VERSION "HNNBNNNYNNNNNNNNNNNNNNNNNNNNNNNNNNNNNNNNNN/4/%%%/4/'%**4NNN///"

NS_ :

BS_:

BU_: BAP_Tester BCM1 Gateway Klima_MSB Lift_VA VAS_L VAS_R

BO_ 427 ESP_33: 8 Gateway
 SG_ ESP_33_CRC : 0|8@1+ (1,0) [0|255] ""  Vector__XXX
 SG_ ESP_33_BZ : 8|4@1+ (1,0) [0|15] ""  Vector__XXX
 SG_ ESC_AHW_aktiv : 12|3@1+ (1.0,0.0) [0.0|7] ""  BCM1
 SG_ ESC_AHW_nicht_verfuegbar : 15|1@1+ (1.0,0.0) [0.0|1] ""  BCM1
 SG_ ESC_ANB_CM_aktiv : 16|2@1+ (1.0,0.0) [0.0|3] ""  Vector__XXX
 SG_ ESC_ANB_CM_nicht_verfuegbar : 18|1@1+ (1.0,0.0) [0.0|1] ""  Vector__XXX
 SG_ ESC_Warnruck_aktiv : 19|4@1+ (1.0,0.0) [0.0|15] ""  Vector__XXX
 SG_ ESC_Warnruck_nicht_verfuegbar : 23|1@1+ (1.0,0.0) [0.0|1] ""  Vector__XXX
 SG_ ESC_Prefill_aktiv : 24|1@1+ (1.0,0.0) [0.0|1] ""  Vector__XXX
 SG_ ESC_Prefill_nicht_verfuegbar : 25|1@1+ (1.0,0.0) [0.0|1] ""  Vector__XXX
 SG_ ESC_HBA_aktiv : 26|1@1+ (1.0,0.0) [0.0|1] ""  Vector__XXX
 SG_ ESC_HBA_nicht_verfuegbar : 27|1@1+ (1.0,0.0) [0.0|1] ""  Vector__XXX
 SG_ ESC_TSK_SRBM_Anf : 28|1@1+ (1.0,0.0) [0.0|1] ""  Vector__XXX
 SG_ ESC_TSK_SRBM_nicht_verfuegbar : 29|1@1+ (1.0,0.0) [0.0|1] ""  Vector__XXX
 SG_ ESC_Verz_Reg_aktiv : 30|4@1+ (1.0,0.0) [0.0|15] ""  BCM1
 SG_ ESC_Verz_Reg_nicht_verfuegbar : 34|1@1+ (1.0,0.0) [0.0|1] ""  BCM1
 SG_ ESC_Verz_Reg_TB_nicht_verfuegbar : 35|1@1+ (1.0,0.0) [0.0|1] ""  BCM1
 SG_ ESC_Verz_Reg_ZB_nicht_verfuegbar : 36|1@1+ (1.0,0.0) [0.0|1] ""  BCM1
 SG_ ESC_Bremslicht_unplausibel : 37|1@1+ (1.0,0.0) [0.0|1] ""  Vector__XXX
 SG_ ESC_Konsistenz_ACC : 38|1@1+ (1.0,0.0) [0.0|1] ""  Vector__XXX
 SG_ ESC_Konsistenz_AWV : 39|1@1+ (1.0,0.0) [0.0|1] ""  Vector__XXX
 SG_ ESC_Konsistenz_ARA : 40|1@1+ (1.0,0.0) [0.0|1] ""  BCM1
 SG_ ESC_Konsistenz_IPA : 41|1@1+ (1.0,0.0) [0.0|1] ""  BCM1
 SG_ ESC_Konsistenz_FCW : 42|1@1+ (1.0,0.0) [0.0|1] ""  Vector__XXX
 SG_ ESC_Konsistenz_NV : 43|1@1+ (1.0,0.0) [0.0|1] ""  Vector__XXX
 SG_ ESC_Konsistenz_RCTA : 44|1@1+ (1.0,0.0) [0.0|1] ""  Vector__XXX
 SG_ ESC_Konsistenz_TSK : 45|1@1+ (1.0,0.0) [0.0|1] ""  Vector__XXX
 SG_ ESC_Konsistenz_vFGS : 46|1@1+ (1.0,0.0) [0.0|1] ""  Vector__XXX
 SG_ ESC_Konsistenz_STA : 47|1@1+ (1.0,0.0) [0.0|1] ""  Vector__XXX
 SG_ ESC_Fahrer_Bremsdruck_bestimmend : 48|1@1+ (1.0,0.0) [0.0|1] ""  BCM1
 SG_ ESC_Konsistenz_EA : 49|1@1+ (1.0,0.0) [0.0|1] ""  Vector__XXX
 SG_ ESC_Konsistenz_BFF : 50|1@1+ (1.0,0.0) [0.0|1] ""  Vector__XXX
 SG_ ESC_Konsistenz_MKB : 51|1@1+ (1.0,0.0) [0.0|1] ""  Vector__XXX
 SG_ ESC_Verz_ASIL_Verfuegbarkeit : 52|3@1+ (1.0,0.0) [0.0|7] ""  BCM1
 SG_ ESC_Pumpenanlauf_aktiv : 55|1@1+ (1.0,0.0) [0.0|1] ""  Vector__XXX
 SG_ ESC_Konsistenz_AGW : 56|1@1+ (1.0,0.0) [0.0|1] ""  Vector__XXX
 SG_ ESC_Konsistenz_KAS : 57|1@1+ (1.0,0.0) [0.0|1] ""  Vector__XXX
 SG_ ESC_Konsistenz_PCF : 58|1@1+ (1.0,0.0) [0.0|1] ""  Vector__XXX
 SG_ ESC_Konsistenz_FAS_VK : 59|1@1+ (1.0,0.0) [0.0|1] ""  Vector__XXX
 SG_ ESC_Verz_Begrenzung : 60|1@1+ (1.0,0.0) [0.0|1] ""  Vector__XXX
 SG_ ESC_Konsistenz_AWA : 61|1@1+ (1.0,0.0) [0.0|1] ""  Vector__XXX

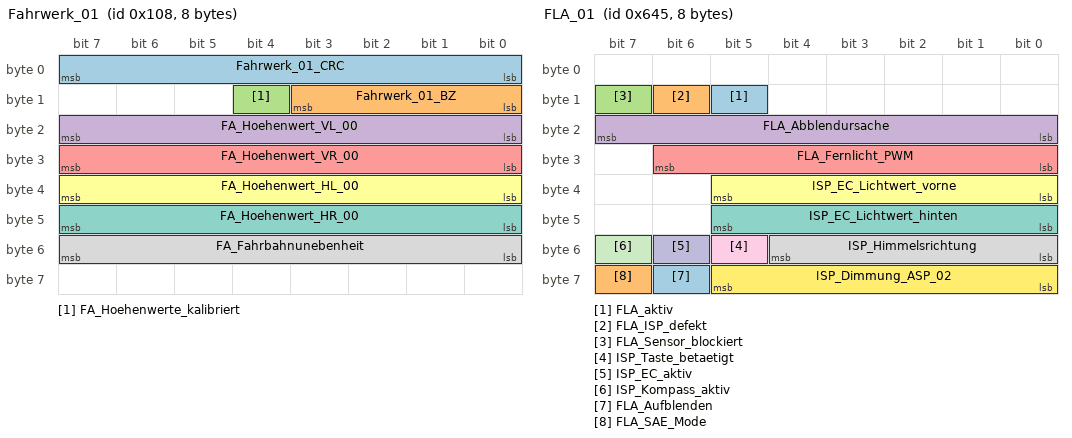
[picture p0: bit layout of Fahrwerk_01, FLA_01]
BO_ 264 Fahrwerk_01: 8 Gateway
 SG_ Fahrwerk_01_CRC : 0|8@1+ (1,0) [0|255] ""  Vector__XXX
 SG_ Fahrwerk_01_BZ : 8|4@1+ (1,0) [0|15] ""  Vector__XXX
 SG_ FA_Hoehenwerte_kalibriert : 12|1@1+ (1.0,0.0) [0.0|1] ""  BCM1,Lift_VA,VAS_L,VAS_R
 SG_ FA_Hoehenwert_VL_00 : 16|8@1+ (1,-127) [-127|126] "Unit_MilliMeter"  BCM1,Lift_VA,VAS_L,VAS_R
 SG_ FA_Hoehenwert_VR_00 : 24|8@1+ (1,-127) [-127|126] "Unit_MilliMeter"  Lift_VA,VAS_L,VAS_R
 SG_ FA_Hoehenwert_HL_00 : 32|8@1+ (1,-127) [-127|126] "Unit_MilliMeter"  BCM1,Lift_VA,VAS_L,VAS_R
 SG_ FA_Hoehenwert_HR_00 : 40|8@1+ (1,-127) [-127|126] "Unit_MilliMeter"  Lift_VA,VAS_L,VAS_R
 SG_ FA_Fahrbahnunebenheit : 48|8@1+ (1,0) [0|253] ""  Vector__XXX

BO_ 429 Fahrwerk_06: 8 Gateway
 SG_ Fahrwerk_06_CRC : 0|8@1+ (1,0) [0|255] ""  Vector__XXX
 SG_ Fahrwerk_06_BZ : 8|4@1+ (1,0) [0|15] ""  Vector__XXX
 SG_ NR_Reglerstatus : 12|4@1+ (1.0,0.0) [0.0|15] ""  BCM1
 SG_ FA_Verstellung_in_Kuerze : 16|1@1+ (1.0,0.0) [0.0|1] ""  Vector__XXX
 SG_ FA_Verstellung_aktiv : 17|1@1+ (1.0,0.0) [0.0|1] ""  Vector__XXX
 SG_ FA_Kompressor_laeuft_in_Kuerze : 18|1@1+ (1.0,0.0) [0.0|1] ""  Vector__XXX
 SG_ FA_Kompressor_laeuft : 19|1@1+ (1.0,0.0) [0.0|1] ""  Vector__XXX
 SG_ NR_Anforderung_v_Begrenzung : 20|2@1+ (1.0,0.0) [0.0|3] ""  Vector__XXX
 SG_ NR_LED_SGN : 22|1@1+ (1.0,0.0) [0.0|1] ""  BCM1
 SG_ NR_LED_TN : 23|1@1+ (1.0,0.0) [0.0|1] ""  BCM1
 SG_ NR_LED_BN : 24|1@1+ (1.0,0.0) [0.0|1] ""  BCM1
 SG_ FA_Absenkung_Fahrzeug : 25|1@1+ (1.0,0.0) [0.0|1] ""  Vector__XXX
 SG_ FA_Anhaengerstatus_intern : 26|3@1+ (1.0,0.0) [0.0|7] ""  Vector__XXX
 SG_ FA_Anhebung_Fahrzeug : 29|1@1+ (1.0,0.0) [0.0|1] ""  Vector__XXX
 SG_ FA_Druckspeicher_verfuegbar : 30|1@1+ (1.0,0.0) [0.0|1] ""  Vector__XXX
 SG_ FA_HAL_Abschaltung : 31|1@1+ (1.0,0.0) [0.0|1] ""  Vector__XXX
 SG_ FA_ESP_Zuschaltung : 32|1@1+ (1.0,0.0) [0.0|1] ""  Vector__XXX
 SG_ NR_LED_HN : 33|1@1+ (1.0,0.0) [0.0|1] ""  BCM1
 SG_ FA_Zwischenniveau : 34|1@1+ (1.0,0.0) [0.0|1] ""  Vector__XXX
 SG_ FA_Systemstatus : 35|1@1+ (1.0,0.0) [0.0|1] ""  Vector__XXX
 SG_ EFP_Soll_FahrPr_HAL : 36|4@1+ (1.0,0.0) [0.0|15] ""  Vector__XXX
 SG_ NR_Kompressor_Strom_02 : 40|8@1+ (0.2,0) [0.0|50.8] "Unit_Amper"  Vector__XXX
 SG_ NR_Kompressor_Temp_Zylinderkopf : 48|8@1+ (1,-40) [-40|213] "Unit_DegreCelsi"  Vector__XXX
 SG_ FA_Signal_Drucksensor : 56|8@1+ (0.1,0) [0.0|25.3] "Unit_Bar"  Vector__XXX

BO_ 1605 FLA_01: 8 Gateway
 SG_ FLA_aktiv : 13|1@1+ (1.0,0.0) [0.0|1] ""  BCM1
 SG_ FLA_ISP_defekt : 14|1@1+ (1.0,0.0) [0.0|1] ""  BCM1
 SG_ FLA_Sensor_blockiert : 15|1@1+ (1.0,0.0) [0.0|1] ""  BCM1
 SG_ FLA_Abblendursache : 16|8@1+ (1.0,0.0) [0.0|255] ""  Vector__XXX
 SG_ FLA_Fernlicht_PWM : 24|7@1+ (1,0) [0|100] "Unit_PerCent"  BCM1
 SG_ ISP_EC_Lichtwert_vorne : 32|6@1+ (1,0) [0|61] "Unit_None"  Vector__XXX
 SG_ ISP_EC_Lichtwert_hinten : 40|6@1+ (1,0) [0|61] "Unit_None"  Vector__XXX
 SG_ ISP_Himmelsrichtung : 48|5@1+ (12,0) [0|348] "Unit_DegreOfArc"  Vector__XXX
 SG_ ISP_Taste_betaetigt : 53|1@1+ (1.0,0.0) [0.0|1] ""  Vector__XXX
 SG_ ISP_EC_aktiv : 54|1@1+ (1.0,0.0) [0.0|1] ""  Vector__XXX
 SG_ ISP_Kompass_aktiv : 55|1@1+ (1.0,0.0) [0.0|1] ""  Vector__XXX
 SG_ ISP_Dimmung_ASP_02 : 56|6@1+ (0.0226,0) [0.0000|1.4012] "Unit_Volt"  Vector__XXX
 SG_ FLA_Aufblenden : 62|1@1+ (1.0,0.0) [0.0|1] ""  BCM1
 SG_ FLA_SAE_Mode : 63|1@1+ (1.0,0.0) [0.0|1] ""  Vector__XXX

BO_ 2589283684 FoD_01: 8 Gateway
 SG_ FoD_Transmission_Info : 60|2@1+ (1.0,0.0) [0.0|3] ""  BCM1
 SG_ FoD_Anz_Funktionsabschaltung : 62|2@1+ (1.0,0.0) [0.0|3] ""  Vector__XXX

BO_ 2549875470 FoD_BCM1_Req: 8 Gateway
 SG_ FoD_BCM1_Req_Data : 0|64@1+ (1.0,0.0) [0.0|18446744073709551615] ""  BCM1

BO_ 2550006542 FoD_BCM1_Resp: 8 BCM1
 SG_ FoD_BCM1_Resp_Data : 0|64@1+ (1.0,0.0) [0.0|18446744073709551615] ""  Gateway

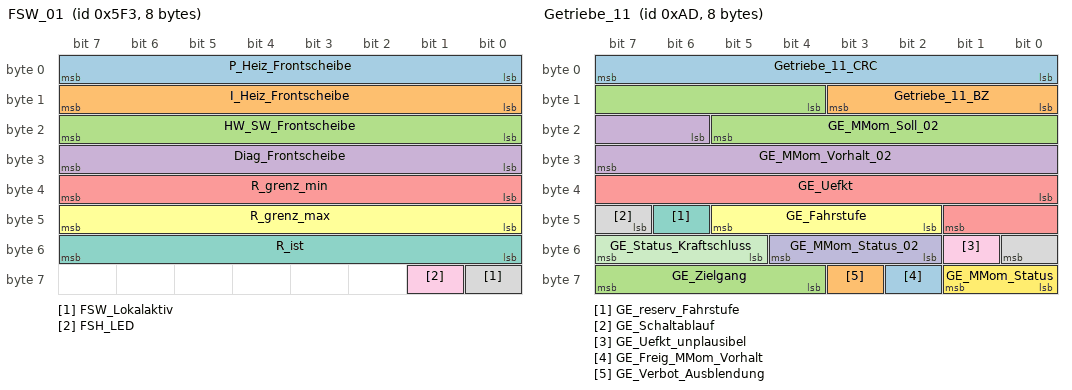
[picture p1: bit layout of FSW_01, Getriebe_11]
BO_ 1523 FSW_01: 8 Gateway
 SG_ P_Heiz_Frontscheibe : 0|8@1+ (10,0) [0|2500] "Unit_Watt"  Vector__XXX
 SG_ I_Heiz_Frontscheibe : 8|8@1+ (0.5,0) [0.0|125.0] "Unit_Amper"  BCM1
 SG_ HW_SW_Frontscheibe : 16|8@1+ (1.0,0.0) [0.0|255] ""  Vector__XXX
 SG_ Diag_Frontscheibe : 24|8@1+ (1.0,0.0) [0.0|255] ""  Vector__XXX
 SG_ R_grenz_min : 32|8@1+ (0.05,0) [0.00|10.00] "Unit_Ohm"  Vector__XXX
 SG_ R_grenz_max : 40|8@1+ (0.05,0) [0.00|10.00] "Unit_Ohm"  Vector__XXX
 SG_ R_ist : 48|8@1+ (0.05,0) [0.00|10.00] "Unit_Ohm"  Vector__XXX
 SG_ FSW_Lokalaktiv : 56|1@1+ (1.0,0.0) [0.0|1] ""  Vector__XXX
 SG_ FSH_LED : 57|1@1+ (1.0,0.0) [0.0|1] ""  Vector__XXX

BO_ 173 Getriebe_11: 8 Gateway
 SG_ Getriebe_11_CRC : 0|8@1+ (1,0) [0|255] ""  Vector__XXX
 SG_ Getriebe_11_BZ : 8|4@1+ (1,0) [0|15] ""  Vector__XXX
 SG_ GE_MMom_Soll_02 : 12|10@1+ (1,-509) [-509|509] ""  Vector__XXX
 SG_ GE_MMom_Vorhalt_02 : 22|10@1+ (1,-509) [-509|509] ""  Vector__XXX
 SG_ GE_Uefkt : 32|10@1+ (0.1,0) [0.0|102.2] ""  Vector__XXX
 SG_ GE_Fahrstufe : 42|4@1+ (1.0,0.0) [0.0|15] ""  BCM1
 SG_ GE_reserv_Fahrstufe : 46|1@1+ (1,0) [0|1] ""  Vector__XXX
 SG_ GE_Schaltablauf : 47|2@1+ (1.0,0.0) [0.0|3] ""  Vector__XXX
 SG_ GE_Uefkt_unplausibel : 49|1@1+ (1.0,0.0) [0.0|1] ""  Vector__XXX
 SG_ GE_MMom_Status_02 : 50|3@1+ (1.0,0.0) [0.0|7] ""  Vector__XXX
 SG_ GE_Status_Kraftschluss : 53|3@1+ (1.0,0.0) [0.0|7] ""  Vector__XXX
 SG_ GE_MMom_Status : 56|2@1+ (1.0,0.0) [0.0|3] ""  Vector__XXX
 SG_ GE_Freig_MMom_Vorhalt : 58|1@1+ (1.0,0.0) [0.0|1] ""  Vector__XXX
 SG_ GE_Verbot_Ausblendung : 59|1@1+ (1.0,0.0) [0.0|1] ""  Vector__XXX
 SG_ GE_Zielgang : 60|4@1+ (1.0,0.0) [0.0|15] ""  BCM1

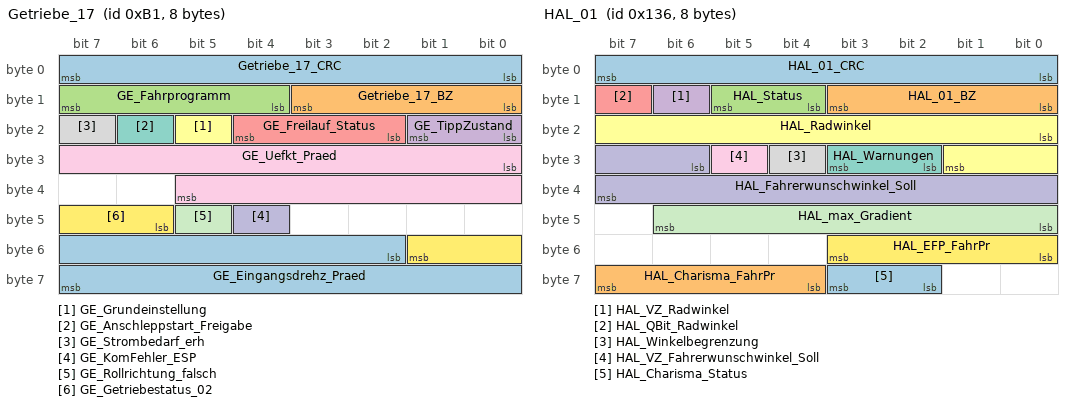
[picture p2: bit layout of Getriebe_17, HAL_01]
BO_ 177 Getriebe_17: 8 Gateway
 SG_ Getriebe_17_CRC : 0|8@1+ (1,0) [0|255] ""  Vector__XXX
 SG_ Getriebe_17_BZ : 8|4@1+ (1,0) [0|15] ""  Vector__XXX
 SG_ GE_Fahrprogramm : 12|4@1+ (1.0,0.0) [0.0|15] ""  Vector__XXX
 SG_ GE_TippZustand : 16|2@1+ (1.0,0.0) [0.0|3] ""  Vector__XXX
 SG_ GE_Freilauf_Status : 18|3@1+ (1.0,0.0) [0.0|7] ""  BCM1,Klima_MSB
 SG_ GE_Grundeinstellung : 21|1@1+ (1.0,0.0) [0.0|1] ""  Vector__XXX
 SG_ GE_Anschleppstart_Freigabe : 22|1@1+ (1.0,0.0) [0.0|1] ""  Vector__XXX
 SG_ GE_Strombedarf_erh : 23|1@1+ (1.0,0.0) [0.0|1] ""  Vector__XXX
 SG_ GE_Uefkt_Praed : 24|14@1+ (0.008,0) [0.000|131.056] ""  Vector__XXX
 SG_ GE_KomFehler_ESP : 44|1@1+ (1.0,0.0) [0.0|1] ""  Vector__XXX
 SG_ GE_Rollrichtung_falsch : 45|1@1+ (1.0,0.0) [0.0|1] ""  Vector__XXX
 SG_ GE_Getriebestatus_02 : 46|4@1+ (1.0,0.0) [0.0|15] ""  Vector__XXX
 SG_ GE_Eingangsdrehz_Praed : 50|14@1+ (1,0) [0|16381] "Unit_MinutInver"  Vector__XXX

BO_ 310 HAL_01: 8 Gateway
 SG_ HAL_01_CRC : 0|8@1+ (1,0) [0|255] ""  BCM1
 SG_ HAL_01_BZ : 8|4@1+ (1,0) [0|15] ""  BCM1
 SG_ HAL_Status : 12|2@1+ (1.0,0.0) [0.0|3] ""  BCM1
 SG_ HAL_VZ_Radwinkel : 14|1@1+ (1.0,0.0) [0.0|1] ""  BCM1
 SG_ HAL_QBit_Radwinkel : 15|1@1+ (1.0,0.0) [0.0|1] ""  BCM1
 SG_ HAL_Radwinkel : 16|10@1+ (0.01,0) [0.00|10.19] "Unit_DegreOfArc"  BCM1
 SG_ HAL_Warnungen : 26|2@1+ (1.0,0.0) [0.0|3] ""  Vector__XXX
 SG_ HAL_Winkelbegrenzung : 28|1@1+ (1.0,0.0) [0.0|1] ""  Vector__XXX
 SG_ HAL_VZ_Fahrerwunschwinkel_Soll : 29|1@1+ (1.0,0.0) [0.0|1] ""  BCM1
 SG_ HAL_Fahrerwunschwinkel_Soll : 30|10@1+ (0.01,0) [0.00|10.21] "Unit_DegreOfArc"  BCM1
 SG_ HAL_max_Gradient : 40|7@1+ (0.1,0) [0.0|12.5] "Unit_DegreOfArcPerSecon"  BCM1
 SG_ HAL_EFP_FahrPr : 48|4@1+ (1.0,0.0) [0.0|15] ""  Vector__XXX
 SG_ HAL_Charisma_Status : 58|2@1+ (1.0,0.0) [0.0|3] ""  Vector__XXX
 SG_ HAL_Charisma_FahrPr : 60|4@1+ (1.0,0.0) [0.0|15] ""  Vector__XXX

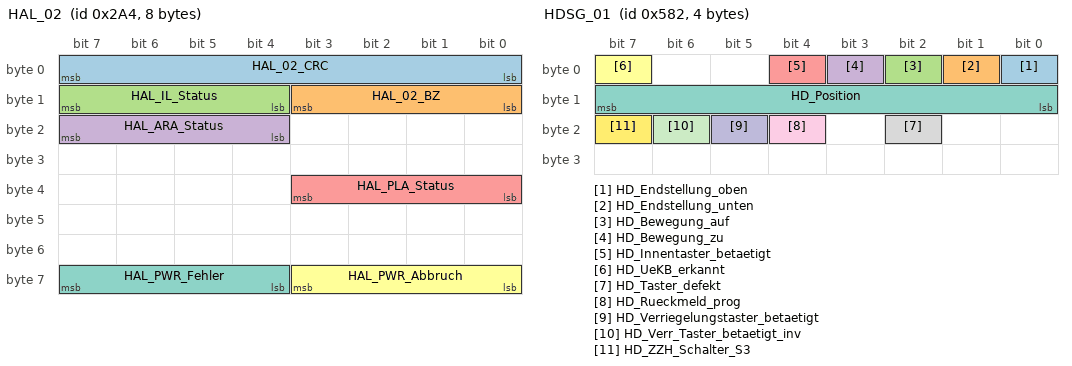
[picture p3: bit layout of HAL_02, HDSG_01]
BO_ 676 HAL_02: 8 Gateway
 SG_ HAL_02_CRC : 0|8@1+ (1,0) [0|255] ""  BCM1
 SG_ HAL_02_BZ : 8|4@1+ (1,0) [0|15] ""  BCM1
 SG_ HAL_IL_Status : 12|4@1+ (1.0,0.0) [0.0|15] ""  Vector__XXX
 SG_ HAL_ARA_Status : 20|4@1+ (1.0,0.0) [0.0|15] ""  BCM1
 SG_ HAL_PLA_Status : 32|4@1+ (1.0,0.0) [0.0|15] ""  BCM1
 SG_ HAL_PWR_Abbruch : 56|4@1+ (1.0,0.0) [0.0|15] ""  BCM1
 SG_ HAL_PWR_Fehler : 60|4@1+ (1.0,0.0) [0.0|15] ""  BCM1

BO_ 1410 HDSG_01: 4 Gateway
 SG_ HD_Endstellung_oben : 0|1@1+ (1.0,0.0) [0.0|1] ""  BCM1
 SG_ HD_Endstellung_unten : 1|1@1+ (1.0,0.0) [0.0|1] ""  BCM1
 SG_ HD_Bewegung_auf : 2|1@1+ (1.0,0.0) [0.0|1] ""  Vector__XXX
 SG_ HD_Bewegung_zu : 3|1@1+ (1.0,0.0) [0.0|1] ""  BCM1,Klima_MSB
 SG_ HD_Innentaster_betaetigt : 4|1@1+ (1.0,0.0) [0.0|1] ""  Vector__XXX
 SG_ HD_UeKB_erkannt : 7|1@1+ (1.0,0.0) [0.0|1] ""  Vector__XXX
 SG_ HD_Position : 8|8@1+ (1,0) [0|100] "Unit_PerCent"  BCM1
 SG_ HD_Taster_defekt : 18|1@1+ (1.0,0.0) [0.0|1] ""  Vector__XXX
 SG_ HD_Rueckmeld_prog : 20|1@1+ (1.0,0.0) [0.0|1] ""  Vector__XXX
 SG_ HD_Verriegelungstaster_betaetigt : 21|1@1+ (1.0,0.0) [0.0|1] ""  Vector__XXX
 SG_ HD_Verr_Taster_betaetigt_inv : 22|1@1+ (1.0,0.0) [0.0|1] ""  Vector__XXX
 SG_ HD_ZZH_Schalter_S3 : 23|1@1+ (1.0,0.0) [0.0|1] ""  Vector__XXX

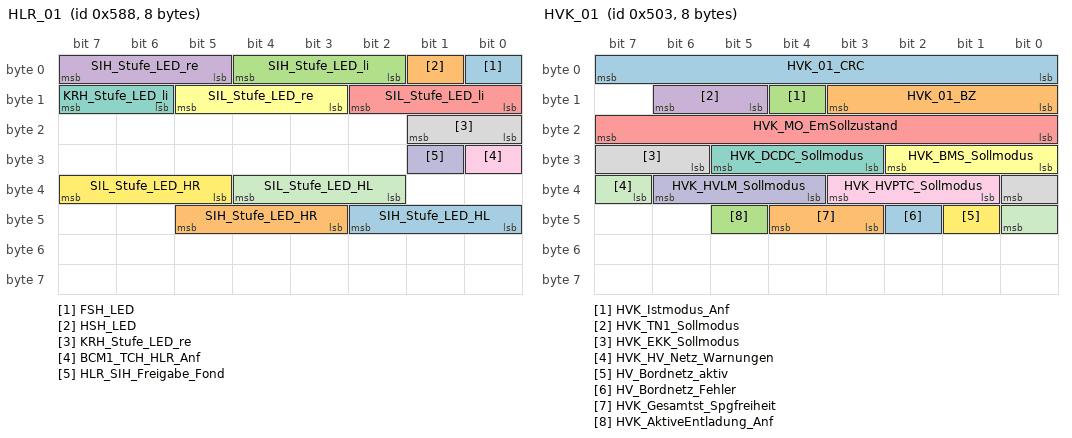
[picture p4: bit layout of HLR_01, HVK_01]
BO_ 1416 HLR_01: 8 BCM1
 SG_ FSH_LED : 0|1@1+ (1.0,0.0) [0.0|1] ""  Gateway
 SG_ HSH_LED : 1|1@1+ (1.0,0.0) [0.0|1] ""  Gateway
 SG_ SIH_Stufe_LED_li : 2|3@1+ (1.0,0.0) [0.0|7] ""  Gateway,Klima_MSB
 SG_ SIH_Stufe_LED_re : 5|3@1+ (1.0,0.0) [0.0|7] ""  Gateway,Klima_MSB
 SG_ SIL_Stufe_LED_li : 8|3@1+ (1.0,0.0) [0.0|7] ""  Gateway,Klima_MSB
 SG_ SIL_Stufe_LED_re : 11|3@1+ (1.0,0.0) [0.0|7] ""  Gateway,Klima_MSB
 SG_ KRH_Stufe_LED_li : 14|2@1+ (1.0,0.0) [0.0|3] ""  Gateway,Klima_MSB
 SG_ KRH_Stufe_LED_re : 16|2@1+ (1.0,0.0) [0.0|3] ""  Gateway,Klima_MSB
 SG_ BCM1_TCH_HLR_Anf : 24|1@1+ (1.0,0.0) [0.0|1] ""  Gateway
 SG_ HLR_SIH_Freigabe_Fond : 25|1@1+ (1.0,0.0) [0.0|1] ""  Gateway
 SG_ SIL_Stufe_LED_HL : 34|3@1+ (1.0,0.0) [0.0|7] ""  Gateway,Klima_MSB
 SG_ SIL_Stufe_LED_HR : 37|3@1+ (1.0,0.0) [0.0|7] ""  Gateway,Klima_MSB
 SG_ SIH_Stufe_LED_HL : 40|3@1+ (1.0,0.0) [0.0|7] ""  Gateway,Klima_MSB
 SG_ SIH_Stufe_LED_HR : 43|3@1+ (1.0,0.0) [0.0|7] ""  Gateway,Klima_MSB

BO_ 1016 HLR_02: 8 Gateway
 SG_ HLR_FlHz_Freigabe_Ruhesitz : 14|2@1+ (1.0,0.0) [0.0|3] ""  BCM1
 SG_ HLR_FlHz_Freigabe_VR : 16|2@1+ (1.0,0.0) [0.0|3] ""  BCM1
 SG_ HLR_FlHz_Freigabe_VL : 18|2@1+ (1.0,0.0) [0.0|3] ""  BCM1
 SG_ HLR_FlHz_Freigabe_HR : 20|2@1+ (1.0,0.0) [0.0|3] ""  BCM1
 SG_ HLR_FlHz_Freigabe_HL : 22|2@1+ (1.0,0.0) [0.0|3] ""  BCM1
 SG_ HLR_TCH_Freigabe : 24|1@1+ (1.0,0.0) [0.0|1] ""  BCM1
 SG_ HLR_SIH_Freigabe_Fond : 25|1@1+ (1.0,0.0) [0.0|1] ""  BCM1
 SG_ HLR_Sp_Heizung_Freigabe_BT : 26|1@1+ (1.0,0.0) [0.0|1] ""  Vector__XXX
 SG_ HLR_Sp_Heizung_Freigabe_FT : 27|1@1+ (1.0,0.0) [0.0|1] ""  Vector__XXX
 SG_ HLR_KRH_Freigabe_VL : 28|2@1+ (1.0,0.0) [0.0|3] ""  BCM1
 SG_ HLR_KRH_Freigabe_VR : 30|2@1+ (1.0,0.0) [0.0|3] ""  BCM1
 SG_ HLR_SIH_Freigabe_VL : 32|2@1+ (1.0,0.0) [0.0|3] ""  BCM1
 SG_ HLR_SIH_Freigabe_VR : 34|2@1+ (1.0,0.0) [0.0|3] ""  BCM1
 SG_ HLR_SIH_Freigabe_HL : 36|2@1+ (1.0,0.0) [0.0|3] ""  BCM1,Klima_MSB
 SG_ HLR_SIH_Freigabe_HR : 38|2@1+ (1.0,0.0) [0.0|3] ""  BCM1,Klima_MSB
 SG_ HLR_SIL_Freigabe_VL : 40|2@1+ (1.0,0.0) [0.0|3] ""  BCM1
 SG_ HLR_SIL_Freigabe_VR : 42|2@1+ (1.0,0.0) [0.0|3] ""  BCM1
 SG_ HLR_SIL_Freigabe_HL : 44|2@1+ (1.0,0.0) [0.0|3] ""  BCM1,Klima_MSB
 SG_ HLR_SIL_Freigabe_HR : 46|2@1+ (1.0,0.0) [0.0|3] ""  BCM1,Klima_MSB
 SG_ HLR_FSH_Freigabe : 48|6@1+ (20,0) [20|1240] "Unit_Watt"  BCM1,Klima_MSB
 SG_ HLR_HSH_Freigabe : 54|1@1+ (1.0,0.0) [0.0|1] ""  Vector__XXX
 SG_ HLR_LRH_Freigabe : 55|1@1+ (1.0,0.0) [0.0|1] ""  Vector__XXX
 SG_ HLR_PTC_linear_Freigabe : 56|6@1+ (50,0) [0|3100] "Unit_Watt"  BCM1,Klima_MSB
 SG_ HLR_PTC_Freigabe : 62|2@1+ (1.0,0.0) [0.0|3] ""  BCM1

BO_ 1283 HVK_01: 8 Gateway
 SG_ HVK_01_CRC : 0|8@1+ (1,0) [0|255] ""  Vector__XXX
 SG_ HVK_01_BZ : 8|4@1+ (1,0) [0|15] ""  Vector__XXX
 SG_ HVK_Istmodus_Anf : 12|1@1+ (1.0,0.0) [0.0|1] ""  Vector__XXX
 SG_ HVK_TN1_Sollmodus : 13|2@1+ (1.0,0.0) [0.0|3] ""  Vector__XXX
 SG_ HVK_MO_EmSollzustand : 16|8@1+ (1.0,0.0) [0.0|255] ""  Vector__XXX
 SG_ HVK_BMS_Sollmodus : 24|3@1+ (1.0,0.0) [0.0|7] ""  Vector__XXX
 SG_ HVK_DCDC_Sollmodus : 27|3@1+ (1.0,0.0) [0.0|7] ""  Vector__XXX
 SG_ HVK_EKK_Sollmodus : 30|3@1+ (1.0,0.0) [0.0|7] ""  Vector__XXX
 SG_ HVK_HVPTC_Sollmodus : 33|3@1+ (1.0,0.0) [0.0|7] ""  BCM1,Klima_MSB
 SG_ HVK_HVLM_Sollmodus : 36|3@1+ (1.0,0.0) [0.0|7] ""  Vector__XXX
 SG_ HVK_HV_Netz_Warnungen : 39|2@1+ (1.0,0.0) [0.0|3] ""  Vector__XXX
 SG_ HV_Bordnetz_aktiv : 41|1@1+ (1.0,0.0) [0.0|1] ""  Vector__XXX
 SG_ HV_Bordnetz_Fehler : 42|1@1+ (1.0,0.0) [0.0|1] ""  Vector__XXX
 SG_ HVK_Gesamtst_Spgfreiheit : 43|2@1+ (1.0,0.0) [0.0|3] ""  Vector__XXX
 SG_ HVK_AktiveEntladung_Anf : 45|1@1+ (1.0,0.0) [0.0|1] ""  Vector__XXX

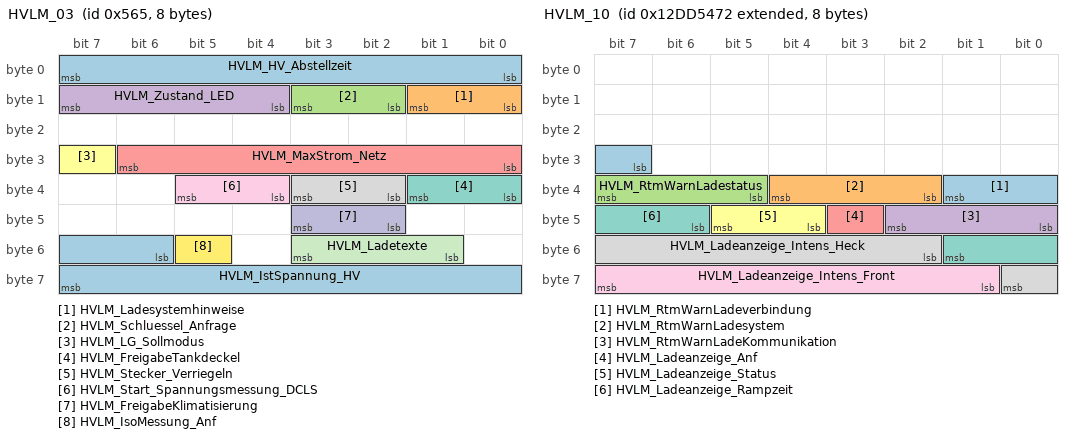
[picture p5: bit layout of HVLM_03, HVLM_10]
BO_ 1381 HVLM_03: 8 Gateway
 SG_ HVLM_HV_Abstellzeit : 0|8@1+ (4,0) [0|1012] "Unit_Minut"  Vector__XXX
 SG_ HVLM_Ladesystemhinweise : 8|2@1+ (1.0,0.0) [0.0|3] ""  Vector__XXX
 SG_ HVLM_Schluessel_Anfrage : 10|2@1+ (1.0,0.0) [0.0|3] ""  Vector__XXX
 SG_ HVLM_Zustand_LED : 12|4@1+ (1.0,0.0) [0.0|15] ""  Vector__XXX
 SG_ HVLM_MaxStrom_Netz : 24|7@1+ (0.5,0) [0.0|62.5] "Unit_Amper"  Vector__XXX
 SG_ HVLM_LG_Sollmodus : 31|1@1+ (1.0,0.0) [0.0|1] ""  Vector__XXX
 SG_ HVLM_FreigabeTankdeckel : 32|2@1+ (1.0,0.0) [0.0|3] ""  Vector__XXX
 SG_ HVLM_Stecker_Verriegeln : 34|2@1+ (1.0,0.0) [0.0|3] ""  Vector__XXX
 SG_ HVLM_Start_Spannungsmessung_DCLS : 36|2@1+ (1.0,0.0) [0.0|3] ""  Vector__XXX
 SG_ HVLM_FreigabeKlimatisierung : 42|2@1+ (1.0,0.0) [0.0|3] ""  BCM1,Klima_MSB
 SG_ HVLM_Ladetexte : 49|3@1+ (1.0,0.0) [0.0|7] ""  Vector__XXX
 SG_ HVLM_IsoMessung_Anf : 53|1@1+ (1.0,0.0) [0.0|1] ""  Vector__XXX
 SG_ HVLM_IstSpannung_HV : 54|10@1+ (1,0) [0|1021] "Unit_Volt"  Vector__XXX

BO_ 1340 HVLM_04: 8 Gateway
 SG_ HVLM_04_CRC : 0|8@1+ (1,0) [0|255] ""  Vector__XXX
 SG_ HVLM_04_BZ : 8|4@1+ (1,0) [0|15] ""  Vector__XXX
 SG_ HVLM_STH_Betriebsmodus : 12|3@1+ (1.0,0.0) [0.0|7] ""  BCM1,Klima_MSB
 SG_ HVLM_Standklima_Timer_Status : 15|1@1+ (1.0,0.0) [0.0|1] ""  BCM1,Klima_MSB
 SG_ HVLM_HVEM_MaxLeistung : 16|9@1+ (50,0) [0|25450] "Unit_Watt"  Vector__XXX
 SG_ HVLM_Status_Netz : 25|1@1+ (1.0,0.0) [0.0|1] ""  Vector__XXX
 SG_ HVLM_Ladeart : 27|2@1+ (1.0,0.0) [0.0|3] ""  Vector__XXX
 SG_ HVLM_VK_STH_Einsatz : 29|3@1+ (1.0,0.0) [0.0|7] ""  BCM1
 SG_ HVLM_VK_Modus : 32|2@1+ (1.0,0.0) [0.0|3] ""  BCM1,Klima_MSB
 SG_ HVLM_IstModus_02 : 34|2@1+ (1.0,0.0) [0.0|3] ""  Vector__XXX
 SG_ HVLM_HV_Anf : 36|2@1+ (1.0,0.0) [0.0|3] ""  Vector__XXX
 SG_ HVLM_Fehlerstatus : 38|3@1+ (1.0,0.0) [0.0|7] ""  Vector__XXX
 SG_ HVLM_Anforderung_HMS : 41|3@1+ (1.0,0.0) [0.0|7] ""  Vector__XXX
 SG_ HVLM_Parken_beibehalten_HMS : 44|2@1+ (1.0,0.0) [0.0|3] ""  Vector__XXX
 SG_ HVLM_AWC_Sollmodus : 48|3@1+ (1.0,0.0) [0.0|7] ""  Vector__XXX
 SG_ HVLM_Stecker_Status : 51|2@1+ (1.0,0.0) [0.0|3] ""  Vector__XXX
 SG_ HVLM_LadeAnforderung : 53|3@1+ (1.0,0.0) [0.0|7] ""  Vector__XXX
 SG_ HVLM_MaxBatLadestromHV : 56|8@1+ (1,0) [0|253] "Unit_Amper"  Vector__XXX

BO_ 2589283485 HVLM_08: 8 Gateway
 SG_ HVLM_BattKond_Anf : 55|3@1+ (1.0,0.0) [0.0|7] ""  Vector__XXX
 SG_ HVLM_Dauer_Klima_02 : 58|6@1+ (1,0) [0|60] "Unit_Minut"  BCM1,Klima_MSB

BO_ 2463978610 HVLM_10: 8 Gateway
 SG_ HVLM_RtmWarnLadeverbindung : 31|3@1+ (1.0,0.0) [0.0|7] ""  Vector__XXX
 SG_ HVLM_RtmWarnLadesystem : 34|3@1+ (1.0,0.0) [0.0|7] ""  Vector__XXX
 SG_ HVLM_RtmWarnLadestatus : 37|3@1+ (1.0,0.0) [0.0|7] ""  Vector__XXX
 SG_ HVLM_RtmWarnLadeKommunikation : 40|3@1+ (1.0,0.0) [0.0|7] ""  Vector__XXX
 SG_ HVLM_Ladeanzeige_Anf : 43|1@1+ (1.0,0.0) [0.0|1] ""  BCM1
 SG_ HVLM_Ladeanzeige_Status : 44|2@1+ (1.0,0.0) [0.0|3] ""  BCM1
 SG_ HVLM_Ladeanzeige_Rampzeit : 46|4@1+ (50,0) [0|750] "Unit_MilliSecon"  Vector__XXX
 SG_ HVLM_Ladeanzeige_Intens_Heck : 50|7@1+ (1,0) [0|100] "Unit_PerCent"  Vector__XXX
 SG_ HVLM_Ladeanzeige_Intens_Front : 57|7@1+ (1,0) [0|100] "Unit_PerCent"  Vector__XXX

BO_ 1524 Innenlicht_11: 8 BCM1
 SG_ IL_Dimmung_V_Tuerkontur : 0|8@1+ (1,0) [0|100] "Unit_PerCent"  Gateway
 SG_ IL_Dimmung_H_Tuerkontur : 8|8@1+ (1,0) [0|100] "Unit_PerCent"  Gateway
 SG_ IL_Dimmung_Tuerinnengriff : 16|8@1+ (1,0) [0|100] "Unit_PerCent"  Gateway
 SG_ IL_Dimmung_Umfeldbel : 24|8@1+ (1,0) [0|100] "Unit_PerCent"  Gateway
 SG_ IL_Bel_FS_Ausstieg : 32|1@1+ (1.0,0.0) [0.0|1] ""  Gateway
 SG_ IL_Bel_BFS_Ausstieg : 33|1@1+ (1.0,0.0) [0.0|1] ""  Gateway
 SG_ IL_Bel_HFS_Ausstieg : 34|1@1+ (1.0,0.0) [0.0|1] ""  Gateway
 SG_ IL_Bel_HBFS_Ausstieg : 35|1@1+ (1.0,0.0) [0.0|1] ""  Gateway
 SG_ BCM1_Innenlicht_gedimmt_V : 36|1@1+ (1.0,0.0) [0.0|1] ""  Gateway
 SG_ BCM1_Innenlicht_gedimmt_H : 37|1@1+ (1.0,0.0) [0.0|1] ""  Gateway
 SG_ IL_Innenlicht_aktiv : 38|1@1+ (1.0,0.0) [0.0|1] ""  Gateway
 SG_ IL_Klemme_30G_aktiv : 39|1@1+ (1.0,0.0) [0.0|1] ""  Gateway
 SG_ BCM1_DI_Rampe_Innenlicht : 40|1@1+ (1.0,0.0) [0.0|1] ""  Gateway
 SG_ BCM1_DI_Rampe_Leselicht : 41|1@1+ (1.0,0.0) [0.0|1] ""  Gateway
 SG_ BCM1_Innenlicht_H : 42|1@1+ (1.0,0.0) [0.0|1] ""  Gateway
 SG_ BCM1_Innenlicht_V : 43|1@1+ (1.0,0.0) [0.0|1] ""  Gateway
 SG_ BCM1_Leselicht_Anf_hl : 44|1@1+ (1.0,0.0) [0.0|1] ""  Gateway
 SG_ BCM1_Leselicht_Anf_hr : 45|1@1+ (1.0,0.0) [0.0|1] ""  Gateway
 SG_ BCM1_Leselicht_Anf_vl : 46|1@1+ (1.0,0.0) [0.0|1] ""  Gateway
 SG_ BCM1_Leselicht_Anf_vr : 47|1@1+ (1.0,0.0) [0.0|1] ""  Gateway
 SG_ BCM1_Leuchten_Aus : 48|1@1+ (1.0,0.0) [0.0|1] ""  Gateway
 SG_ AMB_Charisma_FahrPr : 49|4@1+ (1.0,0.0) [0.0|15] ""  Gateway
 SG_ AMB_Charisma_Status : 53|2@1+ (1.0,0.0) [0.0|3] ""  Gateway
 SG_ IL_Dimmung_Lautspr : 56|8@1+ (1,0) [0|100] "Unit_PerCent"  Gateway

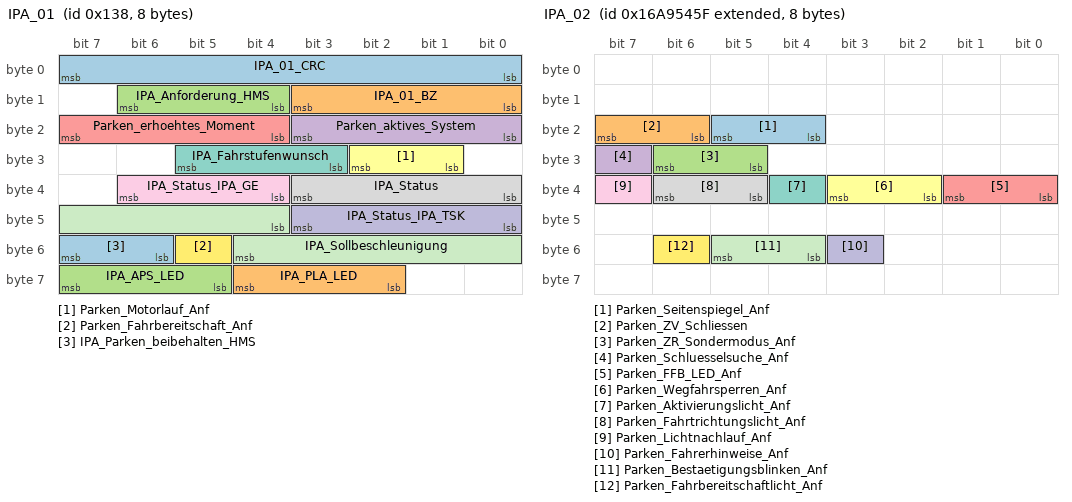
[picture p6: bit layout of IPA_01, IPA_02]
BO_ 312 IPA_01: 8 Gateway
 SG_ IPA_01_CRC : 0|8@1+ (1,0) [0|255] ""  Vector__XXX
 SG_ IPA_01_BZ : 8|4@1+ (1,0) [0|15] ""  Vector__XXX
 SG_ IPA_Anforderung_HMS : 12|3@1+ (1.0,0.0) [0.0|7] ""  Vector__XXX
 SG_ Parken_aktives_System : 16|4@1+ (1.0,0.0) [0.0|15] ""  BCM1
 SG_ Parken_erhoehtes_Moment : 20|4@1+ (1.0,0.0) [0.0|15] ""  Vector__XXX
 SG_ Parken_Motorlauf_Anf : 25|2@1+ (1.0,0.0) [0.0|3] ""  Vector__XXX
 SG_ IPA_Fahrstufenwunsch : 27|3@1+ (1.0,0.0) [0.0|7] ""  Vector__XXX
 SG_ IPA_Status : 32|4@1+ (1.0,0.0) [0.0|15] ""  Vector__XXX
 SG_ IPA_Status_IPA_GE : 36|3@1+ (1.0,0.0) [0.0|7] ""  Vector__XXX
 SG_ IPA_Status_IPA_TSK : 40|4@1+ (1.0,0.0) [0.0|15] ""  BCM1
 SG_ IPA_Sollbeschleunigung : 44|9@1+ (0.01,-4.11) [-4.10|1.00] "Unit_MeterPerSeconSquar"  Vector__XXX
 SG_ Parken_Fahrbereitschaft_Anf : 53|1@1+ (1.0,0.0) [0.0|1] ""  Vector__XXX
 SG_ IPA_Parken_beibehalten_HMS : 54|2@1+ (1.0,0.0) [0.0|3] ""  Vector__XXX
 SG_ IPA_PLA_LED : 58|3@1+ (1.0,0.0) [0.0|7] ""  BCM1
 SG_ IPA_APS_LED : 61|3@1+ (1.0,0.0) [0.0|7] ""  BCM1

BO_ 2527679583 IPA_02: 8 Gateway
 SG_ Parken_Seitenspiegel_Anf : 20|2@1+ (1.0,0.0) [0.0|3] ""  VAS_L,VAS_R
 SG_ Parken_ZV_Schliessen : 22|2@1+ (1.0,0.0) [0.0|3] ""  Vector__XXX
 SG_ Parken_ZR_Sondermodus_Anf : 29|2@1+ (1.0,0.0) [0.0|3] ""  Vector__XXX
 SG_ Parken_Schluesselsuche_Anf : 31|1@1+ (1.0,0.0) [0.0|1] ""  Vector__XXX
 SG_ Parken_FFB_LED_Anf : 32|2@1+ (1.0,0.0) [0.0|3] ""  Vector__XXX
 SG_ Parken_Wegfahrsperren_Anf : 34|2@1+ (1.0,0.0) [0.0|3] ""  Vector__XXX
 SG_ Parken_Aktivierungslicht_Anf : 36|1@1+ (1.0,0.0) [0.0|1] ""  BCM1
 SG_ Parken_Fahrtrichtungslicht_Anf : 37|2@1+ (1.0,0.0) [0.0|3] ""  BCM1
 SG_ Parken_Lichtnachlauf_Anf : 39|1@1+ (1.0,0.0) [0.0|1] ""  BCM1
 SG_ Parken_Fahrerhinweise_Anf : 51|1@1+ (1.0,0.0) [0.0|1] ""  Vector__XXX
 SG_ Parken_Bestaetigungsblinken_Anf : 52|2@1+ (1.0,0.0) [0.0|3] ""  BCM1
 SG_ Parken_Fahrbereitschaftlicht_Anf : 54|1@1+ (1.0,0.0) [0.0|1] ""  BCM1

BO_ 1806 ISO_BCM1_Req: 8 Gateway
 SG_ ISO_BCM1_Req_Data : 0|64@1+ (1.0,0.0) [0.0|18446744073709551615] ""  BCM1

BO_ 1912 ISO_BCM1_Resp: 8 BCM1
 SG_ ISO_BCM1_Resp_Data : 0|64@1+ (1.0,0.0) [0.0|18446744073709551615] ""  Gateway

BO_ 1792 ISO_Funktionaler_Req_All: 8 Gateway
 SG_ ISO_ALL_01_Req_Data : 0|64@1+ (1.0,0.0) [0.0|18446744073709551615] ""  BCM1,Klima_MSB,Lift_VA,VAS_L,VAS_R

BO_ 1862 ISO_Klima_Req: 8 Gateway
 SG_ ISO_Klima_Req_Data : 0|64@1+ (1.0,0.0) [0.0|18446744073709551615] ""  Klima_MSB

BO_ 1968 ISO_Klima_Resp: 8 Klima_MSB
 SG_ ISO_Klima_Resp_Data : 0|64@1+ (1.0,0.0) [0.0|18446744073709551615] ""  Gateway

BO_ 1881 ISO_Lift_Req: 8 Gateway
 SG_ ISO_Lift_Req_Data : 0|64@1+ (1,0) [0|18446744073709551615] "Unit_None"  Lift_VA

BO_ 1987 ISO_Lift_Resp: 8 Lift_VA
 SG_ ISO_Lift_Resp_Data : 0|64@1+ (1,0) [0|18446744073709551615] "Unit_None"  Gateway

BO_ 2549874818 ISOx_LCM_L_Req: 8 Gateway
 SG_ ISO_LCM_L_Req_Data : 0|64@1+ (1.0,0.0) [0.0|18446744073709551615] ""  BCM1

BO_ 2550005890 ISOx_LCM_L_Resp: 8 BCM1
 SG_ ISO_LCM_L_Resp_Data : 0|64@1+ (1.0,0.0) [0.0|18446744073709551615] ""  Gateway

BO_ 2549874819 ISOx_LCM_R_Req: 8 Gateway
 SG_ ISO_LCM_R_Req_Data : 0|64@1+ (1.0,0.0) [0.0|18446744073709551615] ""  BCM1

BO_ 2550005891 ISOx_LCM_R_Resp: 8 BCM1
 SG_ ISO_LCM_R_Resp_Data : 0|64@1+ (1.0,0.0) [0.0|18446744073709551615] ""  Gateway

BO_ 2549874838 ISOx_LED_LM_L_Req: 8 Gateway
 SG_ ISO_LED_LM_L_Req_Data : 0|64@1+ (1.0,0.0) [0.0|18446744073709551615] ""  BCM1

BO_ 2550005910 ISOx_LED_LM_L_Resp: 8 BCM1
 SG_ ISO_LED_LM_L_Resp_Data : 0|64@1+ (1.0,0.0) [0.0|18446744073709551615] ""  Gateway

BO_ 2549874839 ISOx_LED_LM_R_Req: 8 Gateway
 SG_ ISO_LED_LM_R_Req_Data : 0|64@1+ (1.0,0.0) [0.0|18446744073709551615] ""  BCM1

BO_ 2550005911 ISOx_LED_LM_R_Resp: 8 BCM1
 SG_ ISO_LED_LM_R_Resp_Data : 0|64@1+ (1.0,0.0) [0.0|18446744073709551615] ""  Gateway

BO_ 2549874884 ISOx_VAS_L_Req: 8 Gateway
 SG_ ISO_VAS_L_Req_Data : 0|64@1+ (1,0) [0|18446744073709551615] ""  VAS_L

BO_ 2550005956 ISOx_VAS_L_Resp: 8 VAS_L
 SG_ ISO_VAS_L_Resp_Data : 0|64@1+ (1,0) [0|18446744073709551615] ""  Gateway

BO_ 2549874885 ISOx_VAS_R_Req: 8 Gateway
 SG_ ISO_VAS_R_Req_Data : 0|64@1+ (1,0) [0|18446744073709551615] ""  VAS_R

BO_ 2550005957 ISOx_VAS_R_Resp: 8 VAS_R
 SG_ ISO_VAS_R_Resp_Data : 0|64@1+ (1,0) [0|18446744073709551615] ""  Gateway

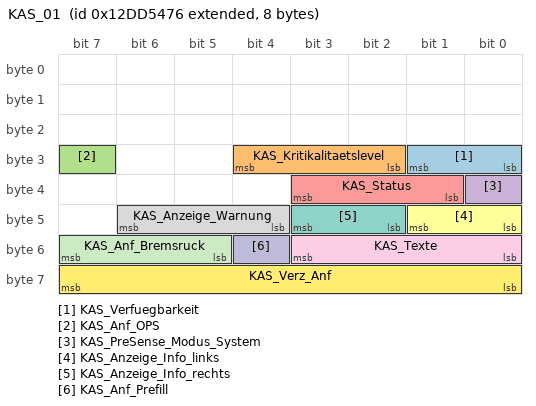
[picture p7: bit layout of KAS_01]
BO_ 2463978614 KAS_01: 8 Gateway
 SG_ KAS_Verfuegbarkeit : 24|2@1+ (1.0,0.0) [0.0|3] ""  Vector__XXX
 SG_ KAS_Kritikalitaetslevel : 26|3@1+ (1.0,0.0) [0.0|7] ""  BCM1
 SG_ KAS_Anf_OPS : 31|1@1+ (1.0,0.0) [0.0|1] ""  BCM1
 SG_ KAS_PreSense_Modus_System : 32|1@1+ (1.0,0.0) [0.0|1] ""  Vector__XXX
 SG_ KAS_Status : 33|3@1+ (1.0,0.0) [0.0|7] ""  Vector__XXX
 SG_ KAS_Anzeige_Info_links : 40|2@1+ (1.0,0.0) [0.0|3] ""  Vector__XXX
 SG_ KAS_Anzeige_Info_rechts : 42|2@1+ (1.0,0.0) [0.0|3] ""  Vector__XXX
 SG_ KAS_Anzeige_Warnung : 44|3@1+ (1.0,0.0) [0.0|7] ""  Vector__XXX
 SG_ KAS_Texte : 48|4@1+ (1.0,0.0) [0.0|15] ""  Vector__XXX
 SG_ KAS_Anf_Prefill : 52|1@1+ (1.0,0.0) [0.0|1] ""  Vector__XXX
 SG_ KAS_Anf_Bremsruck : 53|3@1+ (1.0,0.0) [0.0|7] ""  Vector__XXX
 SG_ KAS_Verz_Anf : 56|8@1+ (0.079,-19.987) [-19.987|0.000] "Unit_MeterPerSeconSquar"  Vector__XXX

BO_ 497 Kessy_11: 8 Gateway
 SG_ KY_IDG_in_Reichweite : 12|1@1+ (1.0,0.0) [0.0|1] ""  Vector__XXX
 SG_ KY_Auf_Taste : 13|1@1+ (1.0,0.0) [0.0|1] ""  Vector__XXX
 SG_ KY_HDF_Taste : 14|1@1+ (1.0,0.0) [0.0|1] ""  BCM1
 SG_ KY_Panik_Taste : 15|1@1+ (1.0,0.0) [0.0|1] ""  Vector__XXX
 SG_ KY_Zu_Taste : 16|1@1+ (1.0,0.0) [0.0|1] ""  Vector__XXX
 SG_ KY_FT_Entriegelung_Autorisiert : 17|1@1+ (1.0,0.0) [0.0|1] ""  BCM1
 SG_ KY_FT_Verriegelung_Autorisiert : 18|1@1+ (1.0,0.0) [0.0|1] ""  Vector__XXX
 SG_ KY_BT_Entriegelung_Autorisiert : 19|1@1+ (1.0,0.0) [0.0|1] ""  Vector__XXX
 SG_ KY_BT_Verriegelung_Autorisiert : 20|1@1+ (1.0,0.0) [0.0|1] ""  Vector__XXX
 SG_ KY_HFS_Entriegelung_Autorisiert : 21|1@1+ (1.0,0.0) [0.0|1] ""  Vector__XXX
 SG_ KY_HFS_Verriegelung_Autorisiert : 22|1@1+ (1.0,0.0) [0.0|1] ""  Vector__XXX
 SG_ KY_HBFS_Entriegelung_Autorisiert : 23|1@1+ (1.0,0.0) [0.0|1] ""  Vector__XXX
 SG_ KY_HBFS_Verriegelung_Autorisiert : 24|1@1+ (1.0,0.0) [0.0|1] ""  Vector__XXX
 SG_ KY_Front_Entr_Autorisiert : 25|1@1+ (1.0,0.0) [0.0|1] ""  BCM1
 SG_ KY_Front_Verr_Autorisiert : 26|1@1+ (1.0,0.0) [0.0|1] ""  BCM1
 SG_ KY_HD_Entriegelung_Autorisiert : 27|1@1+ (1.0,0.0) [0.0|1] ""  Vector__XXX
 SG_ KY_HD_Verriegelung_Autorisiert : 28|1@1+ (1.0,0.0) [0.0|1] ""  Vector__XXX
 SG_ KY_Bereich : 29|3@1+ (1.0,0.0) [0.0|7] ""  BCM1
 SG_ KY_Position : 32|3@1+ (1.0,0.0) [0.0|7] ""  BCM1
 SG_ KY_ZV_Signatur : 35|11@1+ (1,0) [0|2047] ""  Vector__XXX
 SG_ Schluesselnr_Personalisierung : 46|4@1+ (1.0,0.0) [0.0|15] ""  BCM1,Klima_MSB,VAS_L,VAS_R
 SG_ FFB_FDF_Taste : 50|1@1+ (1.0,0.0) [0.0|1] ""  BCM1
 SG_ FFB_Joker_Taste : 51|1@1+ (1.0,0.0) [0.0|1] ""  BCM1
 SG_ FFB_Park_Taste : 52|1@1+ (1.0,0.0) [0.0|1] ""  Vector__XXX
 SG_ FFB_Remotestart_Taste : 53|1@1+ (1.0,0.0) [0.0|1] ""  Vector__XXX
 SG_ FBS_Aktivierung_Pilot_Parken : 54|1@1+ (1.0,0.0) [0.0|1] ""  Vector__XXX
 SG_ KY_Schluessel_im_Fzg : 55|1@1+ (1.0,0.0) [0.0|1] ""  Vector__XXX
 SG_ KY_EasyClose_Abbruch : 56|1@1+ (1.0,0.0) [0.0|1] ""  Vector__XXX
 SG_ KY_EasyClose_Status : 57|3@1+ (1.0,0.0) [0.0|7] ""  Vector__XXX
 SG_ KY_HD_Auffahrt : 60|1@1+ (1.0,0.0) [0.0|1] ""  Vector__XXX
 SG_ KY_HD_Zufahrt : 61|1@1+ (1.0,0.0) [0.0|1] ""  Vector__XXX
 SG_ KY_LKL_1_Autorisierung : 62|1@1+ (1.0,0.0) [0.0|1] ""  Vector__XXX
 SG_ KY_LKL_2_Autorisierung : 63|1@1+ (1.0,0.0) [0.0|1] ""  Vector__XXX

CM_ BO_ 264 "ab MLBevo mit CRC";
CM_ BO_ 1416 "Heizleistungsregelung";
CM_ BO_ 1016 "Heizleistungsregelung 
MLBevo (NVEM im Gateway)";
CM_ BO_ 1340 "CAN-Botschaft";
CM_ BO_ 2527679583 "ehemals ZFAS_01";
CM_ BO_ 2549874818 "Lichtsteuerung links am Frontlicht-CAN";
CM_ BO_ 2550005890 "Lichtsteuerung links am Frontlicht-CAN";
CM_ BO_ 2549874819 "Lichtsteuerung rechts am Frontlicht-CAN";
CM_ BO_ 2550005891 "Lichtsteuerung rechts am Frontlicht-CAN";
CM_ BO_ 2549874838 "Lichtsteuerung links am Frontlicht-CAN";
CM_ BO_ 2550005910 "Lichtsteuerung links am Frontlicht-CAN";
CM_ BO_ 2549874839 "Lichtsteuerung rechts am Frontlicht-CAN";
CM_ BO_ 2550005911 "Lichtsteuerung rechts am Frontlicht-CAN";

CM_ SG_ 427 ESC_AHW_aktiv "Rueckmeldung Anhaltewegregelung aktiv
";
CM_ SG_ 427 ESC_AHW_nicht_verfuegbar "Rueckmeldung Anhaltewegregelung nicht verfuegbar
";
CM_ SG_ 427 ESC_ANB_CM_aktiv "Rueckmeldung ANB_CM (Autom_Notbremsung_Collision_Mitigation) aktiv
";
CM_ SG_ 427 ESC_ANB_CM_nicht_verfuegbar "Rueckmeldung ANB_CM nicht verfuegbar
";
CM_ SG_ 427 ESC_Bremslicht_unplausibel "Plausibilisierung der Rückmeldeinformation von BCM/AAG bezüglich Anforderung ESC_Bremslicht";
CM_ SG_ 427 ESC_Fahrer_Bremsdruck_bestimmend "Das Signal zeigt an, dass der Fahrer Bremsdruck bestimmend ist";
CM_ SG_ 427 ESC_HBA_aktiv "Rueckmeldung HBA (hydraulischer Bremsassistent) aktiv";
CM_ SG_ 427 ESC_HBA_nicht_verfuegbar "Rueckmeldung HBA (hydraulischer Bremsassistent) nicht verfuegbar";
CM_ SG_ 427 ESC_Konsistenz_ACC "Rueckmeldung Konsistenz der ACC Botschaften";
CM_ SG_ 427 ESC_Konsistenz_AGW "Rückmeldung Konsistenz der AGW-Botschaft an das ESC.";
CM_ SG_ 427 ESC_Konsistenz_ARA "Rueckmeldung Konsistenz der ARA Botschaften";
CM_ SG_ 427 ESC_Konsistenz_AWA "Rueckmeldung Konsistenz der AWA-Botschaften";
CM_ SG_ 427 ESC_Konsistenz_AWV "Rueckmeldung Konsistenz der AWV Botschaften";
CM_ SG_ 427 ESC_Konsistenz_BFF "Rückmeldung Konsistenz der Verzögerungsanforderung an das ESC-Steuergerät der Funktion 'Bremsen im freien Fahren' vom PDC_PLA_ARA-Steuergerät";
CM_ SG_ 427 ESC_Konsistenz_EA "Rueckmeldung Konsistenz der EA Botschaften (HCA)";
CM_ SG_ 427 ESC_Konsistenz_FAS_VK "Rueckmeldung Konsistenz der FAS_VK Botschaften";
CM_ SG_ 427 ESC_Konsistenz_FCW "Rueckmeldung Konsistenz der FCW Botschaften";
CM_ SG_ 427 ESC_Konsistenz_IPA "Rueckmeldung Konsistenz der IPA Botschaften";
CM_ SG_ 427 ESC_Konsistenz_KAS "Rückmeldung Konsistenz für Kreuzungsassistent-Anforderungen";
CM_ SG_ 427 ESC_Konsistenz_MKB "Rückmeldung Konsistenz für MKB-Verzögerungsanfoorderung";
CM_ SG_ 427 ESC_Konsistenz_NV "Rueckmeldung Konsistenz der NightVision Botschaften";
CM_ SG_ 427 ESC_Konsistenz_PCF "Rückmeldung der Konsistenz der PCF-Anforderungen";
CM_ SG_ 427 ESC_Konsistenz_RCTA "Rueckmeldung Konsistenz der RCTA (Rear Cross Traffic Alert) Botschaften";
CM_ SG_ 427 ESC_Konsistenz_STA "Rueckmeldung Konsistenz der STA Botschaften";
CM_ SG_ 427 ESC_Konsistenz_TSK "Rueckmeldung Konsistenz der TSK Botschaften";
CM_ SG_ 427 ESC_Konsistenz_vFGS "Rueckmeldung Konsistenz der vFGS Botschaften";
CM_ SG_ 427 ESC_Prefill_aktiv "Rueckmeldung Prefill aktiv";
CM_ SG_ 427 ESC_Prefill_nicht_verfuegbar "Rueckmeldung Prefill nicht verfuegbar";
CM_ SG_ 427 ESC_Pumpenanlauf_aktiv "Bestätigung der Durchführung eines Vorsteuerpumpenanlaufes";
CM_ SG_ 427 ESC_TSK_SRBM_Anf "Quittierung fuer TSK (SRBM=Summenradbremsmoment) Anforderung";
CM_ SG_ 427 ESC_TSK_SRBM_nicht_verfuegbar "Rueckmeldung TSK (SRBM= Summenradbremsmoment) nicht verfuegbar";
CM_ SG_ 427 ESC_Verz_ASIL_Verfuegbarkeit "Gibt die Verfuegbarkeit der VZM-Regelung an, wobei folgende Zustaende beruecksichtigt werden:
-Nicht Verfuegbarkeit wegen Sonderbetriebszustaenden (z.B. Produktionsmodus)
-ueber VZM abgebaute Fahrzeuggeschwindigkeit bei Verzögerungen a>5m/s², wobei gilt";
CM_ SG_ 427 ESC_Verz_Begrenzung "Rückmeldung angeforderte Verzögerung oder Summenradbremsmoment wird begrenzt umgesetzt  ";
CM_ SG_ 427 ESC_Verz_Reg_aktiv "Rueckmeldung Verzoegerungsregelung aktiv";
CM_ SG_ 427 ESC_Verz_Reg_nicht_verfuegbar "Rueckmeldung Verzoegerungsregelung nicht verfuegbar";
CM_ SG_ 427 ESC_Verz_Reg_TB_nicht_verfuegbar "Rueckmeldung Verzoegerungsregelung (Teilbremsung) nicht verfuegbar";
CM_ SG_ 427 ESC_Verz_Reg_ZB_nicht_verfuegbar "Rueckmeldung Verzoegerungsregelung ZB (Zielbremsung) nicht verfuegbar";
CM_ SG_ 427 ESC_Warnruck_aktiv "Rueckmeldung Warnruck aktiv";
CM_ SG_ 427 ESC_Warnruck_nicht_verfuegbar "Rueckmeldung Warnruck nicht verfuegbar";
CM_ SG_ 427 ESP_33_BZ "Botschaft asynchron geroutet. Zählerwert kann springen.";
CM_ SG_ 427 ESP_33_CRC "Für MLB:
'Berechnung siehe Lastenheft 'Kommunikationsabsicherung für FlexRay und CAN''

Ab MQB und MLBevo:
'Berechnung siehe Lastenheft 'End-to-End Kommunikationsabsicherung''

Endwerte siehe Begleitdokument 'S-PDU Kennungsfolgen'";

CM_ SG_ 264 FA_Fahrbahnunebenheit "Informationsbeschreibung des Fahrbahnzustandes";
CM_ SG_ 264 FA_Hoehenwert_HL_00 "Aktueller Höhenwert (kalibriert) Hinten Links; ungefiltertes Signal
Einheit, Offset und Faktor sind abhänig von 'FA_Hoehenwert_kalibriert'

Achtung:
Wird im AUDI B8 nicht bedient";
CM_ SG_ 264 FA_Hoehenwert_HR_00 "Aktueller Höhenwert (kalibriert) Hinten Rechts; ungefiltertes Signal
Einheit, Offset und Faktor sind abhänig von 'FA_Hoehenwert_kalibriert'

Achtung:
Wird im AUDI B8 nicht bedient";
CM_ SG_ 264 FA_Hoehenwert_VL_00 "Aktueller Höhenwert (kalibriert) Vorne Links; ungefiltertes Signal
Einheit, Offset und Faktor sind abhänig von 'FA_Hoehenwert_kalibriert'

Achtung:
Wird im AUDI B8 nicht bedient";
CM_ SG_ 264 FA_Hoehenwert_VR_00 "Aktueller Höhenwert (kalibriert) Vorne Rechts; ungefiltertes Signal
Einheit, Offset und Faktor sind abhänig von 'FA_Hoehenwert_kalibriert'

Achtung:
Wird im AUDI B8 nicht bedient";
CM_ SG_ 264 FA_Hoehenwerte_kalibriert "Legt fest, wie die Höhensensorwerte interpretiert werden müssen. Umschaltung kalibrierte Höhenwerte / Rohsignale in Byte 3-6

Achtung:
Im AUDI B8 Konstante: 0x1. D.h. es werden nur Rohwerte bedient!
Im AUDI D4 Konstante: 0x0. D.h. es werden nur Millim";
CM_ SG_ 264 Fahrwerk_01_CRC "Für MLB:
'Berechnung siehe Lastenheft 'Kommunikationsabsicherung für FlexRay und CAN''

Ab MQB und MLBevo:
'Berechnung siehe Lastenheft 'End-to-End Kommunikationsabsicherung''

Endwerte siehe Begleitdokument 'S-PDU Kennungsfolgen'";

CM_ SG_ 429 EFP_Soll_FahrPr_HAL "Anforderung einer Zwangsumschaltung des Fahrprogramms der HAL durch EFP";
CM_ SG_ 429 FA_Absenkung_Fahrzeug "Nächsttieferes Niveau wird angefahren (Absenken). Dieses Bit wird immer gesetzt in Verbindung mit einer Auswahl aus den Bits FA_Verstellung_xx.";
CM_ SG_ 429 FA_Anhaengerstatus_intern "Anzeige des SG-internen Verarbeitungsstatus Anhängers";
CM_ SG_ 429 FA_Anhebung_Fahrzeug "Nächsthöheres Niveau wird angefahren (Anheben). Dieses Bit wird immer gesetzt in Verbindung mit einer Auswahl aus den Bits FA_Verstellung_xx.";
CM_ SG_ 429 FA_Druckspeicher_verfuegbar "Bit ist gesetzt, wenn eine Regelung aus dem Druckspeicher möglich ist.";
CM_ SG_ 429 FA_ESP_Zuschaltung "Zwangsweise Aktivierung der ESP-Funktionalität wird angefordert auch bei Passivtastung";
CM_ SG_ 429 FA_HAL_Abschaltung "Anforderung einer Zwangs-Deaktivierung der HAL wegen zu geringem
Radfreigang durch Luftfeder oder Schneekettenbetrieb.";
CM_ SG_ 429 FA_Kompressor_laeuft "Zustand der Kompressoransteuerung";
CM_ SG_ 429 FA_Kompressor_laeuft_in_Kuerze "Kompressorlauf steht unmittelbar bevor. Das Bit wird immer gesetzt in Verbindung mit den Bits FA_Anhebung_Fahrzeug oder FA_Absenkung_Fahrzeug.";
CM_ SG_ 429 FA_Signal_Drucksensor "Signalwert des Drucksensors im Magnetventilblock";
CM_ SG_ 429 FA_Systemstatus "Bit wird gesetzt, wenn interne Funktionsprüfung i.O. und System generell funktionsfähig ist.";
CM_ SG_ 429 FA_Verstellung_aktiv "Verstellung ist aktiv. Dieses Bit wird immer gesetzt in Verbindung mit den Bits FA_Anhebung_Fahrzeug oder FA_Absenkung_Fahrzeug.";
CM_ SG_ 429 FA_Verstellung_in_Kuerze "Dieses Bit wird gesetzt, wenn eine Verstellung unmittelbar bevorsteht.";
CM_ SG_ 429 FA_Zwischenniveau "Dieses Bit wird gesetzt, wenn die Fahrzeughöhe zwischen 2 definierten Niveaus liegt, z.B.. während des Regelvorgangs.";
CM_ SG_ 429 Fahrwerk_06_BZ "Botschaft asynchron geroutet. Zählerwert kann springen.";
CM_ SG_ 429 Fahrwerk_06_CRC "Ab MQB und MLBevo:
'Berechnung siehe Lastenheft 'End-to-End Kommunikationsabsicherung''

Endwerte siehe Begleitdokument 'S-PDU Kennungsfolgen'";
CM_ SG_ 429 NR_Anforderung_v_Begrenzung "Anforderung einer v-Begrenzung an das Motor-SG.";
CM_ SG_ 429 NR_Kompressor_Strom_02 "Gemessener Strom am Kompressors.";
CM_ SG_ 429 NR_Kompressor_Temp_Zylinderkopf "Gemessene Temperatur im Zylinderkopf des Luftfeder-Kompressors";
CM_ SG_ 429 NR_LED_BN "Statusrückmeldung der eingestellten Fahrzeughöhe Beladungsniveau bzw. Tasterbetätigung Anheben/Absenken.";
CM_ SG_ 429 NR_LED_HN "Statusrückmeldung der eingestellten Fahrzeughöhe Hochniveau
";
CM_ SG_ 429 NR_LED_SGN "Statusrückmeldung der eingestellten Fahrzeughöhe Sondergeländeniveau bzw. Tasterbetätigung Anheben/Absenken.";
CM_ SG_ 429 NR_LED_TN "Statusrückmeldung der eingestellten Fahrzeughöhe Tiefniveau";
CM_ SG_ 429 NR_Reglerstatus "Anzeige des auszuregelnden Sollniveaus (wird bei Beginn der Regelung auf entsprechenden Wert gesetzt).";

CM_ SG_ 1605 FLA_Abblendursache "FLA Abblendursache
(20ms Task)";
CM_ SG_ 1605 FLA_aktiv "FLA aktiv  (200ms Task)";
CM_ SG_ 1605 FLA_Aufblenden "FLA Aufblenden (20ms Task)";
CM_ SG_ 1605 FLA_Fernlicht_PWM "FLA PWM Vorgabe Fernlicht
(20ms Task)";
CM_ SG_ 1605 FLA_ISP_defekt "FLA Innenspiegel defekt
interner Fehler  (200ms Task)";
CM_ SG_ 1605 FLA_SAE_Mode "Rückmeldung an den Fahrer, über Wechsel in den SAE Modus --> wird nur für den amerikanischen Markt benötigt.";
CM_ SG_ 1605 FLA_Sensor_blockiert "FLA Sensor blockiert
Sichtbeeinträchtigung CMOS-Kamera  (200ms Task)";
CM_ SG_ 1605 ISP_Dimmung_ASP_02 "Dimmwertvorgabe für Aussenspiegel
Es wird 1:1 die Spannung am Innenspiegel nach außen übertragen.";
CM_ SG_ 1605 ISP_EC_aktiv "Status Innenspiegel (EC-Spiegel)
";
CM_ SG_ 1605 ISP_EC_Lichtwert_hinten "Innenspiegel: Lichtwert hinten
";
CM_ SG_ 1605 ISP_EC_Lichtwert_vorne "Innenspiegel: Lichtwert vorne
";
CM_ SG_ 1605 ISP_Himmelsrichtung "Himmelsrichtung Kompass im EC Spiegel
Wertebereich 0-29 (12°-Schritte, 0-348°)
";
CM_ SG_ 1605 ISP_Kompass_aktiv "Status Kompass Innenspiegel
";
CM_ SG_ 1605 ISP_Taste_betaetigt "ISP Taste betätigt
(200ms Task)";

CM_ SG_ 2589283684 FoD_Anz_Funktionsabschaltung "Signal triggert Aufschaltung eines Popups, um dem Fahrer die Abschaltung einer Funktion zu melden.";
CM_ SG_ 2589283684 FoD_Transmission_Info "Mit dem Signal zeigt der FoD-Master allen FoD-Slaves den Beginn und das Ende eines Freischaltuebertragungszykluses (FS-ID-Zyklus) an.";

CM_ SG_ 2549875470 FoD_BCM1_Req_Data "Function on demand request an BCM1";

CM_ SG_ 2550006542 FoD_BCM1_Resp_Data "Function on demand response vom BCM1";

CM_ SG_ 1523 Diag_Frontscheibe "Übertragung der Fehler:
    Bit 1: Unterer Grenzwert unterschritten
    Bit 2: Oberer Grenzwert ueberschritten
    Bit 3: zur Zeit nicht pruefbar
    Bit 4: Unterbrechung
    Bit 5: El. Fehler im Stromkreis 
    Bit 6: El. Fehler im Stromkreis 
   ";
CM_ SG_ 1523 FSH_LED "LED Ansteuerung Frontscheibenheizung";
CM_ SG_ 1523 HW_SW_Frontscheibe "HW/SW-Version:
    HW Bit 1..4
    SW Bit 5..8";
CM_ SG_ 1523 I_Heiz_Frontscheibe "Stromaufnahme Frontscheibenheizung";
CM_ SG_ 1523 P_Heiz_Frontscheibe "aktuelle Leistungsaufnahme";
CM_ SG_ 1523 R_grenz_max "Oberer Widerstandsgrenzwert";
CM_ SG_ 1523 R_grenz_min "Unterer Widerstandsgrenzwert";
CM_ SG_ 1523 R_ist "aktueller Widerstandsmesswert";

CM_ SG_ 173 GE_Fahrstufe "Fahrprogramm des Getriebes

Hinweis: Zwischenstellung '0x0' darf nur für Zustandswechsel P/R, R/N, N/D ausgegeben werden, nicht für D/S oder D/Tippgasse wegen Abschaltkriterium GRA/ACC";
CM_ SG_ 173 GE_Freig_MMom_Vorhalt "Freigabe für die Anforderung einer Momentenreserve durch das Getriebe über das Signal
MLB: GE_MMom_Vorhalt
MQB/MLBevo: GE_MMom_Vorhalt_02";
CM_ SG_ 173 GE_MMom_Soll_02 "Momenteneingriff an den Motor.
Fordert vom MSG eine kurzfristige Reduzierung oder Anhebung des Moments.
Das Signal ist nur gültig in Kombination mit GE_MMom_Status (bei MQB) bzw. GE_MMom_Status_02 (bei MLBevo).

Achtung:
Einheitenloser Wert! Faktor i";
CM_ SG_ 173 GE_MMom_Status "Qualifiziert 
MLB: GE_MMom_Soll
MQB: GE_MMom_Soll_02";
CM_ SG_ 173 GE_MMom_Status_02 "Das Signal qualifiziert GE_MMom_Soll_02 und gibt an, wie der Wert aus GE_MMom_soll – vorbehaltlich der Umsetzbarkeit aufgrund motorinterner Restriktionen – umgesetzt werden soll.
Werte:
0= kein Eingriff
1=   absoluter reduzierender Eingriff auf Gesamt ";
CM_ SG_ 173 GE_MMom_Vorhalt_02 "Anforderung einer Momentenreserve durch das Getriebe, gilt nur mit Freigabe durch 
GE_Freig_MMom_Vorhalt

Anforderung wird als Absolut-Wert umgesetzt, nicht als Relativ-Wert/Delta zum aktuellen Ist-Moment (d. h. eine Momentenreserve wird eingestellt, w";
CM_ SG_ 173 GE_reserv_Fahrstufe "reserviert, falls künftig Erweiterung von GE_Fahrstufe nötig";
CM_ SG_ 173 GE_Schaltablauf "Das Signal zeigt den aktuellen Status eines Schaltvorgangs.

Bei Signal = 0 liegt kein Schaltvorgang vor.
Bei Signal =2 liegt die Befüllphase der zuschaltenden Kupplung bzw. 
                      die Vorbereitungsphase dazu vor.

Mit den unterschie";
CM_ SG_ 173 GE_Status_Kraftschluss "Zeigt den Ist-Status des Kraftschlusses im Getriebe.
(Anmerkung: meist wird damit der Zustand des Anfahrelements beschrieben, d.h. bei DL/DQ die Kupplung;  bei AQ/AL der Wandler incl. Überbrückungskupplung)
0 = offen, kein Kraftschluss
1 = offen mit Kr";
CM_ SG_ 173 GE_Uefkt "Übertragungsfunktion des Getriebes
Drehzahlverhältnis = Eingangsdrehzahl / Ausgangsdrehzahl

AL: Wandlerverstärkung x Drehzahlverhältnis
VL: Drehzahlverhältnis
DL: Drehzahlverhältnis der aktiven und kraftschluß führenden Welle zum Abtrieb, bei Schalt";
CM_ SG_ 173 GE_Uefkt_unplausibel "Das Signal darf nur im Reku-Manager in Hybrid-Varianten verwendet werden.
Zeigt an, ob die Plausibilisierung Momenten-Verhältnis zu Drehzahl-Verhältnis i.O. ist.
Ein gesetztes Signal meldet eine unplausible GE_Uefkt bzw. GE_Uefkt_02.";
CM_ SG_ 173 GE_Verbot_Ausblendung "Verbot Einspritzausblendung für komfortable Schaltungen";
CM_ SG_ 173 GE_Zielgang "VL-Getriebe:
Signalisiert den Zielgang im manuellen Modus während eines Schaltvorgangs bzw. die momentane simulierte Gangstufe wenn kein Schaltvorgang aktiv ist. In den Fahrprogrammen 'D' und 'S' ist die Übersetzung variabel und somit wird dauerhaft 'Ist";
CM_ SG_ 173 Getriebe_11_BZ "Botschaftszähler
Botschaft asynchron geroutet. Zählerwert kann springen.";
CM_ SG_ 173 Getriebe_11_CRC "Für MLB:
'Berechnung siehe Lastenheft 'Kommunikationsabsicherung für FlexRay und CAN''

Ab MQB und MLBevo:
'Berechnung siehe Lastenheft 'End-to-End Kommunikationsabsicherung''

Endwerte siehe Begleitdokument 'S-PDU Kennungsfolgen'";

CM_ SG_ 177 GE_Anschleppstart_Freigabe "Bilden einer Schleppstartfreigabe aus Fahrdynamiksicht. Schleppstartabbruch bei kritischer Fahrzeugstabilität";
CM_ SG_ 177 GE_Eingangsdrehz_Praed "prädizierte Getriebe-Eingangsdrehzahl (während Schaltungen kann die voraussichtliche Drehzahl am Ende der Schaltung gezeigt werden)";
CM_ SG_ 177 GE_Fahrprogramm "Signalisiert das Fahrprogramm  im Bezug auf
die Fahrstufe des Getriebes.

Audi/MQB:
Offroad

Bentley:
Snow
Gravel
Mud_Ruts
Sand_Dune

Touareg:
Offroad
Snow";
CM_ SG_ 177 GE_Freilauf_Status "Freilauf-Status-Signal vom Frailauf-Master an aktive Freilauf-Teilnehmer. In diesem Signal zeigt der Freilauf-Master an, welchen aktuellen Status die Freilauf-Betriebsstrategie hat.";
CM_ SG_ 177 GE_Getriebestatus_02 "Signalisierung von speziellen Betriebszuständen des Getriebes:
1= Rennstartvorbereitung; genutzt im MSG zum Aufbau einer Momentenreserve, in Allrad und Quersperre (GQS)
2= Rennstart; nicht genutzt im MSG
3= Anfahrt; genutzt im MSG zur Umschaltung des F";
CM_ SG_ 177 GE_Grundeinstellung "Grundeinstellung des Getriebes ist aktiv

Hinweis:
Verwendung nur im MQB";
CM_ SG_ 177 GE_KomFehler_ESP "Anzeige Kommunikationsfehler bei Empfang vom ESP.

Einsatz nur in PDK-Projekten.";
CM_ SG_ 177 GE_Rollrichtung_falsch "Rollrichtung des Fahrzeugs ist entgegen der eingelegten Fahrstufe (bezogen auf GE_Fahrstufe);
0 = Rollrichtung richtig bzw. Init (auch im Stillstand bzw. in P/N/Zwischenposition)
1 = Rollrichtung falsch";
CM_ SG_ 177 GE_Strombedarf_erh "Das GSG teilt dem MSG einen aufgrund der Kühlung erhöhten Strombedarf mit, damit gleichzeitig die Kühler-Lüfter-Ansteuerung kurzzeitig reduziert wird.

Signal wird bisher nur im MQB-PHEV verwendet.";
CM_ SG_ 177 GE_TippZustand "Zeigt den Tippzustand in eine Fahrstufe und ein Fahrprogramm via Paddles oder Schaltbetätigung an.
Das Signal ist gültig in Kombination mit GE_Fahrstufe und GE_Fahrprogramm.

MLBevo:
DL und AL: nur Tipp_in_permanent
PDK2: Tipp_in_temporaer und Tipp_i";
CM_ SG_ 177 GE_Uefkt_Praed "Praedizierte Triebstrangübertragungsfunktion 
(Verständnis Übertragungsfunktion gemäß Ge_Uefkt_02)
Weiterführende Informationen sind bei der entsprechenden Fachabteilung zu erfragen.";
CM_ SG_ 177 Getriebe_17_BZ "Botschaftszähler
Botschaft asynchron geroutet. Zählerwert kann springen.";
CM_ SG_ 177 Getriebe_17_CRC "Für MLB:
'Berechnung siehe Lastenheft 'Kommunikationsabsicherung für FlexRay und CAN''

Ab MQB und MLBevo:
'Berechnung siehe Lastenheft 'End-to-End Kommunikationsabsicherung''

Endwerte siehe Begleitdokument 'S-PDU Kennungsfolgen'";

CM_ SG_ 310 HAL_01_CRC "Für MLB:
'Berechnung siehe Lastenheft 'Kommunikationsabsicherung für FlexRay und CAN''

Ab MQB und MLBevo:
'Berechnung siehe Lastenheft 'End-to-End Kommunikationsabsicherung''

Endwerte siehe Begleitdokument 'S-PDU Kennungsfolgen'
";
CM_ SG_ 310 HAL_Charisma_FahrPr "MLBevo: Aktuelles Fahrprogramm des Charisma-Teilnehmers (siehe Systemlastenheft Drive Select)
MQB: Istwert der Kennlinie (siehe Systemlastenheft MQB FPA)";
CM_ SG_ 310 HAL_Charisma_Status "Rückmeldung an den Charisma-Master";
CM_ SG_ 310 HAL_EFP_FahrPr "Aktueller Ist-Zustand der HAL";
CM_ SG_ 310 HAL_Fahrerwunschwinkel_Soll "Zielwinkel (=Fahrerwunschwinkel) am Rad Hinterachslenkung in Grad";
CM_ SG_ 310 HAL_max_Gradient "maximaler Zustellgradient für die Stabilisierungsfunktion mit HAL durch ESP";
CM_ SG_ 310 HAL_QBit_Radwinkel "Wenn Bit gesetzt, dann entspreicht das Signal nicht mehr ASIL-D. (z.B. Ausfall der redundanten Sensorik)";
CM_ SG_ 310 HAL_Radwinkel "Zusätzlich durch die HAL gestellter Radwinkeloffset an der Hinterachse in Grad";
CM_ SG_ 310 HAL_Status "Status der Hinterachslenkung
0: normaler Betrieb 
1: HAL verriegelt (z.B. harter Fehler, nicht kalibriert)
2: Rücknahme der Leistung, Funktion eingeschränkt/Derating aktiv 
3: HAL deaktiviert";
CM_ SG_ 310 HAL_VZ_Fahrerwunschwinkel_Soll "Soll-Lenkrichtung der HAL";
CM_ SG_ 310 HAL_VZ_Radwinkel "Lenkrichtung der HAL";
CM_ SG_ 310 HAL_Warnungen "Warnmeldungsanforderung von der Hinterachslenkung an das Kombiinstrumnent";
CM_ SG_ 310 HAL_Winkelbegrenzung "Signal liefert die Info über eine aktive Winkelbegrenzung in der HAL aufgrund Bauteilschutz";

CM_ SG_ 676 HAL_02_BZ "4bit Botschaftszaehler; wird in jeder Sendebotschaft inkrementiert";
CM_ SG_ 676 HAL_02_CRC "Für MLB:
'Berechnung siehe Lastenheft 'Kommunikationsabsicherung für FlexRay und CAN''

Ab MQB und MLBevo:
'Berechnung siehe Lastenheft 'End-to-End Kommunikationsabsicherung''

Endwerte siehe Begleitdokument 'S-PDU Kennungsfolgen'";
CM_ SG_ 676 HAL_ARA_Status "Anforderung vom Anhängerrangierassistent. 
16 Statuswerte";
CM_ SG_ 676 HAL_IL_Status "Status des Funktionsanteils Integrallenkung in der HAL";
CM_ SG_ 676 HAL_PLA_Status "16 Statuswerte (siehe LH PLA/HAL)";
CM_ SG_ 676 HAL_PWR_Abbruch "Dieses Signal gibt das Abbruchkriterium für PLA und ARA an.
";
CM_ SG_ 676 HAL_PWR_Fehler "Gibt den Fehler aus wenn eine Radwinkelanforderung nicht ausgeführt werden konnte.
";

CM_ SG_ 1410 HD_Bewegung_auf "Bewegung HD (öffnen)
";
CM_ SG_ 1410 HD_Bewegung_zu "Bewegung HD (schließen)
";
CM_ SG_ 1410 HD_Endstellung_oben "obere Endstellung HD
";
CM_ SG_ 1410 HD_Endstellung_unten "untere Endstellung HD
";
CM_ SG_ 1410 HD_Innentaster_betaetigt "Betätigung Innentaster HD
";
CM_ SG_ 1410 HD_Position "HD Position von 0 bis 100 %";
CM_ SG_ 1410 HD_Rueckmeld_prog "Programmierung Endstellung HD 
";
CM_ SG_ 1410 HD_Taster_defekt "Anzeige ob Heckdeckeltaster defekt ist";
CM_ SG_ 1410 HD_UeKB_erkannt "Erkennung Einklemmschutz
";
CM_ SG_ 1410 HD_Verr_Taster_betaetigt_inv "Inverses Bit (Fusi-Anforderung) Betätigung des Verriegelungstaster für Heckdeckel";
CM_ SG_ 1410 HD_Verriegelungstaster_betaetigt "Betätigung des Verriegelungstaster für Heckdeckel";
CM_ SG_ 1410 HD_ZZH_Schalter_S3 "Teilt den Zustand des Statusschalters in einer unidirektionalen ZZH mit.";

CM_ SG_ 1416 BCM1_TCH_HLR_Anf "Kundenanforderung des Thermocupholders zum Heizen-/Kühlen";
CM_ SG_ 1416 FSH_LED "LED Ansteuerung Frontscheibenheizung";
CM_ SG_ 1416 HLR_SIH_Freigabe_Fond "Freigabe des EM für Sitzheizungen hinten";
CM_ SG_ 1416 HSH_LED "LED Ansteuerung Heckscheibenheizung";
CM_ SG_ 1416 KRH_Stufe_LED_li "Statusmeldung Kopfraumheizung links";
CM_ SG_ 1416 KRH_Stufe_LED_re "Statusmeldung Kopfraumheizung rechts";
CM_ SG_ 1416 SIH_Stufe_LED_HL "Statusmeldung Sitzheizung hinten links";
CM_ SG_ 1416 SIH_Stufe_LED_HR "Statusmeldung Sitzheizung hinten rechts";
CM_ SG_ 1416 SIH_Stufe_LED_li "Statusmeldung Sitzheizung links";
CM_ SG_ 1416 SIH_Stufe_LED_re "Statusmeldung Sitzheizung rechts";
CM_ SG_ 1416 SIL_Stufe_LED_HL "Statusmeldung Sitzlüftung hinten links";
CM_ SG_ 1416 SIL_Stufe_LED_HR "Statusmeldung Sitzlüftung hinten rechts";
CM_ SG_ 1416 SIL_Stufe_LED_li "Statusmeldung Sitzlüftung links";
CM_ SG_ 1416 SIL_Stufe_LED_re "Statusmeldung Sitzlüftung rechts";

CM_ SG_ 1016 HLR_FlHz_Freigabe_HL "Freigabe des NVEM für die Flächenheizung hinten links";
CM_ SG_ 1016 HLR_FlHz_Freigabe_HR "Freigabe des NVEM für die Flächenheizung hinten rechts";
CM_ SG_ 1016 HLR_FlHz_Freigabe_Ruhesitz "Freigabe des NVEM für die Flächenheizung des Ruhesitzes";
CM_ SG_ 1016 HLR_FlHz_Freigabe_VL "Freigabe des NVEM für die Flächenheizung vorne links";
CM_ SG_ 1016 HLR_FlHz_Freigabe_VR "Freigabe des NVEM für die Flächenheizung vorne rechts";
CM_ SG_ 1016 HLR_FSH_Freigabe "Freigabe des EEM für die Frontscheibenheizung";
CM_ SG_ 1016 HLR_HSH_Freigabe "Freigabe des EEM für die Heckscheibenheizung";
CM_ SG_ 1016 HLR_KRH_Freigabe_VL "Freigabe des EEM für die Kopfraumheizung vorne links";
CM_ SG_ 1016 HLR_KRH_Freigabe_VR "Freigabe des EEM für die Kopfraumheizung vorne rechts";
CM_ SG_ 1016 HLR_LRH_Freigabe "Freigabe für die Lenkradheizung";
CM_ SG_ 1016 HLR_PTC_Freigabe "Freigabe des elektrischen Energiemanagements für das gestufte/geregelte PTC";
CM_ SG_ 1016 HLR_PTC_linear_Freigabe "Freigabe des EEM für den linearen PTC-Zuheizer";
CM_ SG_ 1016 HLR_SIH_Freigabe_Fond "Freigabe des EM für Sitzheizungen hinten";
CM_ SG_ 1016 HLR_SIH_Freigabe_HL "Freigabe des EEM für die Sitzheizung hinten links";
CM_ SG_ 1016 HLR_SIH_Freigabe_HR "Freigabe des EEM für die Sitzheizung hinten rechts";
CM_ SG_ 1016 HLR_SIH_Freigabe_VL "Freigabe des EEM für die Sitzheizung vorne links";
CM_ SG_ 1016 HLR_SIH_Freigabe_VR "Freigabe des EEM für die Sitzheizung vorne rechts";
CM_ SG_ 1016 HLR_SIL_Freigabe_HL "Freigabe des EEM für die Sitzbelüftung hinten links";
CM_ SG_ 1016 HLR_SIL_Freigabe_HR "Freigabe des EEM für die Sitzlüftung hinten rechts";
CM_ SG_ 1016 HLR_SIL_Freigabe_VL "Freigabe des EEM für die Sitzlüftung Vorne Links";
CM_ SG_ 1016 HLR_SIL_Freigabe_VR "Freigabe des EEM für die Sitzlüftung vorne Rechts";
CM_ SG_ 1016 HLR_Sp_Heizung_Freigabe_BT "Freigabe der Außenspiegelheizung Beifahrerseite";
CM_ SG_ 1016 HLR_Sp_Heizung_Freigabe_FT "Freigabe des EEM für die Außenspiegelheizung rechtsFreigabe der Außenspiegelheizung Fahrerseite";
CM_ SG_ 1016 HLR_TCH_Freigabe "Freigabe des NVEM für den Thermocupholder";

CM_ SG_ 1283 HV_Bordnetz_aktiv "Signalisiert ein aktives Hochvoltbordnetz. Für die Belastbarkeit des HV-Netzes müssen Strom- bzw. Leistungsgrenzen eingehalten werden";
CM_ SG_ 1283 HV_Bordnetz_Fehler "Status ob im  HV-Netz ein Fehler detektiert wurde.";
CM_ SG_ 1283 HVK_01_CRC "Für MLB:
'Berechnung siehe Lastenheft 'Kommunikationsabsicherung für FlexRay und CAN''

Ab MQB und MLBevo:
'Berechnung siehe Lastenheft 'End-to-End Kommunikationsabsicherung''

Endwerte siehe Begleitdokument 'S-PDU Kennungsfolgen'";
CM_ SG_ 1283 HVK_AktiveEntladung_Anf "Anforderung zum aktiven Entladen des HV-Netzes, während der Abschaltung des HV-Netz.";
CM_ SG_ 1283 HVK_BMS_Sollmodus "Angeforderter Sollmodus der HV-Batterie:
0 : HV_Off                                
1 : HV_On (HS geschlossen)                
2 : nicht belegbar                        
3 : AC-Laden_erw (HS +AC_2-Schütze geschlossen)                         
4 : AC-";
CM_ SG_ 1283 HVK_DCDC_Sollmodus "angeforderte Soll-Betriebsart des DC/DC-Wandlers: 
0: Standby; Kommunikation aktiv
1: Zwischenkreis des HV-Netzes wird vorgeladen; HV-Netz wird aktiviert und darf nicht  
    belastet werden.
2: Tiefsetzen (HV --> BN 14,4V)
    Sollwertvorgabe projek";
CM_ SG_ 1283 HVK_EKK_Sollmodus "Sollmodus elektrischer Klimakompressor";
CM_ SG_ 1283 HVK_Gesamtst_Spgfreiheit "Status des HV-Systems";
CM_ SG_ 1283 HVK_HV_Netz_Warnungen "Anforderung Warnung/Fehler HV-System im Kombi
0: Keine Warnung/Init
1:Anforderung_Anzeige_Warnung_HV-Netz (gelbes Symbol)
2:Anforderung_Anzeige_Fehler_HV-Netz (rotes Symbol)
3:Anforderung_Anzeige_Warnung_Kein_Wiederstart_möglich";
CM_ SG_ 1283 HVK_HVLM_Sollmodus "Angeforderter Sollmodus des Lademanagers.";
CM_ SG_ 1283 HVK_HVPTC_Sollmodus "Sollmodus HV-PTC
0 : keine Freigabe
1 : Freigabe
2 : nicht belegbar
3 : nicht belegbar
4 : nicht belegbar
5 : nicht belegbar
6 : nicht belegbar
7 : Init   (CAN-Initialisierung)   

Info: 'nicht belegbar' d.h. Sollmodus nicht relevant für HVK";
CM_ SG_ 1283 HVK_Istmodus_Anf "HVK-Anforderung an alle HV-Komponenten deren Istmodus im schnellen Zyklus (Inhibitzeit) zu senden.";
CM_ SG_ 1283 HVK_MO_EmSollzustand "Anforderung vom HVK Sollzustand der Elm_State
0 = HvOff              
1 = HvStbyReq          
2 = HvStbyWait         
3 = HvBattOnReq        
4 = HvBattOnWait       
10 = HvOnIdle          
18 = HvOnDrvReq        
19 = HvOnDrvWait       
20 = HvO";
CM_ SG_ 1283 HVK_TN1_Sollmodus "Angeforderter Sollmodus der Steuereinheit für das Schütze des Teilnetz1 'Ladepfad':
0 : HV_Off                                
1 : HV_On (Schütz geschlossen)                
2 : reserviert
3 : Init   (CAN-Initialisierung)";

CM_ SG_ 1381 HVLM_FreigabeKlimatisierung "Klimatisierung freigeben";
CM_ SG_ 1381 HVLM_FreigabeTankdeckel "Tankdeckelfreigabe";
CM_ SG_ 1381 HVLM_HV_Abstellzeit "Zeitraum zwischen HV-Deaktiviert und HV-Aktiviert";
CM_ SG_ 1381 HVLM_IsoMessung_Anf "Signalisierung an den HVK, ob während des Ladens eine Iso-Messung durchgeführt werden muss.
0 = Laden mit Isomessung
1 = Laden ohne Isomessung";
CM_ SG_ 1381 HVLM_IstSpannung_HV "Ausgangsspannung des Ladegerätes und DC-Spannung der Ladesäule. Messung zwischen den DC HV-Leitungen. ";
CM_ SG_ 1381 HVLM_Ladesystemhinweise "Anzeigen von Hinweisen zum Ladesystem.
Anzeigen, dass das Ladesystem defekt ist.";
CM_ SG_ 1381 HVLM_Ladetexte "Anzeige, ob AC- oder DC-Laden nicht möglich ist";
CM_ SG_ 1381 HVLM_LG_Sollmodus "Sollmodus AC Ladegerät";
CM_ SG_ 1381 HVLM_MaxStrom_Netz "maximal zulässiger Strom auf Primärseite (AC) des Ladegerätes
Minima aus
Vorgabe z.B. über
- intelligente Kommunikation
- Control Pilot Duty Cycle
- Widerstandskodierung Kabel (Proximity)
- Vorgabe MMI, o.ä.";
CM_ SG_ 1381 HVLM_Schluessel_Anfrage "Anforderung HVLM an BCM für Schlüsselsuche über Kessy";
CM_ SG_ 1381 HVLM_Start_Spannungsmessung_DCLS "Meldung an das BMS, dass an der DC-Ladesäule eine Messspannung aufgeschaltet wird.";
CM_ SG_ 1381 HVLM_Stecker_Verriegeln "Anforderung Steckerverriegelung";
CM_ SG_ 1381 HVLM_Zustand_LED "Zustand der Lade-LED im Kombi und Dosenbeleuchtung";

CM_ SG_ 1340 HVLM_04_BZ "Fortlaufender Botschaftszaehler";
CM_ SG_ 1340 HVLM_04_CRC "Für MLB:
'Berechnung siehe Lastenheft 'Kommunikationsabsicherung für FlexRay und CAN''

Ab MQB und MLBevo:
'Berechnung siehe Lastenheft 'End-to-End Kommunikationsabsicherung''

Endwerte siehe Begleitdokument 'S-PDU Kennungsfolgen'";
CM_ SG_ 1340 HVLM_Anforderung_HMS "Anforderung zur Verriegelung des Triebstrangs";
CM_ SG_ 1340 HVLM_AWC_Sollmodus "Sollmodus AWC Ladegerät";
CM_ SG_ 1340 HVLM_Fehlerstatus "aktueller Fehlerstatus des Ladegerätes
";
CM_ SG_ 1340 HVLM_HV_Anf "HV-Aktivierung Anforderung und Grund der Anforderung";
CM_ SG_ 1340 HVLM_HVEM_MaxLeistung "Maximal zulässige Leistung, die das HVEM vom Lader nutzen darf. Wenn das Fzg nicht über einen Lader mit dem AC Netz verbunden ist ist dieser Wert 0.";
CM_ SG_ 1340 HVLM_IstModus_02 "aktueller Modus";
CM_ SG_ 1340 HVLM_LadeAnforderung "Mitteilung des Lademanagements an das MSG ob Stecker erkannt wurde, Laden gestartet, ein autonomer Betriebszustand aktiviert, eine Relaxing Phase für die Batterie angefordert werden soll";
CM_ SG_ 1340 HVLM_Ladeart "Anzeige, ob Strom in das Fzg. fließt und wofür er verwendet wird.";
CM_ SG_ 1340 HVLM_MaxBatLadestromHV "Empfohlener HV Batterieladestrom bei einer geplanten Ladung";
CM_ SG_ 1340 HVLM_Parken_beibehalten_HMS "Anforderung den Triebstrang verriegelt zu halten";
CM_ SG_ 1340 HVLM_Standklima_Timer_Status "Signalisierung an das KBT ob mind. ein Timer zur Standklimatisierung programmiert ist";
CM_ SG_ 1340 HVLM_Status_Netz "Information, ob das Fahrzeug mit einem Stromnetz verbunden ist.";
CM_ SG_ 1340 HVLM_Stecker_Status "Status der Steckererkennung unabhängig vom Lademodus (AC oder DC)";
CM_ SG_ 1340 HVLM_STH_Betriebsmodus "Betriebsmodus der Standheizung für Vorkonditionierung und Timerklimatisierung";
CM_ SG_ 1340 HVLM_VK_Modus "Übermittlung des aktuellen Konditionierungs-Status für HMI, Mobile Online Dienste";
CM_ SG_ 1340 HVLM_VK_STH_Einsatz "Auswahl der PHEV Standheizung";

CM_ SG_ 2589283485 HVLM_BattKond_Anf "Anforderung Batteriekonditionierung";
CM_ SG_ 2589283485 HVLM_Dauer_Klima_02 "Dauer der Innenraumklimatisierung.";

CM_ SG_ 2463978610 HVLM_Ladeanzeige_Anf "Lichtmuster für Charge Check
Sendeart = On Change, Zykluszeit = 500ms, Inhibitzeit = 10ms anlog des Signals im MQB (HVLM_10) auf dem A CAN";
CM_ SG_ 2463978610 HVLM_Ladeanzeige_Intens_Front "aktuelle Helligkeit für die Anzeige des Ladestatus über Front-Fahrzeug-Lichtelemente ";
CM_ SG_ 2463978610 HVLM_Ladeanzeige_Intens_Heck "aktuelle Helligkeit für die Anzeige des Ladestatus über Heck-Fahrzeug-Lichtelemente";
CM_ SG_ 2463978610 HVLM_Ladeanzeige_Rampzeit "Zeit innerhalb der die gesendet Intensität für die Ladeanzeige erreicht werden soll";
CM_ SG_ 2463978610 HVLM_Ladeanzeige_Status "Funktionsstatus ChargeCheck
Sendeart = On Change, Zykluszeit = 500ms, Inhibitzeit = 10ms anlog des Signals im MQB (HVLM_10) auf dem A CAN";
CM_ SG_ 2463978610 HVLM_RtmWarnLadeKommunikation "RTM Warning of charging communction fault";
CM_ SG_ 2463978610 HVLM_RtmWarnLadestatus "RTM Warning of charging status fault";
CM_ SG_ 2463978610 HVLM_RtmWarnLadesystem "RTM Electrical machine CAN communication fault";
CM_ SG_ 2463978610 HVLM_RtmWarnLadeverbindung "RTM Charging connection fault";

CM_ SG_ 1524 AMB_Charisma_FahrPr "MLBevo: Aktuelles Fahrprogramm des Charisma-Teilnehmers (siehe Systemlastenheft Drive Select)
MQB: Istwert der Kennlinie (siehe Systemlastenheft MQB FPA)";
CM_ SG_ 1524 AMB_Charisma_Status "Systemstatus des Charismateilnehmers

Wert 0x3 ist nur für Fahrzeuge ab MQB relevant";
CM_ SG_ 1524 BCM1_DI_Rampe_Innenlicht "Dimmrampe Innenlicht";
CM_ SG_ 1524 BCM1_DI_Rampe_Leselicht "Dimmrampe Leselicht";
CM_ SG_ 1524 BCM1_Innenlicht_gedimmt_H "Steuerung von BCM_Innenlicht_H";
CM_ SG_ 1524 BCM1_Innenlicht_gedimmt_V "Steuerung von BCM_Innenlicht_V";
CM_ SG_ 1524 BCM1_Innenlicht_H "Anforderung Innenlicht hinten";
CM_ SG_ 1524 BCM1_Innenlicht_V "Anforderung Innenlicht vorne";
CM_ SG_ 1524 BCM1_Leselicht_Anf_hl " Leselicht hinten links Anforderung";
CM_ SG_ 1524 BCM1_Leselicht_Anf_hr "Leselicht hinten rechts Anforderung";
CM_ SG_ 1524 BCM1_Leselicht_Anf_vl "Leselicht vorne links Anforderung";
CM_ SG_ 1524 BCM1_Leselicht_Anf_vr "Leselicht vorne rechts Anforderung";
CM_ SG_ 1524 BCM1_Leuchten_Aus "Innenbeleuchtung ausschalten (keine Änderung / ausschalten)";
CM_ SG_ 1524 IL_Bel_BFS_Ausstieg "Einschalten der Ausstiegsleuchten oder Türwarnleuchten in Tür oder im Schweller";
CM_ SG_ 1524 IL_Bel_FS_Ausstieg "Einschalten der Ausstiegsleuchten oder Türwarnleuchten in Tür oder im Schweller";
CM_ SG_ 1524 IL_Bel_HBFS_Ausstieg "Einschalten der Ausstiegsleuchten oder Türwarnleuchten in Tür oder im Schweller";
CM_ SG_ 1524 IL_Bel_HFS_Ausstieg "Einschalten der Ausstiegsleuchten oder Türwarnleuchten in Tür oder im Schweller";
CM_ SG_ 1524 IL_Dimmung_H_Tuerkontur "Dimmung Türkontur hinten (bei Änderung im 30 ms Raster)";
CM_ SG_ 1524 IL_Dimmung_Lautspr "Dimmung Umfeldbeleuchtung an Türaußenseite oder Außenspiegel";
CM_ SG_ 1524 IL_Dimmung_Tuerinnengriff "Dimmung Türinnengriff";
CM_ SG_ 1524 IL_Dimmung_Umfeldbel "Dimmung Umfeldbeleuchtung an Türaußenseite oder Außenspiegel";
CM_ SG_ 1524 IL_Dimmung_V_Tuerkontur "Dimmung Türkontur vorne (bei Änderung im 30 ms Raster)";
CM_ SG_ 1524 IL_Innenlicht_aktiv "Status Innenlicht";
CM_ SG_ 1524 IL_Klemme_30G_aktiv "Synchrones Abschalten";

CM_ SG_ 312 IPA_01_BZ "Fehlende Beschreibung (Import)
Botschaft asynchron geroutet. Zählerwert kann springen.";
CM_ SG_ 312 IPA_01_CRC "Für MLB:
'Berechnung siehe Lastenheft 'Kommunikationsabsicherung für FlexRay und CAN''

Ab MQB und MLBevo:
'Berechnung siehe Lastenheft 'End-to-End Kommunikationsabsicherung''

Endwerte siehe Begleitdokument 'S-PDU Kennungsfolgen'";
CM_ SG_ 312 IPA_Anforderung_HMS "Anforderung vom IPA (Intelligent Park Assist) an das HMS (Haltemanagement System)";
CM_ SG_ 312 IPA_APS_LED "Ansteuerung der APS Funktions-LED durch das BCM.
0 = LED aus
1 = LED ein
2 = LED blinken
3 = Funktion gesperrt, LED aus
4 = frei
5 = frei
6 = Init
7 = frei";
CM_ SG_ 312 IPA_Fahrstufenwunsch "Flankengesteuerter Fahrstufenwunsch von IPA/PiloPa an das Getriebe";
CM_ SG_ 312 IPA_Parken_beibehalten_HMS "Anforderung seitens Pilotiertem Parken bzw. Manövrierassistent das Lösen der EPB bzw. das Auslegen der Parksperre zu blockieren";
CM_ SG_ 312 IPA_PLA_LED "Ansteuerung der PLA Funktions-LED durch das BCM.
0 = LED aus
1 = LED ein
2 = LED blinken
3 = Funktion gesperrt, LED aus
4 = frei
5 = frei
6 = Init
7 = frei";
CM_ SG_ 312 IPA_Sollbeschleunigung "Anforderung vom IPA an den TSK, das Fahrzeug zu beschleunigen.";
CM_ SG_ 312 IPA_Status "Zustand der IPA-Statusmaschine";
CM_ SG_ 312 IPA_Status_IPA_GE "Statusinformation von IPA/PiloPa für Handshakemechanismus mit dem Getriebe-SG";
CM_ SG_ 312 IPA_Status_IPA_TSK "Statusinformation vom IPA für Handshakemechanismus mit TSK";
CM_ SG_ 312 Parken_aktives_System "Das Signal zeigt an, welches der Parksysteme auf dem zFAS gerade aktiv ist.";
CM_ SG_ 312 Parken_erhoehtes_Moment "Anforderung einer spezifizierten Motormomenten-Rampe seitens IPA/PiloPa für das Überfahren einer Schwelle oder eines Bordsteins.";
CM_ SG_ 312 Parken_Fahrbereitschaft_Anf "Anforderung seitens iPA/pilotiertes Parken, die Fahrbereitschaft aufrecht zu erhalten und das Verlassenskonzept im MSG beim „automatischen Parkvorgang“ zu deaktivieren.";
CM_ SG_ 312 Parken_Motorlauf_Anf "Anforderung Motorlauf seitens PiloPa";

CM_ SG_ 2527679583 Parken_Aktivierungslicht_Anf "Anforderung des Aktivierungslichts nach erfolgreicher Aktivierungshandlung seitens Pilotiertem Parken.";
CM_ SG_ 2527679583 Parken_Bestaetigungsblinken_Anf "Anforderung seitens Pilotiertem Parken für ein Erfolgsblinken nach dem Erreichen der Zielposition bzw. für ein Abbruchsblinken bei Eintreten einer Abbruchsbedingung.";
CM_ SG_ 2527679583 Parken_Fahrbereitschaftlicht_Anf "Anforderung des Fahrbereitschaftslichts";
CM_ SG_ 2527679583 Parken_Fahrerhinweise_Anf "Anforderung zur erneuten Lampenaufprüfung und Anzeige von Warnhinweisen nach einem pilotierten Ausparkvorgang.";
CM_ SG_ 2527679583 Parken_Fahrtrichtungslicht_Anf "Anforderung seitens Pilotiertem Parken für die Anzeige der initialen Fahrtrichtung nach Systemaktivierung.";
CM_ SG_ 2527679583 Parken_FFB_LED_Anf "Statusinformation des Pilotierten Parkens für die Ansteuerung der LED auf der Funkfernbedienung.";
CM_ SG_ 2527679583 Parken_Lichtnachlauf_Anf "Anforderung des Lichtnachlaufs beim BCM1 (analog Verlassenskonzept) für das Pilotierte Parken. ";
CM_ SG_ 2527679583 Parken_Schluesselsuche_Anf "Ansteuerung der Schlüsselsuche für das pilotierte Parken.";
CM_ SG_ 2527679583 Parken_Seitenspiegel_Anf "Anforderung für Seitenspiegel an- oder abklappen beim PiloPa";
CM_ SG_ 2527679583 Parken_Wegfahrsperren_Anf "Ansteuerung der Wegfahrsperren Komponenten für das pilotierte Parken.  ";
CM_ SG_ 2527679583 Parken_ZR_Sondermodus_Anf "Anforderung Sondermodus, um beim „pilotierten Parken“ spezielle Funktionsanpassungen im Infotainment-Bereich zu ermöglichen (u.a. schnellerer Startup, Abschaltung BT)";
CM_ SG_ 2527679583 Parken_ZV_Schliessen "Anforderung für Zentralverriegelung verriegeln oder safen beim PiloPa";

CM_ SG_ 1792 ISO_ALL_01_Req_Data "Funktionaler Request ALL";

CM_ SG_ 1862 ISO_Klima_Req_Data "Diagnose Request Klima Vorn";

CM_ SG_ 1968 ISO_Klima_Resp_Data "Diagnose Response Klima Vorn";

CM_ SG_ 1881 ISO_Lift_Req_Data "Diagnose Request Lift_VA";

CM_ SG_ 1987 ISO_Lift_Resp_Data "Diagnose Response Lift";

CM_ SG_ 2549874818 ISO_LCM_L_Req_Data "Diagnose Request Light Control Module links";

CM_ SG_ 2550005890 ISO_LCM_L_Resp_Data "Diagnose Response Light Control Module links";

CM_ SG_ 2549874819 ISO_LCM_R_Req_Data "Diagnose Request Light Control Module rechts";

CM_ SG_ 2550005891 ISO_LCM_R_Resp_Data "Diagnose Response Light Control Module rechts";

CM_ SG_ 2549874838 ISO_LED_LM_L_Req_Data "Diagnose Request Steuergeraet für LED-Scheinwerfer links";

CM_ SG_ 2550005910 ISO_LED_LM_L_Resp_Data "Diagnose Response Steuergeraet für LED-Scheinwerfer links";

CM_ SG_ 2549874839 ISO_LED_LM_R_Req_Data "Diagnose Request Steuergeraet für LED-Scheinwerfer rechts";

CM_ SG_ 2550005911 ISO_LED_LM_R_Resp_Data "Diagnose Response Steuergeraet für LED-Scheinwerfer rechts";

CM_ SG_ 2549874884 ISO_VAS_L_Req_Data "Diagnose Request Aussenspiegel links";

CM_ SG_ 2550005956 ISO_VAS_L_Resp_Data "Diagnose Response Aussenspiegel links";

CM_ SG_ 2549874885 ISO_VAS_R_Req_Data "Diagnose Request Aussenspiegel rechts";

CM_ SG_ 2550005957 ISO_VAS_R_Resp_Data "Diagnose Response Aussenspiegel rechts";

CM_ SG_ 2463978614 KAS_Anf_Bremsruck "Anforderung Warnruck";
CM_ SG_ 2463978614 KAS_Anf_OPS "Anforderung des OPS durch den Kreuzungsassistenten";
CM_ SG_ 2463978614 KAS_Anf_Prefill "Anforderung Prefill";
CM_ SG_ 2463978614 KAS_Anzeige_Info_links "Anzeige für Inforelevantes Objekt links";
CM_ SG_ 2463978614 KAS_Anzeige_Info_rechts "Anzeige für Inforelevantes Objekt rechts";
CM_ SG_ 2463978614 KAS_Anzeige_Warnung "Anzeige der Warnung";
CM_ SG_ 2463978614 KAS_Kritikalitaetslevel "Mit dem Signal wird das Kritikalitätslevel der Funktion KA dargestellt. Je höher das Kritikalitätslevel ist, desto höher die Wahrscheinlichkeit einer Kollision mit Querverkehr.
wird auch befüllt wenn KA vor Kunde deaktiviert ist.

Benötigt zur Kommunik";
CM_ SG_ 2463978614 KAS_PreSense_Modus_System "Signal zur Realisierung der BAP-Kommunikation für PreSense";
CM_ SG_ 2463978614 KAS_Status "Statusausgabe der Funktion";
CM_ SG_ 2463978614 KAS_Texte "Anzeige der KAS Texte";
CM_ SG_ 2463978614 KAS_Verfuegbarkeit "Signal zur Realisierung der BAP-Kommunikation für PreSense.
Kommunikation des Kreuzungsassistent (zFAS) mit dem BAP-Koordinator (SC).

Damit wird die Verfügbarkeit der Funktion KA übermittelt, um vor Kunde die Verfügbarkeit mindestens einer Funktion de";
CM_ SG_ 2463978614 KAS_Verz_Anf "Verzögerungsanforderung von KAS an VZM";

CM_ SG_ 497 FBS_Aktivierung_Pilot_Parken "Aktivierung der Funktion pilotiertes Parken";
CM_ SG_ 497 FFB_FDF_Taste "FDF Taste am Funkschluessel";
CM_ SG_ 497 FFB_Joker_Taste "Frei konfigurierbare Taste auf der Funkfernbedienung (für Verdecktaste, UGDO Taste).
";
CM_ SG_ 497 FFB_Park_Taste "Parktaste Funkschluessel";
CM_ SG_ 497 FFB_Remotestart_Taste "Remotestart Taste Funkschluessel";
CM_ SG_ 497 KY_Auf_Taste "Auf-Taste Funkschluessel";
CM_ SG_ 497 KY_Bereich "Schlüsselentfernung für Funktionen Annäherungslicht, automatisches Entriegeln";
CM_ SG_ 497 KY_BT_Entriegelung_Autorisiert "Erkennung / Authorisierung Keyless BT
";
CM_ SG_ 497 KY_BT_Verriegelung_Autorisiert "Authorisierung Verriegelungssensor Keyless BT
";
CM_ SG_ 497 KY_EasyClose_Abbruch "ID-Geber während HD-Zufahrt im Nahbereich EasyClose erkannt";
CM_ SG_ 497 KY_EasyClose_Status "Signal zur LED Ansteuerung im HD-Verriegelungstaster für die Funktion EasyClose.";
CM_ SG_ 497 KY_Front_Entr_Autorisiert "Erkennung / Authorisierung Keyless Front";
CM_ SG_ 497 KY_Front_Verr_Autorisiert "Authorisierung Verriegelungssensor Keyless Front";
CM_ SG_ 497 KY_FT_Entriegelung_Autorisiert "Erkennung / Authorisierung Keyless FT
";
CM_ SG_ 497 KY_FT_Verriegelung_Autorisiert "Authorisierung Verriegelungssensor Keyless FT
";
CM_ SG_ 497 KY_HBFS_Entriegelung_Autorisiert "Erkennung / Authorisierung Keyless HBFS
";
CM_ SG_ 497 KY_HBFS_Verriegelung_Autorisiert "Authorisierung Verriegelungssensor Keyless HBFS


";
CM_ SG_ 497 KY_HD_Auffahrt "Auffahrt HD nach Wiedereintritt ID-Geber in EasyClose Nahbereich";
CM_ SG_ 497 KY_HD_Entriegelung_Autorisiert "Erkennung / Authorisierung Keyless Heck
";
CM_ SG_ 497 KY_HD_Verriegelung_Autorisiert "Autorisierung der Schließanforderung über Verriegelungsinnentaster";
CM_ SG_ 497 KY_HD_Zufahrt "Zufahrt HD nach erfolgreicher Funktion EasyClose";
CM_ SG_ 497 KY_HDF_Taste "HDF Taste am Funkschluessel";
CM_ SG_ 497 KY_HFS_Entriegelung_Autorisiert "Erkennung / Authorisierung Keyless HFS
";
CM_ SG_ 497 KY_HFS_Verriegelung_Autorisiert "Authorisierung Verriegelungssensor Keyless HFS

";
CM_ SG_ 497 KY_IDG_in_Reichweite "Für elektrisch betätigte Türen und Klappen muss für eine Betätigung über Funk eine Reichweitenbegrenzung eingeführt werden. Diese Bit zeigt an, dass sich der Funkschlüssel innerhalb der geforderten Reichweite befindet";
CM_ SG_ 497 KY_LKL_1_Autorisierung "Schlüsselstatus für Anfragen der Ladeklappe 1";
CM_ SG_ 497 KY_LKL_2_Autorisierung "Schlüsselstatus für Anfragen der Ladeklappe 2";
CM_ SG_ 497 KY_Panik_Taste "Panik Taste Funkschluessel";
CM_ SG_ 497 KY_Position "Schlüsselposition für Funktionen Annäherungslicht, automatisches Entriegeln";
CM_ SG_ 497 KY_Schluessel_im_Fzg "Zeigt einen erkannten Schlüssel im Fzg an.";
CM_ SG_ 497 KY_Zu_Taste "Zu-Taste Funkschluessel";
CM_ SG_ 497 KY_ZV_Signatur "Signatur der ZV";
CM_ SG_ 497 Schluesselnr_Personalisierung "Signal gibt die jewels aktuelle Schlüsselnummer für die Personalisierung wieder";
BA_DEF_REL_ BU_SG_REL_  "GenSigTimeoutTime" INT 0 65535;
BA_DEF_ BO_  "DiagRequest" ENUM "No", "Yes";
BA_DEF_ BO_  "DiagResponse" ENUM "No", "Yes";
BA_DEF_ BO_  "DiagState" ENUM "No", "Yes";
BA_DEF_ BO_  "GenMsgChkConstant" HEX 0 4095;
BA_DEF_ BO_  "GenMsgCycleTime" INT 0 65535;
BA_DEF_ BO_  "GenMsgCycleTimeFast" INT 0 65535;
BA_DEF_ BO_  "GenMsgDelayTime" INT 0 100000;
BA_DEF_ BO_  "GenMsgILSupport" ENUM "No", "Yes";
BA_DEF_ BO_  "GenMsgNrOfRepetition" INT 0 100;
BA_DEF_ BO_  "GenMsgPDUConstants" STRING;
BA_DEF_ BO_  "GenMsgSendType" ENUM "Cyclic", "not_used", "not_used", "not_used", "not_used", "not_used", "not_used", "IfActive", "NoMsgSendType";
BA_DEF_ BO_  "GenMsgStartDelayTime" INT 0 100000;
BA_DEF_ BO_  "NmMessage" ENUM "No", "Yes";
BA_DEF_ BO_  "NmhMessage" ENUM "No", "Yes";
BA_DEF_ BO_  "MsgType" ENUM "Application", "NM ", "NMH", "TP2.0", "ISO-TP ", "BAP", "EID", "KS";
BA_DEF_ BO_  "VAGTP20_API" HEX 0 255;
BA_DEF_ BO_  "VAGTP20_DynConnection" ENUM "No", "Yes";
BA_DEF_ BO_  "VAGTP20_DynSetup" ENUM "No", "Yes";
BA_DEF_ BO_  "VAGTP20_StatConnection" ENUM "No", "Yes";
BA_DEF_ SG_  "GenSigActiveRepetitions" INT -2147483648 2147483647;
BA_DEF_ SG_  "GenSigInactiveValue" INT -2147483648 2147483647;
BA_DEF_ SG_  "GenSigSendType" ENUM "Cyclic", "OnWrite", "OnWriteWithRepetition", "OnChange", "OnChangeWithRepetition", "IfActive", "IfActiveWithRepetition", "NoSigSendType", "OnChangeAndIfActive", "OnChangeAndIfActiveWithRepetition";
BA_DEF_ SG_  "GenSigStartValue" INT -2147483648 2147483647;
BA_DEF_ SG_  "NWM-WakeupAllowed" ENUM "No", "Yes";
BA_DEF_ SG_  "GenSigFuncType" ENUM "NoFunction", "MsgCounter", "CRC-8", "XOR", "XOR-2", "DatedBit", "SW-Kl15", "CHK", "Constant", "Protocol", "CRC-8-SAE_J1850";
BA_DEF_ SG_  "GenSigSwitchedByIgnition" ENUM "No", "Yes";
BA_DEF_ SG_  "Fehlerwert" HEX 0 2147483647;
BA_DEF_ SG_  "GenSigMissingSourceValue" HEX 0 2147483647;
BA_DEF_DEF_REL_  "GenSigTimeoutTime" 0;
BA_DEF_DEF_  "DiagRequest" "No";
BA_DEF_DEF_  "DiagResponse" "No";
BA_DEF_DEF_  "DiagState" "No";
BA_DEF_DEF_  "GenMsgChkConstant" 0;
BA_DEF_DEF_  "GenMsgCycleTime" 0;
BA_DEF_DEF_  "GenMsgCycleTimeFast" 0;
BA_DEF_DEF_  "GenMsgDelayTime" 0;
BA_DEF_DEF_  "GenMsgILSupport" "No";
BA_DEF_DEF_  "GenMsgNrOfRepetition" 0;
BA_DEF_DEF_  "GenMsgPDUConstants" "";
BA_DEF_DEF_  "GenMsgSendType" "NoMsgSendType";
BA_DEF_DEF_  "GenMsgStartDelayTime" 0;
BA_DEF_DEF_  "NmMessage" "No";
BA_DEF_DEF_  "NmhMessage" "No";
BA_DEF_DEF_  "MsgType" "Application";
BA_DEF_DEF_  "VAGTP20_API" 0;
BA_DEF_DEF_  "VAGTP20_DynConnection" "No";
BA_DEF_DEF_  "VAGTP20_DynSetup" "No";
BA_DEF_DEF_  "VAGTP20_StatConnection" "No";
BA_DEF_DEF_  "GenSigActiveRepetitions" 0;
BA_DEF_DEF_  "GenSigInactiveValue" 0;
BA_DEF_DEF_  "GenSigSendType" "NoSigSendType";
BA_DEF_DEF_  "GenSigStartValue" 0;
BA_DEF_DEF_  "NWM-WakeupAllowed" "No";
BA_DEF_DEF_  "GenSigFuncType" "NoFunction";
BA_DEF_DEF_  "GenSigSwitchedByIgnition" "Yes";
BA_DEF_DEF_  "Fehlerwert" 0;
BA_DEF_DEF_  "GenSigMissingSourceValue" 0;
BA_ "GenMsgCycleTime" BO_ 427 200;
BA_ "GenMsgDelayTime" BO_ 427 20;
BA_ "GenMsgILSupport" BO_ 427 1;
BA_ "GenMsgPDUConstants" BO_ 427 "0x13,0x21,0x9b,0x6a,0x9a,0x62,0xd4,0x65,0x18,0xf1,0xab,0x16,0x32,0x89,0xe7,0x26";
BA_ "GenMsgSendType" BO_ 427 0;
BA_ "GenMsgChkConstant" BO_ 264 9;
BA_ "GenMsgCycleTime" BO_ 264 20;
BA_ "GenMsgILSupport" BO_ 264 1;
BA_ "GenMsgPDUConstants" BO_ 264 "0x09,0x09,0x09,0x09,0x09,0x09,0x09,0x09,0x09,0x09,0x09,0x09,0x09,0x09,0x09,0x09";
BA_ "GenMsgSendType" BO_ 264 0;
BA_ "GenMsgCycleTime" BO_ 429 1000;
BA_ "GenMsgDelayTime" BO_ 429 40;
BA_ "GenMsgILSupport" BO_ 429 1;
BA_ "GenMsgPDUConstants" BO_ 429 "0x40,0x7a,0x23,0x13,0x03,0xf4,0xf8,0xe5,0x97,0xc9,0xd6,0x07,0x47,0x21,0x66,0xdd";
BA_ "GenMsgSendType" BO_ 429 0;
BA_ "GenMsgCycleTime" BO_ 1605 1000;
BA_ "GenMsgDelayTime" BO_ 1605 20;
BA_ "GenMsgILSupport" BO_ 1605 1;
BA_ "GenMsgSendType" BO_ 1605 0;
BA_ "GenMsgCycleTime" BO_ 2589283684 960;
BA_ "GenMsgDelayTime" BO_ 2589283684 320;
BA_ "GenMsgILSupport" BO_ 2589283684 1;
BA_ "GenMsgSendType" BO_ 2589283684 0;
BA_ "GenMsgILSupport" BO_ 2549875470 1;
BA_ "MsgType" BO_ 2549875470 4;
BA_ "GenMsgILSupport" BO_ 2550006542 1;
BA_ "MsgType" BO_ 2550006542 4;
BA_ "GenMsgCycleTime" BO_ 1523 200;
BA_ "GenMsgILSupport" BO_ 1523 1;
BA_ "GenMsgSendType" BO_ 1523 0;
BA_ "GenMsgCycleTime" BO_ 173 100;
BA_ "GenMsgDelayTime" BO_ 173 10;
BA_ "GenMsgILSupport" BO_ 173 1;
BA_ "GenMsgPDUConstants" BO_ 173 "0x3f,0x69,0x39,0xdc,0x94,0xf9,0x14,0x64,0xd8,0x6a,0x34,0xce,0xa2,0x55,0xb5,0x2c";
BA_ "GenMsgSendType" BO_ 173 0;
BA_ "GenMsgCycleTime" BO_ 177 500;
BA_ "GenMsgDelayTime" BO_ 177 10;
BA_ "GenMsgILSupport" BO_ 177 1;
BA_ "GenMsgPDUConstants" BO_ 177 "0xe1,0x9e,0xc2,0xe9,0x48,0x98,0xf5,0xb6,0x47,0x83,0x26,0x45,0x9a,0x10,0x7b,0x1c";
BA_ "GenMsgSendType" BO_ 177 0;
BA_ "GenMsgChkConstant" BO_ 310 55;
BA_ "GenMsgCycleTime" BO_ 310 10;
BA_ "GenMsgILSupport" BO_ 310 1;
BA_ "GenMsgPDUConstants" BO_ 310 "0x37,0x37,0x37,0x37,0x37,0x37,0x37,0x37,0x37,0x37,0x37,0x37,0x37,0x37,0x37,0x37";
BA_ "GenMsgSendType" BO_ 310 0;
BA_ "GenMsgCycleTime" BO_ 676 40;
BA_ "GenMsgILSupport" BO_ 676 1;
BA_ "GenMsgPDUConstants" BO_ 676 "0x42,0x54,0xd5,0x29,0xcc,0x16,0x4d,0xa8,0xd4,0xed,0x7c,0x21,0xdb,0x6b,0xe6,0x5a";
BA_ "GenMsgSendType" BO_ 676 0;
BA_ "GenMsgCycleTime" BO_ 1410 200;
BA_ "GenMsgDelayTime" BO_ 1410 20;
BA_ "GenMsgILSupport" BO_ 1410 1;
BA_ "GenMsgSendType" BO_ 1410 0;
BA_ "GenMsgCycleTime" BO_ 1416 500;
BA_ "GenMsgDelayTime" BO_ 1416 50;
BA_ "GenMsgILSupport" BO_ 1416 1;
BA_ "GenMsgSendType" BO_ 1416 0;
BA_ "GenMsgCycleTime" BO_ 1016 500;
BA_ "GenMsgDelayTime" BO_ 1016 50;
BA_ "GenMsgILSupport" BO_ 1016 1;
BA_ "GenMsgSendType" BO_ 1016 0;
BA_ "GenMsgStartDelayTime" BO_ 1016 70;
BA_ "GenMsgCycleTime" BO_ 1283 100;
BA_ "GenMsgDelayTime" BO_ 1283 10;
BA_ "GenMsgILSupport" BO_ 1283 1;
BA_ "GenMsgPDUConstants" BO_ 1283 "0xed,0xd6,0x96,0x63,0xa5,0x12,0xd5,0x9a,0x1e,0x0d,0x24,0xcd,0x8c,0xa6,0x2f,0x41";
BA_ "GenMsgSendType" BO_ 1283 0;
BA_ "GenMsgCycleTime" BO_ 1381 100;
BA_ "GenMsgDelayTime" BO_ 1381 50;
BA_ "GenMsgILSupport" BO_ 1381 1;
BA_ "GenMsgSendType" BO_ 1381 0;
BA_ "GenMsgCycleTime" BO_ 1340 100;
BA_ "GenMsgILSupport" BO_ 1340 1;
BA_ "GenMsgPDUConstants" BO_ 1340 "0x8e,0xf9,0xe1,0x2e,0x83,0x34,0xd0,0xf1,0xaa,0x2c,0xbb,0x81,0x17,0x60,0x11,0x37";
BA_ "GenMsgSendType" BO_ 1340 0;
BA_ "GenMsgCycleTime" BO_ 2589283485 2000;
BA_ "GenMsgDelayTime" BO_ 2589283485 200;
BA_ "GenMsgILSupport" BO_ 2589283485 1;
BA_ "GenMsgSendType" BO_ 2589283485 0;
BA_ "GenMsgCycleTime" BO_ 2463978610 500;
BA_ "GenMsgDelayTime" BO_ 2463978610 10;
BA_ "GenMsgILSupport" BO_ 2463978610 1;
BA_ "GenMsgSendType" BO_ 2463978610 0;
BA_ "GenMsgCycleTime" BO_ 1524 500;
BA_ "GenMsgDelayTime" BO_ 1524 50;
BA_ "GenMsgILSupport" BO_ 1524 1;
BA_ "GenMsgSendType" BO_ 1524 0;
BA_ "GenMsgCycleTime" BO_ 312 200;
BA_ "GenMsgDelayTime" BO_ 312 20;
BA_ "GenMsgILSupport" BO_ 312 1;
BA_ "GenMsgPDUConstants" BO_ 312 "0x77,0x4e,0x14,0x87,0xf2,0xf8,0xb2,0x61,0xf6,0xa4,0x52,0x94,0xd4,0x81,0x2a,0xb1";
BA_ "GenMsgSendType" BO_ 312 0;
BA_ "GenMsgCycleTime" BO_ 2527679583 960;
BA_ "GenMsgCycleTimeFast" BO_ 2527679583 160;
BA_ "GenMsgDelayTime" BO_ 2527679583 80;
BA_ "GenMsgILSupport" BO_ 2527679583 1;
BA_ "GenMsgNrOfRepetition" BO_ 2527679583 5;
BA_ "GenMsgSendType" BO_ 2527679583 0;
BA_ "DiagRequest" BO_ 1806 1;
BA_ "MsgType" BO_ 1806 4;
BA_ "DiagResponse" BO_ 1912 1;
BA_ "MsgType" BO_ 1912 4;
BA_ "DiagState" BO_ 1792 1;
BA_ "MsgType" BO_ 1792 4;
BA_ "DiagRequest" BO_ 1862 1;
BA_ "MsgType" BO_ 1862 4;
BA_ "DiagResponse" BO_ 1968 1;
BA_ "MsgType" BO_ 1968 4;
BA_ "DiagRequest" BO_ 1881 1;
BA_ "MsgType" BO_ 1881 4;
BA_ "DiagResponse" BO_ 1987 1;
BA_ "MsgType" BO_ 1987 4;
BA_ "DiagRequest" BO_ 2549874818 1;
BA_ "MsgType" BO_ 2549874818 4;
BA_ "DiagResponse" BO_ 2550005890 1;
BA_ "MsgType" BO_ 2550005890 4;
BA_ "DiagRequest" BO_ 2549874819 1;
BA_ "MsgType" BO_ 2549874819 4;
BA_ "DiagResponse" BO_ 2550005891 1;
BA_ "MsgType" BO_ 2550005891 4;
BA_ "DiagRequest" BO_ 2549874838 1;
BA_ "MsgType" BO_ 2549874838 4;
BA_ "DiagResponse" BO_ 2550005910 1;
BA_ "MsgType" BO_ 2550005910 4;
BA_ "DiagRequest" BO_ 2549874839 1;
BA_ "MsgType" BO_ 2549874839 4;
BA_ "DiagResponse" BO_ 2550005911 1;
BA_ "MsgType" BO_ 2550005911 4;
BA_ "DiagRequest" BO_ 2549874884 1;
BA_ "MsgType" BO_ 2549874884 4;
BA_ "DiagResponse" BO_ 2550005956 1;
BA_ "MsgType" BO_ 2550005956 4;
BA_ "DiagRequest" BO_ 2549874885 1;
BA_ "MsgType" BO_ 2549874885 4;
BA_ "DiagResponse" BO_ 2550005957 1;
BA_ "MsgType" BO_ 2550005957 4;
BA_ "GenMsgCycleTime" BO_ 2463978614 200;
BA_ "GenMsgDelayTime" BO_ 2463978614 20;
BA_ "GenMsgILSupport" BO_ 2463978614 1;
BA_ "GenMsgSendType" BO_ 2463978614 0;
BA_ "GenMsgCycleTime" BO_ 497 500;
BA_ "GenMsgCycleTimeFast" BO_ 497 40;
BA_ "GenMsgDelayTime" BO_ 497 20;
BA_ "GenMsgILSupport" BO_ 497 1;
BA_ "GenMsgNrOfRepetition" BO_ 497 7;
BA_ "GenMsgSendType" BO_ 497 0;
BA_ "GenSigSendType" SG_ 427 ESC_AHW_aktiv 3;
BA_ "GenSigSwitchedByIgnition" SG_ 427 ESC_AHW_aktiv 0;
BA_ "GenSigSendType" SG_ 427 ESC_AHW_nicht_verfuegbar 3;
BA_ "GenSigSwitchedByIgnition" SG_ 427 ESC_AHW_nicht_verfuegbar 0;
BA_ "GenSigSendType" SG_ 427 ESC_ANB_CM_aktiv 0;
BA_ "GenSigSwitchedByIgnition" SG_ 427 ESC_ANB_CM_aktiv 0;
BA_ "GenSigSendType" SG_ 427 ESC_ANB_CM_nicht_verfuegbar 0;
BA_ "GenSigSwitchedByIgnition" SG_ 427 ESC_ANB_CM_nicht_verfuegbar 0;
BA_ "GenSigSendType" SG_ 427 ESC_Bremslicht_unplausibel 3;
BA_ "GenSigSwitchedByIgnition" SG_ 427 ESC_Bremslicht_unplausibel 0;
BA_ "GenSigSendType" SG_ 427 ESC_Fahrer_Bremsdruck_bestimmend 0;
BA_ "GenSigSwitchedByIgnition" SG_ 427 ESC_Fahrer_Bremsdruck_bestimmend 0;
BA_ "GenSigSendType" SG_ 427 ESC_HBA_aktiv 3;
BA_ "GenSigSwitchedByIgnition" SG_ 427 ESC_HBA_aktiv 0;
BA_ "GenSigSendType" SG_ 427 ESC_HBA_nicht_verfuegbar 3;
BA_ "GenSigSwitchedByIgnition" SG_ 427 ESC_HBA_nicht_verfuegbar 0;
BA_ "GenSigSendType" SG_ 427 ESC_Konsistenz_ACC 0;
BA_ "GenSigSwitchedByIgnition" SG_ 427 ESC_Konsistenz_ACC 0;
BA_ "GenSigSendType" SG_ 427 ESC_Konsistenz_AGW 0;
BA_ "GenSigSwitchedByIgnition" SG_ 427 ESC_Konsistenz_AGW 0;
BA_ "GenSigSendType" SG_ 427 ESC_Konsistenz_ARA 3;
BA_ "GenSigSwitchedByIgnition" SG_ 427 ESC_Konsistenz_ARA 0;
BA_ "GenSigSendType" SG_ 427 ESC_Konsistenz_AWA 0;
BA_ "GenSigSwitchedByIgnition" SG_ 427 ESC_Konsistenz_AWA 0;
BA_ "GenSigSendType" SG_ 427 ESC_Konsistenz_AWV 0;
BA_ "GenSigSwitchedByIgnition" SG_ 427 ESC_Konsistenz_AWV 0;
BA_ "GenSigSendType" SG_ 427 ESC_Konsistenz_BFF 0;
BA_ "GenSigSwitchedByIgnition" SG_ 427 ESC_Konsistenz_BFF 0;
BA_ "GenSigSendType" SG_ 427 ESC_Konsistenz_EA 0;
BA_ "GenSigSwitchedByIgnition" SG_ 427 ESC_Konsistenz_EA 0;
BA_ "GenSigSendType" SG_ 427 ESC_Konsistenz_FAS_VK 0;
BA_ "GenSigSwitchedByIgnition" SG_ 427 ESC_Konsistenz_FAS_VK 0;
BA_ "GenSigSendType" SG_ 427 ESC_Konsistenz_FCW 0;
BA_ "GenSigSwitchedByIgnition" SG_ 427 ESC_Konsistenz_FCW 0;
BA_ "GenSigSendType" SG_ 427 ESC_Konsistenz_IPA 0;
BA_ "GenSigSwitchedByIgnition" SG_ 427 ESC_Konsistenz_IPA 0;
BA_ "GenSigSendType" SG_ 427 ESC_Konsistenz_KAS 0;
BA_ "GenSigSwitchedByIgnition" SG_ 427 ESC_Konsistenz_KAS 0;
BA_ "GenSigSendType" SG_ 427 ESC_Konsistenz_MKB 0;
BA_ "GenSigSwitchedByIgnition" SG_ 427 ESC_Konsistenz_MKB 0;
BA_ "GenSigSendType" SG_ 427 ESC_Konsistenz_NV 3;
BA_ "GenSigSwitchedByIgnition" SG_ 427 ESC_Konsistenz_NV 0;
BA_ "GenSigSendType" SG_ 427 ESC_Konsistenz_PCF 0;
BA_ "GenSigSwitchedByIgnition" SG_ 427 ESC_Konsistenz_PCF 0;
BA_ "GenSigSendType" SG_ 427 ESC_Konsistenz_RCTA 3;
BA_ "GenSigSwitchedByIgnition" SG_ 427 ESC_Konsistenz_RCTA 0;
BA_ "GenSigSendType" SG_ 427 ESC_Konsistenz_STA 0;
BA_ "GenSigSwitchedByIgnition" SG_ 427 ESC_Konsistenz_STA 0;
BA_ "GenSigSendType" SG_ 427 ESC_Konsistenz_TSK 0;
BA_ "GenSigSwitchedByIgnition" SG_ 427 ESC_Konsistenz_TSK 0;
BA_ "GenSigSendType" SG_ 427 ESC_Konsistenz_vFGS 0;
BA_ "GenSigSwitchedByIgnition" SG_ 427 ESC_Konsistenz_vFGS 0;
BA_ "GenSigSendType" SG_ 427 ESC_Prefill_aktiv 3;
BA_ "GenSigSwitchedByIgnition" SG_ 427 ESC_Prefill_aktiv 0;
BA_ "GenSigSendType" SG_ 427 ESC_Prefill_nicht_verfuegbar 3;
BA_ "GenSigSwitchedByIgnition" SG_ 427 ESC_Prefill_nicht_verfuegbar 0;
BA_ "GenSigSendType" SG_ 427 ESC_Pumpenanlauf_aktiv 0;
BA_ "GenSigSwitchedByIgnition" SG_ 427 ESC_Pumpenanlauf_aktiv 0;
BA_ "GenSigSendType" SG_ 427 ESC_TSK_SRBM_Anf 0;
BA_ "GenSigSwitchedByIgnition" SG_ 427 ESC_TSK_SRBM_Anf 0;
BA_ "GenSigSendType" SG_ 427 ESC_TSK_SRBM_nicht_verfuegbar 0;
BA_ "GenSigSwitchedByIgnition" SG_ 427 ESC_TSK_SRBM_nicht_verfuegbar 0;
BA_ "GenSigSendType" SG_ 427 ESC_Verz_ASIL_Verfuegbarkeit 0;
BA_ "GenSigSwitchedByIgnition" SG_ 427 ESC_Verz_ASIL_Verfuegbarkeit 0;
BA_ "GenSigSendType" SG_ 427 ESC_Verz_Begrenzung 0;
BA_ "GenSigSwitchedByIgnition" SG_ 427 ESC_Verz_Begrenzung 0;
BA_ "GenSigSendType" SG_ 427 ESC_Verz_Reg_aktiv 3;
BA_ "GenSigSwitchedByIgnition" SG_ 427 ESC_Verz_Reg_aktiv 0;
BA_ "GenSigSendType" SG_ 427 ESC_Verz_Reg_nicht_verfuegbar 0;
BA_ "GenSigSwitchedByIgnition" SG_ 427 ESC_Verz_Reg_nicht_verfuegbar 0;
BA_ "GenSigSendType" SG_ 427 ESC_Verz_Reg_TB_nicht_verfuegbar 0;
BA_ "GenSigSwitchedByIgnition" SG_ 427 ESC_Verz_Reg_TB_nicht_verfuegbar 0;
BA_ "GenSigSendType" SG_ 427 ESC_Verz_Reg_ZB_nicht_verfuegbar 0;
BA_ "GenSigSwitchedByIgnition" SG_ 427 ESC_Verz_Reg_ZB_nicht_verfuegbar 0;
BA_ "GenSigSendType" SG_ 427 ESC_Warnruck_aktiv 3;
BA_ "GenSigSwitchedByIgnition" SG_ 427 ESC_Warnruck_aktiv 0;
BA_ "GenSigSendType" SG_ 427 ESC_Warnruck_nicht_verfuegbar 3;
BA_ "GenSigSwitchedByIgnition" SG_ 427 ESC_Warnruck_nicht_verfuegbar 0;
BA_ "GenSigSendType" SG_ 427 ESP_33_BZ 0;
BA_ "GenSigFuncType" SG_ 427 ESP_33_BZ 1;
BA_ "GenSigSwitchedByIgnition" SG_ 427 ESP_33_BZ 0;
BA_ "GenSigSendType" SG_ 427 ESP_33_CRC 0;
BA_ "GenSigFuncType" SG_ 427 ESP_33_CRC 2;
BA_ "GenSigSwitchedByIgnition" SG_ 427 ESP_33_CRC 0;
BA_ "GenSigSendType" SG_ 264 FA_Fahrbahnunebenheit 0;
BA_ "GenSigStartValue" SG_ 264 FA_Fahrbahnunebenheit 254;
BA_ "GenSigSwitchedByIgnition" SG_ 264 FA_Fahrbahnunebenheit 0;
BA_ "Fehlerwert" SG_ 264 FA_Fahrbahnunebenheit 255;
BA_ "GenSigSendType" SG_ 264 FA_Hoehenwert_HL_00 0;
BA_ "GenSigStartValue" SG_ 264 FA_Hoehenwert_HL_00 254;
BA_ "Fehlerwert" SG_ 264 FA_Hoehenwert_HL_00 255;
BA_ "GenSigSendType" SG_ 264 FA_Hoehenwert_HR_00 0;
BA_ "GenSigStartValue" SG_ 264 FA_Hoehenwert_HR_00 254;
BA_ "Fehlerwert" SG_ 264 FA_Hoehenwert_HR_00 255;
BA_ "GenSigSendType" SG_ 264 FA_Hoehenwert_VL_00 0;
BA_ "GenSigStartValue" SG_ 264 FA_Hoehenwert_VL_00 254;
BA_ "Fehlerwert" SG_ 264 FA_Hoehenwert_VL_00 255;
BA_ "GenSigSendType" SG_ 264 FA_Hoehenwert_VR_00 0;
BA_ "GenSigStartValue" SG_ 264 FA_Hoehenwert_VR_00 254;
BA_ "Fehlerwert" SG_ 264 FA_Hoehenwert_VR_00 255;
BA_ "GenSigSendType" SG_ 264 FA_Hoehenwerte_kalibriert 0;
BA_ "GenSigSendType" SG_ 264 Fahrwerk_01_BZ 0;
BA_ "GenSigFuncType" SG_ 264 Fahrwerk_01_BZ 1;
BA_ "GenSigSendType" SG_ 264 Fahrwerk_01_CRC 0;
BA_ "GenSigFuncType" SG_ 264 Fahrwerk_01_CRC 2;
BA_ "GenSigSendType" SG_ 429 EFP_Soll_FahrPr_HAL 0;
BA_ "GenSigSwitchedByIgnition" SG_ 429 EFP_Soll_FahrPr_HAL 0;
BA_ "GenSigSendType" SG_ 429 FA_Absenkung_Fahrzeug 0;
BA_ "GenSigSwitchedByIgnition" SG_ 429 FA_Absenkung_Fahrzeug 0;
BA_ "GenSigSendType" SG_ 429 FA_Anhaengerstatus_intern 0;
BA_ "GenSigSwitchedByIgnition" SG_ 429 FA_Anhaengerstatus_intern 0;
BA_ "GenSigSendType" SG_ 429 FA_Anhebung_Fahrzeug 0;
BA_ "GenSigSwitchedByIgnition" SG_ 429 FA_Anhebung_Fahrzeug 0;
BA_ "GenSigSendType" SG_ 429 FA_Druckspeicher_verfuegbar 0;
BA_ "GenSigSwitchedByIgnition" SG_ 429 FA_Druckspeicher_verfuegbar 0;
BA_ "GenSigSendType" SG_ 429 FA_ESP_Zuschaltung 0;
BA_ "GenSigSendType" SG_ 429 FA_HAL_Abschaltung 0;
BA_ "GenSigSwitchedByIgnition" SG_ 429 FA_HAL_Abschaltung 0;
BA_ "GenSigSendType" SG_ 429 FA_Kompressor_laeuft 0;
BA_ "GenSigSwitchedByIgnition" SG_ 429 FA_Kompressor_laeuft 0;
BA_ "GenSigSendType" SG_ 429 FA_Kompressor_laeuft_in_Kuerze 0;
BA_ "GenSigSwitchedByIgnition" SG_ 429 FA_Kompressor_laeuft_in_Kuerze 0;
BA_ "GenSigSendType" SG_ 429 FA_Signal_Drucksensor 0;
BA_ "GenSigStartValue" SG_ 429 FA_Signal_Drucksensor 254;
BA_ "GenSigSwitchedByIgnition" SG_ 429 FA_Signal_Drucksensor 0;
BA_ "Fehlerwert" SG_ 429 FA_Signal_Drucksensor 255;
BA_ "GenSigSendType" SG_ 429 FA_Systemstatus 0;
BA_ "GenSigSwitchedByIgnition" SG_ 429 FA_Systemstatus 0;
BA_ "GenSigSendType" SG_ 429 FA_Verstellung_aktiv 0;
BA_ "GenSigSwitchedByIgnition" SG_ 429 FA_Verstellung_aktiv 0;
BA_ "GenSigSendType" SG_ 429 FA_Verstellung_in_Kuerze 0;
BA_ "GenSigSwitchedByIgnition" SG_ 429 FA_Verstellung_in_Kuerze 0;
BA_ "GenSigSendType" SG_ 429 FA_Zwischenniveau 0;
BA_ "GenSigSwitchedByIgnition" SG_ 429 FA_Zwischenniveau 0;
BA_ "GenSigSendType" SG_ 429 Fahrwerk_06_BZ 0;
BA_ "GenSigFuncType" SG_ 429 Fahrwerk_06_BZ 1;
BA_ "GenSigSwitchedByIgnition" SG_ 429 Fahrwerk_06_BZ 0;
BA_ "GenSigSendType" SG_ 429 Fahrwerk_06_CRC 0;
BA_ "GenSigFuncType" SG_ 429 Fahrwerk_06_CRC 2;
BA_ "GenSigSwitchedByIgnition" SG_ 429 Fahrwerk_06_CRC 0;
BA_ "GenSigSendType" SG_ 429 NR_Anforderung_v_Begrenzung 0;
BA_ "GenSigSwitchedByIgnition" SG_ 429 NR_Anforderung_v_Begrenzung 0;
BA_ "GenSigSendType" SG_ 429 NR_Kompressor_Strom_02 0;
BA_ "Fehlerwert" SG_ 429 NR_Kompressor_Strom_02 255;
BA_ "GenSigSendType" SG_ 429 NR_Kompressor_Temp_Zylinderkopf 0;
BA_ "GenSigStartValue" SG_ 429 NR_Kompressor_Temp_Zylinderkopf 254;
BA_ "Fehlerwert" SG_ 429 NR_Kompressor_Temp_Zylinderkopf 255;
BA_ "GenSigSendType" SG_ 429 NR_LED_BN 3;
BA_ "GenSigSwitchedByIgnition" SG_ 429 NR_LED_BN 0;
BA_ "GenSigSendType" SG_ 429 NR_LED_HN 3;
BA_ "GenSigSwitchedByIgnition" SG_ 429 NR_LED_HN 0;
BA_ "GenSigSendType" SG_ 429 NR_LED_SGN 3;
BA_ "GenSigSwitchedByIgnition" SG_ 429 NR_LED_SGN 0;
BA_ "GenSigSendType" SG_ 429 NR_LED_TN 3;
BA_ "GenSigSwitchedByIgnition" SG_ 429 NR_LED_TN 0;
BA_ "GenSigSendType" SG_ 429 NR_Reglerstatus 3;
BA_ "GenSigSwitchedByIgnition" SG_ 429 NR_Reglerstatus 0;
BA_ "GenSigSendType" SG_ 1605 FLA_Abblendursache 3;
BA_ "Fehlerwert" SG_ 1605 FLA_Abblendursache 255;
BA_ "GenSigSendType" SG_ 1605 FLA_aktiv 3;
BA_ "GenSigSendType" SG_ 1605 FLA_Aufblenden 3;
BA_ "GenSigSendType" SG_ 1605 FLA_Fernlicht_PWM 3;
BA_ "GenSigStartValue" SG_ 1605 FLA_Fernlicht_PWM 100;
BA_ "Fehlerwert" SG_ 1605 FLA_Fernlicht_PWM 127;
BA_ "GenSigSendType" SG_ 1605 FLA_ISP_defekt 3;
BA_ "GenSigSendType" SG_ 1605 FLA_SAE_Mode 3;
BA_ "GenSigSendType" SG_ 1605 FLA_Sensor_blockiert 3;
BA_ "GenSigSendType" SG_ 1605 ISP_Dimmung_ASP_02 3;
BA_ "GenSigSendType" SG_ 1605 ISP_EC_aktiv 3;
BA_ "GenSigStartValue" SG_ 1605 ISP_EC_aktiv 1;
BA_ "GenSigSendType" SG_ 1605 ISP_EC_Lichtwert_hinten 3;
BA_ "GenSigStartValue" SG_ 1605 ISP_EC_Lichtwert_hinten 62;
BA_ "Fehlerwert" SG_ 1605 ISP_EC_Lichtwert_hinten 63;
BA_ "GenSigSendType" SG_ 1605 ISP_EC_Lichtwert_vorne 3;
BA_ "GenSigStartValue" SG_ 1605 ISP_EC_Lichtwert_vorne 62;
BA_ "Fehlerwert" SG_ 1605 ISP_EC_Lichtwert_vorne 63;
BA_ "GenSigSendType" SG_ 1605 ISP_Himmelsrichtung 3;
BA_ "GenSigStartValue" SG_ 1605 ISP_Himmelsrichtung 30;
BA_ "Fehlerwert" SG_ 1605 ISP_Himmelsrichtung 31;
BA_ "GenSigSendType" SG_ 1605 ISP_Kompass_aktiv 3;
BA_ "GenSigStartValue" SG_ 1605 ISP_Kompass_aktiv 1;
BA_ "GenSigSendType" SG_ 1605 ISP_Taste_betaetigt 3;
BA_ "GenSigSendType" SG_ 2589283684 FoD_Anz_Funktionsabschaltung 3;
BA_ "GenSigSwitchedByIgnition" SG_ 2589283684 FoD_Anz_Funktionsabschaltung 0;
BA_ "GenSigSendType" SG_ 2589283684 FoD_Transmission_Info 3;
BA_ "GenSigSwitchedByIgnition" SG_ 2589283684 FoD_Transmission_Info 0;
BA_ "GenSigSendType" SG_ 2549875470 FoD_BCM1_Req_Data 3;
BA_ "GenSigSwitchedByIgnition" SG_ 2549875470 FoD_BCM1_Req_Data 0;
BA_ "GenSigSendType" SG_ 2550006542 FoD_BCM1_Resp_Data 3;
BA_ "GenSigSwitchedByIgnition" SG_ 2550006542 FoD_BCM1_Resp_Data 0;
BA_ "GenSigSendType" SG_ 1523 Diag_Frontscheibe 0;
BA_ "GenSigSwitchedByIgnition" SG_ 1523 Diag_Frontscheibe 0;
BA_ "GenSigSendType" SG_ 1523 FSH_LED 0;
BA_ "GenSigSwitchedByIgnition" SG_ 1523 FSH_LED 0;
BA_ "GenSigSendType" SG_ 1523 FSW_Lokalaktiv 0;
BA_ "GenSigSwitchedByIgnition" SG_ 1523 FSW_Lokalaktiv 0;
BA_ "GenSigSendType" SG_ 1523 HW_SW_Frontscheibe 0;
BA_ "GenSigSwitchedByIgnition" SG_ 1523 HW_SW_Frontscheibe 0;
BA_ "GenSigSendType" SG_ 1523 I_Heiz_Frontscheibe 0;
BA_ "GenSigStartValue" SG_ 1523 I_Heiz_Frontscheibe 254;
BA_ "GenSigSwitchedByIgnition" SG_ 1523 I_Heiz_Frontscheibe 0;
BA_ "GenSigSendType" SG_ 1523 P_Heiz_Frontscheibe 0;
BA_ "GenSigStartValue" SG_ 1523 P_Heiz_Frontscheibe 254;
BA_ "GenSigSwitchedByIgnition" SG_ 1523 P_Heiz_Frontscheibe 0;
BA_ "GenSigSendType" SG_ 1523 R_grenz_max 0;
BA_ "GenSigStartValue" SG_ 1523 R_grenz_max 254;
BA_ "GenSigSwitchedByIgnition" SG_ 1523 R_grenz_max 0;
BA_ "GenSigSendType" SG_ 1523 R_grenz_min 0;
BA_ "GenSigStartValue" SG_ 1523 R_grenz_min 254;
BA_ "GenSigSwitchedByIgnition" SG_ 1523 R_grenz_min 0;
BA_ "GenSigSendType" SG_ 1523 R_ist 0;
BA_ "GenSigStartValue" SG_ 1523 R_ist 254;
BA_ "GenSigSwitchedByIgnition" SG_ 1523 R_ist 0;
BA_ "GenSigSendType" SG_ 173 GE_Fahrstufe 3;
BA_ "GenSigStartValue" SG_ 173 GE_Fahrstufe 1;
BA_ "GenSigSwitchedByIgnition" SG_ 173 GE_Fahrstufe 0;
BA_ "Fehlerwert" SG_ 173 GE_Fahrstufe 15;
BA_ "GenSigSendType" SG_ 173 GE_Freig_MMom_Vorhalt 0;
BA_ "GenSigSwitchedByIgnition" SG_ 173 GE_Freig_MMom_Vorhalt 0;
BA_ "GenSigSendType" SG_ 173 GE_MMom_Soll_02 0;
BA_ "GenSigStartValue" SG_ 173 GE_MMom_Soll_02 1022;
BA_ "GenSigSwitchedByIgnition" SG_ 173 GE_MMom_Soll_02 0;
BA_ "Fehlerwert" SG_ 173 GE_MMom_Soll_02 1023;
BA_ "GenSigSendType" SG_ 173 GE_MMom_Status 0;
BA_ "GenSigSwitchedByIgnition" SG_ 173 GE_MMom_Status 0;
BA_ "GenSigSendType" SG_ 173 GE_MMom_Status_02 0;
BA_ "GenSigSwitchedByIgnition" SG_ 173 GE_MMom_Status_02 0;
BA_ "GenSigSendType" SG_ 173 GE_MMom_Vorhalt_02 0;
BA_ "GenSigStartValue" SG_ 173 GE_MMom_Vorhalt_02 1022;
BA_ "GenSigSwitchedByIgnition" SG_ 173 GE_MMom_Vorhalt_02 0;
BA_ "Fehlerwert" SG_ 173 GE_MMom_Vorhalt_02 1023;
BA_ "GenSigSendType" SG_ 173 GE_reserv_Fahrstufe 0;
BA_ "GenSigSwitchedByIgnition" SG_ 173 GE_reserv_Fahrstufe 0;
BA_ "GenSigSendType" SG_ 173 GE_Schaltablauf 0;
BA_ "GenSigSwitchedByIgnition" SG_ 173 GE_Schaltablauf 0;
BA_ "GenSigSendType" SG_ 173 GE_Status_Kraftschluss 0;
BA_ "GenSigSwitchedByIgnition" SG_ 173 GE_Status_Kraftschluss 0;
BA_ "GenSigSendType" SG_ 173 GE_Uefkt 0;
BA_ "GenSigSwitchedByIgnition" SG_ 173 GE_Uefkt 0;
BA_ "Fehlerwert" SG_ 173 GE_Uefkt 1023;
BA_ "GenSigSendType" SG_ 173 GE_Uefkt_unplausibel 0;
BA_ "GenSigSwitchedByIgnition" SG_ 173 GE_Uefkt_unplausibel 0;
BA_ "GenSigSendType" SG_ 173 GE_Verbot_Ausblendung 0;
BA_ "GenSigSwitchedByIgnition" SG_ 173 GE_Verbot_Ausblendung 0;
BA_ "GenSigSendType" SG_ 173 GE_Zielgang 0;
BA_ "GenSigSwitchedByIgnition" SG_ 173 GE_Zielgang 0;
BA_ "Fehlerwert" SG_ 173 GE_Zielgang 15;
BA_ "GenSigSendType" SG_ 173 Getriebe_11_BZ 0;
BA_ "GenSigFuncType" SG_ 173 Getriebe_11_BZ 1;
BA_ "GenSigSwitchedByIgnition" SG_ 173 Getriebe_11_BZ 0;
BA_ "GenSigSendType" SG_ 173 Getriebe_11_CRC 0;
BA_ "GenSigFuncType" SG_ 173 Getriebe_11_CRC 2;
BA_ "GenSigSwitchedByIgnition" SG_ 173 Getriebe_11_CRC 0;
BA_ "GenSigSendType" SG_ 177 GE_Anschleppstart_Freigabe 0;
BA_ "GenSigSwitchedByIgnition" SG_ 177 GE_Anschleppstart_Freigabe 0;
BA_ "GenSigSendType" SG_ 177 GE_Eingangsdrehz_Praed 0;
BA_ "GenSigStartValue" SG_ 177 GE_Eingangsdrehz_Praed 16382;
BA_ "GenSigSwitchedByIgnition" SG_ 177 GE_Eingangsdrehz_Praed 0;
BA_ "Fehlerwert" SG_ 177 GE_Eingangsdrehz_Praed 16383;
BA_ "GenSigSendType" SG_ 177 GE_Fahrprogramm 0;
BA_ "GenSigSwitchedByIgnition" SG_ 177 GE_Fahrprogramm 0;
BA_ "GenSigSendType" SG_ 177 GE_Freilauf_Status 3;
BA_ "GenSigSwitchedByIgnition" SG_ 177 GE_Freilauf_Status 0;
BA_ "Fehlerwert" SG_ 177 GE_Freilauf_Status 7;
BA_ "GenSigSendType" SG_ 177 GE_Getriebestatus_02 0;
BA_ "GenSigSwitchedByIgnition" SG_ 177 GE_Getriebestatus_02 0;
BA_ "GenSigSendType" SG_ 177 GE_Grundeinstellung 0;
BA_ "GenSigSwitchedByIgnition" SG_ 177 GE_Grundeinstellung 0;
BA_ "GenSigSendType" SG_ 177 GE_KomFehler_ESP 0;
BA_ "GenSigSwitchedByIgnition" SG_ 177 GE_KomFehler_ESP 0;
BA_ "Fehlerwert" SG_ 177 GE_KomFehler_ESP 1;
BA_ "GenSigSendType" SG_ 177 GE_Rollrichtung_falsch 0;
BA_ "GenSigSwitchedByIgnition" SG_ 177 GE_Rollrichtung_falsch 0;
BA_ "GenSigSendType" SG_ 177 GE_Strombedarf_erh 0;
BA_ "GenSigSwitchedByIgnition" SG_ 177 GE_Strombedarf_erh 0;
BA_ "GenSigSendType" SG_ 177 GE_TippZustand 0;
BA_ "GenSigSwitchedByIgnition" SG_ 177 GE_TippZustand 0;
BA_ "GenSigSendType" SG_ 177 GE_Uefkt_Praed 0;
BA_ "GenSigSwitchedByIgnition" SG_ 177 GE_Uefkt_Praed 0;
BA_ "Fehlerwert" SG_ 177 GE_Uefkt_Praed 16383;
BA_ "GenSigSendType" SG_ 177 Getriebe_17_BZ 0;
BA_ "GenSigFuncType" SG_ 177 Getriebe_17_BZ 1;
BA_ "GenSigSwitchedByIgnition" SG_ 177 Getriebe_17_BZ 0;
BA_ "GenSigSendType" SG_ 177 Getriebe_17_CRC 0;
BA_ "GenSigFuncType" SG_ 177 Getriebe_17_CRC 2;
BA_ "GenSigSwitchedByIgnition" SG_ 177 Getriebe_17_CRC 0;
BA_ "GenSigSendType" SG_ 310 HAL_01_BZ 0;
BA_ "GenSigFuncType" SG_ 310 HAL_01_BZ 1;
BA_ "GenSigSwitchedByIgnition" SG_ 310 HAL_01_BZ 0;
BA_ "GenSigSendType" SG_ 310 HAL_01_CRC 0;
BA_ "GenSigFuncType" SG_ 310 HAL_01_CRC 2;
BA_ "GenSigSwitchedByIgnition" SG_ 310 HAL_01_CRC 0;
BA_ "GenSigSendType" SG_ 310 HAL_Charisma_FahrPr 0;
BA_ "GenSigSwitchedByIgnition" SG_ 310 HAL_Charisma_FahrPr 0;
BA_ "GenSigSendType" SG_ 310 HAL_Charisma_Status 0;
BA_ "GenSigSwitchedByIgnition" SG_ 310 HAL_Charisma_Status 0;
BA_ "GenSigSendType" SG_ 310 HAL_EFP_FahrPr 0;
BA_ "GenSigSwitchedByIgnition" SG_ 310 HAL_EFP_FahrPr 0;
BA_ "GenSigSendType" SG_ 310 HAL_Fahrerwunschwinkel_Soll 0;
BA_ "GenSigStartValue" SG_ 310 HAL_Fahrerwunschwinkel_Soll 1022;
BA_ "GenSigSwitchedByIgnition" SG_ 310 HAL_Fahrerwunschwinkel_Soll 0;
BA_ "Fehlerwert" SG_ 310 HAL_Fahrerwunschwinkel_Soll 1023;
BA_ "GenSigSendType" SG_ 310 HAL_max_Gradient 0;
BA_ "GenSigStartValue" SG_ 310 HAL_max_Gradient 126;
BA_ "GenSigSwitchedByIgnition" SG_ 310 HAL_max_Gradient 0;
BA_ "Fehlerwert" SG_ 310 HAL_max_Gradient 127;
BA_ "GenSigSendType" SG_ 310 HAL_QBit_Radwinkel 0;
BA_ "GenSigSwitchedByIgnition" SG_ 310 HAL_QBit_Radwinkel 0;
BA_ "GenSigSendType" SG_ 310 HAL_Radwinkel 0;
BA_ "GenSigStartValue" SG_ 310 HAL_Radwinkel 1022;
BA_ "GenSigSwitchedByIgnition" SG_ 310 HAL_Radwinkel 0;
BA_ "Fehlerwert" SG_ 310 HAL_Radwinkel 1023;
BA_ "GenSigSendType" SG_ 310 HAL_Status 0;
BA_ "GenSigSwitchedByIgnition" SG_ 310 HAL_Status 0;
BA_ "GenSigSendType" SG_ 310 HAL_VZ_Fahrerwunschwinkel_Soll 0;
BA_ "GenSigSwitchedByIgnition" SG_ 310 HAL_VZ_Fahrerwunschwinkel_Soll 0;
BA_ "GenSigSendType" SG_ 310 HAL_VZ_Radwinkel 0;
BA_ "GenSigSwitchedByIgnition" SG_ 310 HAL_VZ_Radwinkel 0;
BA_ "GenSigSendType" SG_ 310 HAL_Warnungen 0;
BA_ "GenSigSwitchedByIgnition" SG_ 310 HAL_Warnungen 0;
BA_ "GenSigSendType" SG_ 310 HAL_Winkelbegrenzung 0;
BA_ "GenSigSwitchedByIgnition" SG_ 310 HAL_Winkelbegrenzung 0;
BA_ "GenSigSendType" SG_ 676 HAL_02_BZ 0;
BA_ "GenSigFuncType" SG_ 676 HAL_02_BZ 1;
BA_ "GenSigSwitchedByIgnition" SG_ 676 HAL_02_BZ 0;
BA_ "GenSigSendType" SG_ 676 HAL_02_CRC 0;
BA_ "GenSigFuncType" SG_ 676 HAL_02_CRC 2;
BA_ "GenSigSwitchedByIgnition" SG_ 676 HAL_02_CRC 0;
BA_ "GenSigSendType" SG_ 676 HAL_ARA_Status 0;
BA_ "GenSigSwitchedByIgnition" SG_ 676 HAL_ARA_Status 0;
BA_ "GenSigSendType" SG_ 676 HAL_IL_Status 0;
BA_ "GenSigStartValue" SG_ 676 HAL_IL_Status 1;
BA_ "GenSigSwitchedByIgnition" SG_ 676 HAL_IL_Status 0;
BA_ "GenSigSendType" SG_ 676 HAL_PLA_Status 0;
BA_ "GenSigSwitchedByIgnition" SG_ 676 HAL_PLA_Status 0;
BA_ "GenSigSendType" SG_ 676 HAL_PWR_Abbruch 0;
BA_ "GenSigSwitchedByIgnition" SG_ 676 HAL_PWR_Abbruch 0;
BA_ "GenSigSendType" SG_ 676 HAL_PWR_Fehler 0;
BA_ "GenSigSwitchedByIgnition" SG_ 676 HAL_PWR_Fehler 0;
BA_ "GenSigSendType" SG_ 1410 HD_Bewegung_auf 0;
BA_ "GenSigSwitchedByIgnition" SG_ 1410 HD_Bewegung_auf 0;
BA_ "GenSigSendType" SG_ 1410 HD_Bewegung_zu 0;
BA_ "GenSigSwitchedByIgnition" SG_ 1410 HD_Bewegung_zu 0;
BA_ "GenSigSendType" SG_ 1410 HD_Endstellung_oben 0;
BA_ "GenSigSwitchedByIgnition" SG_ 1410 HD_Endstellung_oben 0;
BA_ "GenSigSendType" SG_ 1410 HD_Endstellung_unten 0;
BA_ "GenSigSwitchedByIgnition" SG_ 1410 HD_Endstellung_unten 0;
BA_ "GenSigSendType" SG_ 1410 HD_Innentaster_betaetigt 0;
BA_ "GenSigSwitchedByIgnition" SG_ 1410 HD_Innentaster_betaetigt 0;
BA_ "GenSigSendType" SG_ 1410 HD_Position 0;
BA_ "GenSigSwitchedByIgnition" SG_ 1410 HD_Position 0;
BA_ "GenSigSendType" SG_ 1410 HD_Rueckmeld_prog 0;
BA_ "GenSigSwitchedByIgnition" SG_ 1410 HD_Rueckmeld_prog 0;
BA_ "GenSigSendType" SG_ 1410 HD_Taster_defekt 0;
BA_ "GenSigSwitchedByIgnition" SG_ 1410 HD_Taster_defekt 0;
BA_ "GenSigSendType" SG_ 1410 HD_UeKB_erkannt 0;
BA_ "GenSigSwitchedByIgnition" SG_ 1410 HD_UeKB_erkannt 0;
BA_ "GenSigSendType" SG_ 1410 HD_Verr_Taster_betaetigt_inv 0;
BA_ "GenSigSwitchedByIgnition" SG_ 1410 HD_Verr_Taster_betaetigt_inv 0;
BA_ "GenSigSendType" SG_ 1410 HD_Verriegelungstaster_betaetigt 0;
BA_ "GenSigSwitchedByIgnition" SG_ 1410 HD_Verriegelungstaster_betaetigt 0;
BA_ "GenSigSendType" SG_ 1410 HD_ZZH_Schalter_S3 3;
BA_ "GenSigSwitchedByIgnition" SG_ 1410 HD_ZZH_Schalter_S3 0;
BA_ "GenSigSendType" SG_ 1416 BCM1_TCH_HLR_Anf 3;
BA_ "GenSigSwitchedByIgnition" SG_ 1416 BCM1_TCH_HLR_Anf 0;
BA_ "GenSigSendType" SG_ 1416 FSH_LED 3;
BA_ "GenSigSwitchedByIgnition" SG_ 1416 FSH_LED 0;
BA_ "GenSigSendType" SG_ 1416 HLR_SIH_Freigabe_Fond 3;
BA_ "GenSigSwitchedByIgnition" SG_ 1416 HLR_SIH_Freigabe_Fond 0;
BA_ "GenSigSendType" SG_ 1416 HSH_LED 3;
BA_ "GenSigSwitchedByIgnition" SG_ 1416 HSH_LED 0;
BA_ "GenSigSendType" SG_ 1416 KRH_Stufe_LED_li 3;
BA_ "GenSigSwitchedByIgnition" SG_ 1416 KRH_Stufe_LED_li 0;
BA_ "GenSigSendType" SG_ 1416 KRH_Stufe_LED_re 3;
BA_ "GenSigSwitchedByIgnition" SG_ 1416 KRH_Stufe_LED_re 0;
BA_ "GenSigSendType" SG_ 1416 SIH_Stufe_LED_HL 3;
BA_ "GenSigSwitchedByIgnition" SG_ 1416 SIH_Stufe_LED_HL 0;
BA_ "GenSigSendType" SG_ 1416 SIH_Stufe_LED_HR 3;
BA_ "GenSigSwitchedByIgnition" SG_ 1416 SIH_Stufe_LED_HR 0;
BA_ "GenSigSendType" SG_ 1416 SIH_Stufe_LED_li 3;
BA_ "GenSigSwitchedByIgnition" SG_ 1416 SIH_Stufe_LED_li 0;
BA_ "GenSigSendType" SG_ 1416 SIH_Stufe_LED_re 3;
BA_ "GenSigSwitchedByIgnition" SG_ 1416 SIH_Stufe_LED_re 0;
BA_ "GenSigSendType" SG_ 1416 SIL_Stufe_LED_HL 3;
BA_ "GenSigSwitchedByIgnition" SG_ 1416 SIL_Stufe_LED_HL 0;
BA_ "GenSigSendType" SG_ 1416 SIL_Stufe_LED_HR 3;
BA_ "GenSigSwitchedByIgnition" SG_ 1416 SIL_Stufe_LED_HR 0;
BA_ "GenSigSendType" SG_ 1416 SIL_Stufe_LED_li 3;
BA_ "GenSigSwitchedByIgnition" SG_ 1416 SIL_Stufe_LED_li 0;
BA_ "GenSigSendType" SG_ 1416 SIL_Stufe_LED_re 3;
BA_ "GenSigSwitchedByIgnition" SG_ 1416 SIL_Stufe_LED_re 0;
BA_ "GenSigSendType" SG_ 1016 HLR_FlHz_Freigabe_HL 3;
BA_ "GenSigSwitchedByIgnition" SG_ 1016 HLR_FlHz_Freigabe_HL 0;
BA_ "GenSigSendType" SG_ 1016 HLR_FlHz_Freigabe_HR 3;
BA_ "GenSigSwitchedByIgnition" SG_ 1016 HLR_FlHz_Freigabe_HR 0;
BA_ "GenSigSendType" SG_ 1016 HLR_FlHz_Freigabe_Ruhesitz 3;
BA_ "GenSigSwitchedByIgnition" SG_ 1016 HLR_FlHz_Freigabe_Ruhesitz 0;
BA_ "GenSigSendType" SG_ 1016 HLR_FlHz_Freigabe_VL 3;
BA_ "GenSigSwitchedByIgnition" SG_ 1016 HLR_FlHz_Freigabe_VL 0;
BA_ "GenSigSendType" SG_ 1016 HLR_FlHz_Freigabe_VR 3;
BA_ "GenSigSwitchedByIgnition" SG_ 1016 HLR_FlHz_Freigabe_VR 0;
BA_ "GenSigSendType" SG_ 1016 HLR_FSH_Freigabe 3;
BA_ "GenSigSwitchedByIgnition" SG_ 1016 HLR_FSH_Freigabe 0;
BA_ "Fehlerwert" SG_ 1016 HLR_FSH_Freigabe 63;
BA_ "GenSigSendType" SG_ 1016 HLR_HSH_Freigabe 3;
BA_ "GenSigSwitchedByIgnition" SG_ 1016 HLR_HSH_Freigabe 0;
BA_ "GenSigSendType" SG_ 1016 HLR_KRH_Freigabe_VL 3;
BA_ "GenSigSwitchedByIgnition" SG_ 1016 HLR_KRH_Freigabe_VL 0;
BA_ "GenSigSendType" SG_ 1016 HLR_KRH_Freigabe_VR 3;
BA_ "GenSigSwitchedByIgnition" SG_ 1016 HLR_KRH_Freigabe_VR 0;
BA_ "GenSigSendType" SG_ 1016 HLR_LRH_Freigabe 3;
BA_ "GenSigSwitchedByIgnition" SG_ 1016 HLR_LRH_Freigabe 0;
BA_ "GenSigSendType" SG_ 1016 HLR_PTC_Freigabe 3;
BA_ "GenSigStartValue" SG_ 1016 HLR_PTC_Freigabe 3;
BA_ "GenSigSwitchedByIgnition" SG_ 1016 HLR_PTC_Freigabe 0;
BA_ "GenSigSendType" SG_ 1016 HLR_PTC_linear_Freigabe 3;
BA_ "GenSigSwitchedByIgnition" SG_ 1016 HLR_PTC_linear_Freigabe 0;
BA_ "Fehlerwert" SG_ 1016 HLR_PTC_linear_Freigabe 63;
BA_ "GenSigSendType" SG_ 1016 HLR_SIH_Freigabe_Fond 3;
BA_ "GenSigSwitchedByIgnition" SG_ 1016 HLR_SIH_Freigabe_Fond 0;
BA_ "GenSigSendType" SG_ 1016 HLR_SIH_Freigabe_HL 3;
BA_ "GenSigSwitchedByIgnition" SG_ 1016 HLR_SIH_Freigabe_HL 0;
BA_ "GenSigSendType" SG_ 1016 HLR_SIH_Freigabe_HR 3;
BA_ "GenSigSwitchedByIgnition" SG_ 1016 HLR_SIH_Freigabe_HR 0;
BA_ "GenSigSendType" SG_ 1016 HLR_SIH_Freigabe_VL 3;
BA_ "GenSigSwitchedByIgnition" SG_ 1016 HLR_SIH_Freigabe_VL 0;
BA_ "GenSigSendType" SG_ 1016 HLR_SIH_Freigabe_VR 3;
BA_ "GenSigSwitchedByIgnition" SG_ 1016 HLR_SIH_Freigabe_VR 0;
BA_ "GenSigSendType" SG_ 1016 HLR_SIL_Freigabe_HL 3;
BA_ "GenSigSwitchedByIgnition" SG_ 1016 HLR_SIL_Freigabe_HL 0;
BA_ "GenSigSendType" SG_ 1016 HLR_SIL_Freigabe_HR 3;
BA_ "GenSigSwitchedByIgnition" SG_ 1016 HLR_SIL_Freigabe_HR 0;
BA_ "GenSigSendType" SG_ 1016 HLR_SIL_Freigabe_VL 3;
BA_ "GenSigSwitchedByIgnition" SG_ 1016 HLR_SIL_Freigabe_VL 0;
BA_ "GenSigSendType" SG_ 1016 HLR_SIL_Freigabe_VR 3;
BA_ "GenSigSwitchedByIgnition" SG_ 1016 HLR_SIL_Freigabe_VR 0;
BA_ "GenSigSendType" SG_ 1016 HLR_Sp_Heizung_Freigabe_BT 3;
BA_ "GenSigSwitchedByIgnition" SG_ 1016 HLR_Sp_Heizung_Freigabe_BT 0;
BA_ "GenSigSendType" SG_ 1016 HLR_Sp_Heizung_Freigabe_FT 3;
BA_ "GenSigSwitchedByIgnition" SG_ 1016 HLR_Sp_Heizung_Freigabe_FT 0;
BA_ "GenSigSendType" SG_ 1016 HLR_TCH_Freigabe 3;
BA_ "GenSigSwitchedByIgnition" SG_ 1016 HLR_TCH_Freigabe 0;
BA_ "GenSigSendType" SG_ 1283 HV_Bordnetz_aktiv 3;
BA_ "GenSigSwitchedByIgnition" SG_ 1283 HV_Bordnetz_aktiv 0;
BA_ "GenSigSendType" SG_ 1283 HV_Bordnetz_Fehler 3;
BA_ "GenSigSwitchedByIgnition" SG_ 1283 HV_Bordnetz_Fehler 0;
BA_ "Fehlerwert" SG_ 1283 HV_Bordnetz_Fehler 1;
BA_ "GenSigSendType" SG_ 1283 HVK_01_BZ 0;
BA_ "GenSigFuncType" SG_ 1283 HVK_01_BZ 1;
BA_ "GenSigSwitchedByIgnition" SG_ 1283 HVK_01_BZ 0;
BA_ "GenSigSendType" SG_ 1283 HVK_01_CRC 0;
BA_ "GenSigFuncType" SG_ 1283 HVK_01_CRC 2;
BA_ "GenSigSwitchedByIgnition" SG_ 1283 HVK_01_CRC 0;
BA_ "GenSigSendType" SG_ 1283 HVK_AktiveEntladung_Anf 3;
BA_ "GenSigSwitchedByIgnition" SG_ 1283 HVK_AktiveEntladung_Anf 0;
BA_ "GenSigSendType" SG_ 1283 HVK_BMS_Sollmodus 3;
BA_ "GenSigStartValue" SG_ 1283 HVK_BMS_Sollmodus 7;
BA_ "GenSigSwitchedByIgnition" SG_ 1283 HVK_BMS_Sollmodus 0;
BA_ "GenSigSendType" SG_ 1283 HVK_DCDC_Sollmodus 3;
BA_ "GenSigStartValue" SG_ 1283 HVK_DCDC_Sollmodus 7;
BA_ "GenSigSwitchedByIgnition" SG_ 1283 HVK_DCDC_Sollmodus 0;
BA_ "GenSigSendType" SG_ 1283 HVK_EKK_Sollmodus 3;
BA_ "GenSigStartValue" SG_ 1283 HVK_EKK_Sollmodus 7;
BA_ "GenSigSwitchedByIgnition" SG_ 1283 HVK_EKK_Sollmodus 0;
BA_ "GenSigSendType" SG_ 1283 HVK_Gesamtst_Spgfreiheit 0;
BA_ "GenSigSwitchedByIgnition" SG_ 1283 HVK_Gesamtst_Spgfreiheit 0;
BA_ "Fehlerwert" SG_ 1283 HVK_Gesamtst_Spgfreiheit 3;
BA_ "GenSigSendType" SG_ 1283 HVK_HV_Netz_Warnungen 3;
BA_ "GenSigSwitchedByIgnition" SG_ 1283 HVK_HV_Netz_Warnungen 0;
BA_ "GenSigSendType" SG_ 1283 HVK_HVLM_Sollmodus 3;
BA_ "GenSigStartValue" SG_ 1283 HVK_HVLM_Sollmodus 7;
BA_ "GenSigSwitchedByIgnition" SG_ 1283 HVK_HVLM_Sollmodus 0;
BA_ "GenSigSendType" SG_ 1283 HVK_HVPTC_Sollmodus 3;
BA_ "GenSigStartValue" SG_ 1283 HVK_HVPTC_Sollmodus 7;
BA_ "GenSigSwitchedByIgnition" SG_ 1283 HVK_HVPTC_Sollmodus 0;
BA_ "GenSigSendType" SG_ 1283 HVK_Istmodus_Anf 3;
BA_ "GenSigSwitchedByIgnition" SG_ 1283 HVK_Istmodus_Anf 0;
BA_ "GenSigSendType" SG_ 1283 HVK_MO_EmSollzustand 3;
BA_ "GenSigStartValue" SG_ 1283 HVK_MO_EmSollzustand 255;
BA_ "GenSigSwitchedByIgnition" SG_ 1283 HVK_MO_EmSollzustand 0;
BA_ "GenSigSendType" SG_ 1283 HVK_TN1_Sollmodus 3;
BA_ "GenSigStartValue" SG_ 1283 HVK_TN1_Sollmodus 3;
BA_ "GenSigSwitchedByIgnition" SG_ 1283 HVK_TN1_Sollmodus 0;
BA_ "GenSigSendType" SG_ 1381 HVLM_FreigabeKlimatisierung 0;
BA_ "GenSigStartValue" SG_ 1381 HVLM_FreigabeKlimatisierung 2;
BA_ "GenSigSwitchedByIgnition" SG_ 1381 HVLM_FreigabeKlimatisierung 0;
BA_ "Fehlerwert" SG_ 1381 HVLM_FreigabeKlimatisierung 3;
BA_ "GenSigSendType" SG_ 1381 HVLM_FreigabeTankdeckel 3;
BA_ "GenSigStartValue" SG_ 1381 HVLM_FreigabeTankdeckel 2;
BA_ "GenSigSwitchedByIgnition" SG_ 1381 HVLM_FreigabeTankdeckel 0;
BA_ "Fehlerwert" SG_ 1381 HVLM_FreigabeTankdeckel 3;
BA_ "GenSigSendType" SG_ 1381 HVLM_HV_Abstellzeit 0;
BA_ "GenSigStartValue" SG_ 1381 HVLM_HV_Abstellzeit 254;
BA_ "GenSigSwitchedByIgnition" SG_ 1381 HVLM_HV_Abstellzeit 0;
BA_ "Fehlerwert" SG_ 1381 HVLM_HV_Abstellzeit 255;
BA_ "GenSigSendType" SG_ 1381 HVLM_IsoMessung_Anf 3;
BA_ "GenSigSwitchedByIgnition" SG_ 1381 HVLM_IsoMessung_Anf 0;
BA_ "GenSigSendType" SG_ 1381 HVLM_IstSpannung_HV 0;
BA_ "GenSigStartValue" SG_ 1381 HVLM_IstSpannung_HV 1022;
BA_ "GenSigSwitchedByIgnition" SG_ 1381 HVLM_IstSpannung_HV 0;
BA_ "Fehlerwert" SG_ 1381 HVLM_IstSpannung_HV 1023;
BA_ "GenSigSendType" SG_ 1381 HVLM_Ladesystemhinweise 0;
BA_ "GenSigSwitchedByIgnition" SG_ 1381 HVLM_Ladesystemhinweise 0;
BA_ "GenSigSendType" SG_ 1381 HVLM_Ladetexte 3;
BA_ "GenSigSwitchedByIgnition" SG_ 1381 HVLM_Ladetexte 0;
BA_ "GenSigSendType" SG_ 1381 HVLM_LG_Sollmodus 3;
BA_ "GenSigSwitchedByIgnition" SG_ 1381 HVLM_LG_Sollmodus 0;
BA_ "GenSigSendType" SG_ 1381 HVLM_MaxStrom_Netz 3;
BA_ "GenSigStartValue" SG_ 1381 HVLM_MaxStrom_Netz 126;
BA_ "GenSigSwitchedByIgnition" SG_ 1381 HVLM_MaxStrom_Netz 0;
BA_ "Fehlerwert" SG_ 1381 HVLM_MaxStrom_Netz 127;
BA_ "GenSigSendType" SG_ 1381 HVLM_Schluessel_Anfrage 3;
BA_ "GenSigSwitchedByIgnition" SG_ 1381 HVLM_Schluessel_Anfrage 0;
BA_ "GenSigSendType" SG_ 1381 HVLM_Start_Spannungsmessung_DCLS 3;
BA_ "GenSigSwitchedByIgnition" SG_ 1381 HVLM_Start_Spannungsmessung_DCLS 0;
BA_ "GenSigSendType" SG_ 1381 HVLM_Stecker_Verriegeln 3;
BA_ "GenSigStartValue" SG_ 1381 HVLM_Stecker_Verriegeln 2;
BA_ "GenSigSwitchedByIgnition" SG_ 1381 HVLM_Stecker_Verriegeln 0;
BA_ "GenSigSendType" SG_ 1381 HVLM_Zustand_LED 3;
BA_ "GenSigStartValue" SG_ 1381 HVLM_Zustand_LED 14;
BA_ "GenSigSwitchedByIgnition" SG_ 1381 HVLM_Zustand_LED 0;
BA_ "Fehlerwert" SG_ 1381 HVLM_Zustand_LED 15;
BA_ "GenSigSendType" SG_ 1340 HVLM_04_BZ 0;
BA_ "GenSigFuncType" SG_ 1340 HVLM_04_BZ 1;
BA_ "GenSigSwitchedByIgnition" SG_ 1340 HVLM_04_BZ 0;
BA_ "GenSigSendType" SG_ 1340 HVLM_04_CRC 0;
BA_ "GenSigFuncType" SG_ 1340 HVLM_04_CRC 2;
BA_ "GenSigSwitchedByIgnition" SG_ 1340 HVLM_04_CRC 0;
BA_ "GenSigSendType" SG_ 1340 HVLM_Anforderung_HMS 0;
BA_ "GenSigSwitchedByIgnition" SG_ 1340 HVLM_Anforderung_HMS 0;
BA_ "GenSigSendType" SG_ 1340 HVLM_AWC_Sollmodus 0;
BA_ "GenSigSwitchedByIgnition" SG_ 1340 HVLM_AWC_Sollmodus 0;
BA_ "Fehlerwert" SG_ 1340 HVLM_AWC_Sollmodus 7;
BA_ "GenSigSendType" SG_ 1340 HVLM_Fehlerstatus 0;
BA_ "GenSigStartValue" SG_ 1340 HVLM_Fehlerstatus 7;
BA_ "GenSigSwitchedByIgnition" SG_ 1340 HVLM_Fehlerstatus 0;
BA_ "GenSigSendType" SG_ 1340 HVLM_HV_Anf 0;
BA_ "GenSigSwitchedByIgnition" SG_ 1340 HVLM_HV_Anf 0;
BA_ "GenSigSendType" SG_ 1340 HVLM_HVEM_MaxLeistung 0;
BA_ "GenSigStartValue" SG_ 1340 HVLM_HVEM_MaxLeistung 510;
BA_ "GenSigSwitchedByIgnition" SG_ 1340 HVLM_HVEM_MaxLeistung 0;
BA_ "Fehlerwert" SG_ 1340 HVLM_HVEM_MaxLeistung 511;
BA_ "GenSigSendType" SG_ 1340 HVLM_IstModus_02 0;
BA_ "GenSigStartValue" SG_ 1340 HVLM_IstModus_02 2;
BA_ "GenSigSwitchedByIgnition" SG_ 1340 HVLM_IstModus_02 0;
BA_ "Fehlerwert" SG_ 1340 HVLM_IstModus_02 3;
BA_ "GenSigSendType" SG_ 1340 HVLM_LadeAnforderung 0;
BA_ "GenSigStartValue" SG_ 1340 HVLM_LadeAnforderung 6;
BA_ "GenSigSwitchedByIgnition" SG_ 1340 HVLM_LadeAnforderung 0;
BA_ "Fehlerwert" SG_ 1340 HVLM_LadeAnforderung 7;
BA_ "GenSigSendType" SG_ 1340 HVLM_Ladeart 0;
BA_ "GenSigSwitchedByIgnition" SG_ 1340 HVLM_Ladeart 0;
BA_ "GenSigSendType" SG_ 1340 HVLM_MaxBatLadestromHV 0;
BA_ "GenSigStartValue" SG_ 1340 HVLM_MaxBatLadestromHV 254;
BA_ "GenSigSwitchedByIgnition" SG_ 1340 HVLM_MaxBatLadestromHV 0;
BA_ "Fehlerwert" SG_ 1340 HVLM_MaxBatLadestromHV 255;
BA_ "GenSigSendType" SG_ 1340 HVLM_Parken_beibehalten_HMS 0;
BA_ "GenSigStartValue" SG_ 1340 HVLM_Parken_beibehalten_HMS 2;
BA_ "GenSigSwitchedByIgnition" SG_ 1340 HVLM_Parken_beibehalten_HMS 0;
BA_ "Fehlerwert" SG_ 1340 HVLM_Parken_beibehalten_HMS 3;
BA_ "GenSigSendType" SG_ 1340 HVLM_Standklima_Timer_Status 0;
BA_ "GenSigSwitchedByIgnition" SG_ 1340 HVLM_Standklima_Timer_Status 0;
BA_ "GenSigSendType" SG_ 1340 HVLM_Status_Netz 0;
BA_ "GenSigSwitchedByIgnition" SG_ 1340 HVLM_Status_Netz 0;
BA_ "GenSigSendType" SG_ 1340 HVLM_Stecker_Status 0;
BA_ "GenSigSwitchedByIgnition" SG_ 1340 HVLM_Stecker_Status 0;
BA_ "GenSigSendType" SG_ 1340 HVLM_STH_Betriebsmodus 0;
BA_ "GenSigStartValue" SG_ 1340 HVLM_STH_Betriebsmodus 6;
BA_ "GenSigSwitchedByIgnition" SG_ 1340 HVLM_STH_Betriebsmodus 0;
BA_ "Fehlerwert" SG_ 1340 HVLM_STH_Betriebsmodus 7;
BA_ "GenSigSendType" SG_ 1340 HVLM_VK_Modus 0;
BA_ "GenSigSwitchedByIgnition" SG_ 1340 HVLM_VK_Modus 0;
BA_ "Fehlerwert" SG_ 1340 HVLM_VK_Modus 3;
BA_ "GenSigSendType" SG_ 1340 HVLM_VK_STH_Einsatz 0;
BA_ "GenSigStartValue" SG_ 1340 HVLM_VK_STH_Einsatz 6;
BA_ "GenSigSwitchedByIgnition" SG_ 1340 HVLM_VK_STH_Einsatz 0;
BA_ "Fehlerwert" SG_ 1340 HVLM_VK_STH_Einsatz 7;
BA_ "GenSigSendType" SG_ 2589283485 HVLM_BattKond_Anf 3;
BA_ "GenSigStartValue" SG_ 2589283485 HVLM_BattKond_Anf 6;
BA_ "GenSigSwitchedByIgnition" SG_ 2589283485 HVLM_BattKond_Anf 0;
BA_ "Fehlerwert" SG_ 2589283485 HVLM_BattKond_Anf 7;
BA_ "GenSigSendType" SG_ 2589283485 HVLM_Dauer_Klima_02 3;
BA_ "GenSigStartValue" SG_ 2589283485 HVLM_Dauer_Klima_02 62;
BA_ "GenSigSwitchedByIgnition" SG_ 2589283485 HVLM_Dauer_Klima_02 0;
BA_ "Fehlerwert" SG_ 2589283485 HVLM_Dauer_Klima_02 63;
BA_ "GenSigSendType" SG_ 2463978610 HVLM_Ladeanzeige_Anf 3;
BA_ "GenSigSwitchedByIgnition" SG_ 2463978610 HVLM_Ladeanzeige_Anf 0;
BA_ "GenSigSendType" SG_ 2463978610 HVLM_Ladeanzeige_Intens_Front 3;
BA_ "GenSigStartValue" SG_ 2463978610 HVLM_Ladeanzeige_Intens_Front 126;
BA_ "GenSigSwitchedByIgnition" SG_ 2463978610 HVLM_Ladeanzeige_Intens_Front 0;
BA_ "Fehlerwert" SG_ 2463978610 HVLM_Ladeanzeige_Intens_Front 127;
BA_ "GenSigSendType" SG_ 2463978610 HVLM_Ladeanzeige_Intens_Heck 3;
BA_ "GenSigStartValue" SG_ 2463978610 HVLM_Ladeanzeige_Intens_Heck 126;
BA_ "GenSigSwitchedByIgnition" SG_ 2463978610 HVLM_Ladeanzeige_Intens_Heck 0;
BA_ "Fehlerwert" SG_ 2463978610 HVLM_Ladeanzeige_Intens_Heck 127;
BA_ "GenSigSendType" SG_ 2463978610 HVLM_Ladeanzeige_Rampzeit 3;
BA_ "GenSigSwitchedByIgnition" SG_ 2463978610 HVLM_Ladeanzeige_Rampzeit 0;
BA_ "GenSigSendType" SG_ 2463978610 HVLM_Ladeanzeige_Status 3;
BA_ "GenSigSwitchedByIgnition" SG_ 2463978610 HVLM_Ladeanzeige_Status 0;
BA_ "GenSigSendType" SG_ 2463978610 HVLM_RtmWarnLadeKommunikation 3;
BA_ "GenSigSwitchedByIgnition" SG_ 2463978610 HVLM_RtmWarnLadeKommunikation 0;
BA_ "GenSigSendType" SG_ 2463978610 HVLM_RtmWarnLadestatus 3;
BA_ "GenSigSwitchedByIgnition" SG_ 2463978610 HVLM_RtmWarnLadestatus 0;
BA_ "GenSigSendType" SG_ 2463978610 HVLM_RtmWarnLadesystem 3;
BA_ "GenSigSwitchedByIgnition" SG_ 2463978610 HVLM_RtmWarnLadesystem 0;
BA_ "GenSigSendType" SG_ 2463978610 HVLM_RtmWarnLadeverbindung 3;
BA_ "GenSigSwitchedByIgnition" SG_ 2463978610 HVLM_RtmWarnLadeverbindung 0;
BA_ "GenSigSendType" SG_ 1524 AMB_Charisma_FahrPr 3;
BA_ "GenSigSwitchedByIgnition" SG_ 1524 AMB_Charisma_FahrPr 0;
BA_ "GenSigSendType" SG_ 1524 AMB_Charisma_Status 3;
BA_ "GenSigSwitchedByIgnition" SG_ 1524 AMB_Charisma_Status 0;
BA_ "GenSigSendType" SG_ 1524 BCM1_DI_Rampe_Innenlicht 3;
BA_ "GenSigSwitchedByIgnition" SG_ 1524 BCM1_DI_Rampe_Innenlicht 0;
BA_ "GenSigSendType" SG_ 1524 BCM1_DI_Rampe_Leselicht 3;
BA_ "GenSigSwitchedByIgnition" SG_ 1524 BCM1_DI_Rampe_Leselicht 0;
BA_ "GenSigSendType" SG_ 1524 BCM1_Innenlicht_gedimmt_H 3;
BA_ "GenSigSwitchedByIgnition" SG_ 1524 BCM1_Innenlicht_gedimmt_H 0;
BA_ "GenSigSendType" SG_ 1524 BCM1_Innenlicht_gedimmt_V 3;
BA_ "GenSigSwitchedByIgnition" SG_ 1524 BCM1_Innenlicht_gedimmt_V 0;
BA_ "GenSigSendType" SG_ 1524 BCM1_Innenlicht_H 3;
BA_ "GenSigSwitchedByIgnition" SG_ 1524 BCM1_Innenlicht_H 0;
BA_ "GenSigSendType" SG_ 1524 BCM1_Innenlicht_V 3;
BA_ "GenSigSwitchedByIgnition" SG_ 1524 BCM1_Innenlicht_V 0;
BA_ "GenSigSendType" SG_ 1524 BCM1_Leselicht_Anf_hl 3;
BA_ "GenSigSwitchedByIgnition" SG_ 1524 BCM1_Leselicht_Anf_hl 0;
BA_ "GenSigSendType" SG_ 1524 BCM1_Leselicht_Anf_hr 3;
BA_ "GenSigSwitchedByIgnition" SG_ 1524 BCM1_Leselicht_Anf_hr 0;
BA_ "GenSigSendType" SG_ 1524 BCM1_Leselicht_Anf_vl 3;
BA_ "GenSigSwitchedByIgnition" SG_ 1524 BCM1_Leselicht_Anf_vl 0;
BA_ "GenSigSendType" SG_ 1524 BCM1_Leselicht_Anf_vr 3;
BA_ "GenSigSwitchedByIgnition" SG_ 1524 BCM1_Leselicht_Anf_vr 0;
BA_ "GenSigSendType" SG_ 1524 BCM1_Leuchten_Aus 3;
BA_ "GenSigSwitchedByIgnition" SG_ 1524 BCM1_Leuchten_Aus 0;
BA_ "GenSigSendType" SG_ 1524 IL_Bel_BFS_Ausstieg 3;
BA_ "GenSigSwitchedByIgnition" SG_ 1524 IL_Bel_BFS_Ausstieg 0;
BA_ "GenSigSendType" SG_ 1524 IL_Bel_FS_Ausstieg 3;
BA_ "GenSigSwitchedByIgnition" SG_ 1524 IL_Bel_FS_Ausstieg 0;
BA_ "GenSigSendType" SG_ 1524 IL_Bel_HBFS_Ausstieg 3;
BA_ "GenSigSwitchedByIgnition" SG_ 1524 IL_Bel_HBFS_Ausstieg 0;
BA_ "GenSigSendType" SG_ 1524 IL_Bel_HFS_Ausstieg 3;
BA_ "GenSigSwitchedByIgnition" SG_ 1524 IL_Bel_HFS_Ausstieg 0;
BA_ "GenSigSendType" SG_ 1524 IL_Dimmung_H_Tuerkontur 3;
BA_ "GenSigSwitchedByIgnition" SG_ 1524 IL_Dimmung_H_Tuerkontur 0;
BA_ "GenSigSendType" SG_ 1524 IL_Dimmung_Lautspr 3;
BA_ "GenSigSwitchedByIgnition" SG_ 1524 IL_Dimmung_Lautspr 0;
BA_ "GenSigSendType" SG_ 1524 IL_Dimmung_Tuerinnengriff 3;
BA_ "GenSigSwitchedByIgnition" SG_ 1524 IL_Dimmung_Tuerinnengriff 0;
BA_ "GenSigSendType" SG_ 1524 IL_Dimmung_Umfeldbel 3;
BA_ "GenSigSwitchedByIgnition" SG_ 1524 IL_Dimmung_Umfeldbel 0;
BA_ "GenSigSendType" SG_ 1524 IL_Dimmung_V_Tuerkontur 3;
BA_ "GenSigSwitchedByIgnition" SG_ 1524 IL_Dimmung_V_Tuerkontur 0;
BA_ "GenSigSendType" SG_ 1524 IL_Innenlicht_aktiv 3;
BA_ "GenSigStartValue" SG_ 1524 IL_Innenlicht_aktiv 1;
BA_ "GenSigSwitchedByIgnition" SG_ 1524 IL_Innenlicht_aktiv 0;
BA_ "GenSigSendType" SG_ 1524 IL_Klemme_30G_aktiv 3;
BA_ "GenSigSwitchedByIgnition" SG_ 1524 IL_Klemme_30G_aktiv 0;
BA_ "GenSigSendType" SG_ 312 IPA_01_BZ 0;
BA_ "GenSigFuncType" SG_ 312 IPA_01_BZ 1;
BA_ "GenSigSwitchedByIgnition" SG_ 312 IPA_01_BZ 0;
BA_ "GenSigSendType" SG_ 312 IPA_01_CRC 0;
BA_ "GenSigFuncType" SG_ 312 IPA_01_CRC 2;
BA_ "GenSigSwitchedByIgnition" SG_ 312 IPA_01_CRC 0;
BA_ "GenSigSendType" SG_ 312 IPA_Anforderung_HMS 0;
BA_ "GenSigSwitchedByIgnition" SG_ 312 IPA_Anforderung_HMS 0;
BA_ "GenSigSendType" SG_ 312 IPA_APS_LED 3;
BA_ "GenSigStartValue" SG_ 312 IPA_APS_LED 6;
BA_ "GenSigSendType" SG_ 312 IPA_Fahrstufenwunsch 0;
BA_ "GenSigSendType" SG_ 312 IPA_Parken_beibehalten_HMS 0;
BA_ "GenSigStartValue" SG_ 312 IPA_Parken_beibehalten_HMS 2;
BA_ "Fehlerwert" SG_ 312 IPA_Parken_beibehalten_HMS 3;
BA_ "GenSigSendType" SG_ 312 IPA_PLA_LED 3;
BA_ "GenSigStartValue" SG_ 312 IPA_PLA_LED 6;
BA_ "GenSigSendType" SG_ 312 IPA_Sollbeschleunigung 0;
BA_ "GenSigSendType" SG_ 312 IPA_Status 3;
BA_ "GenSigSwitchedByIgnition" SG_ 312 IPA_Status 0;
BA_ "GenSigSendType" SG_ 312 IPA_Status_IPA_GE 0;
BA_ "Fehlerwert" SG_ 312 IPA_Status_IPA_GE 7;
BA_ "GenSigSendType" SG_ 312 IPA_Status_IPA_TSK 3;
BA_ "GenSigStartValue" SG_ 312 IPA_Status_IPA_TSK 1;
BA_ "GenSigSendType" SG_ 312 Parken_aktives_System 3;
BA_ "GenSigSendType" SG_ 312 Parken_erhoehtes_Moment 0;
BA_ "GenSigSwitchedByIgnition" SG_ 312 Parken_erhoehtes_Moment 0;
BA_ "GenSigSendType" SG_ 312 Parken_Fahrbereitschaft_Anf 3;
BA_ "GenSigSendType" SG_ 312 Parken_Motorlauf_Anf 3;
BA_ "GenSigActiveRepetitions" SG_ 2527679583 Parken_Aktivierungslicht_Anf 5;
BA_ "GenSigSendType" SG_ 2527679583 Parken_Aktivierungslicht_Anf 4;
BA_ "GenSigSwitchedByIgnition" SG_ 2527679583 Parken_Aktivierungslicht_Anf 0;
BA_ "GenSigActiveRepetitions" SG_ 2527679583 Parken_Bestaetigungsblinken_Anf 5;
BA_ "GenSigSendType" SG_ 2527679583 Parken_Bestaetigungsblinken_Anf 4;
BA_ "GenSigSwitchedByIgnition" SG_ 2527679583 Parken_Bestaetigungsblinken_Anf 0;
BA_ "GenSigActiveRepetitions" SG_ 2527679583 Parken_Fahrbereitschaftlicht_Anf 5;
BA_ "GenSigSendType" SG_ 2527679583 Parken_Fahrbereitschaftlicht_Anf 4;
BA_ "GenSigActiveRepetitions" SG_ 2527679583 Parken_Fahrerhinweise_Anf 5;
BA_ "GenSigSendType" SG_ 2527679583 Parken_Fahrerhinweise_Anf 4;
BA_ "GenSigSwitchedByIgnition" SG_ 2527679583 Parken_Fahrerhinweise_Anf 0;
BA_ "GenSigActiveRepetitions" SG_ 2527679583 Parken_Fahrtrichtungslicht_Anf 5;
BA_ "GenSigSendType" SG_ 2527679583 Parken_Fahrtrichtungslicht_Anf 4;
BA_ "GenSigActiveRepetitions" SG_ 2527679583 Parken_FFB_LED_Anf 5;
BA_ "GenSigSendType" SG_ 2527679583 Parken_FFB_LED_Anf 4;
BA_ "GenSigActiveRepetitions" SG_ 2527679583 Parken_Lichtnachlauf_Anf 5;
BA_ "GenSigSendType" SG_ 2527679583 Parken_Lichtnachlauf_Anf 4;
BA_ "GenSigActiveRepetitions" SG_ 2527679583 Parken_Schluesselsuche_Anf 5;
BA_ "GenSigSendType" SG_ 2527679583 Parken_Schluesselsuche_Anf 4;
BA_ "GenSigActiveRepetitions" SG_ 2527679583 Parken_Seitenspiegel_Anf 5;
BA_ "GenSigSendType" SG_ 2527679583 Parken_Seitenspiegel_Anf 4;
BA_ "GenSigActiveRepetitions" SG_ 2527679583 Parken_Wegfahrsperren_Anf 5;
BA_ "GenSigSendType" SG_ 2527679583 Parken_Wegfahrsperren_Anf 4;
BA_ "GenSigActiveRepetitions" SG_ 2527679583 Parken_ZR_Sondermodus_Anf 5;
BA_ "GenSigSendType" SG_ 2527679583 Parken_ZR_Sondermodus_Anf 4;
BA_ "GenSigSwitchedByIgnition" SG_ 2527679583 Parken_ZR_Sondermodus_Anf 0;
BA_ "GenSigActiveRepetitions" SG_ 2527679583 Parken_ZV_Schliessen 5;
BA_ "GenSigSendType" SG_ 2527679583 Parken_ZV_Schliessen 4;
BA_ "GenSigSendType" SG_ 1806 ISO_BCM1_Req_Data 3;
BA_ "GenSigFuncType" SG_ 1806 ISO_BCM1_Req_Data 9;
BA_ "GenSigSwitchedByIgnition" SG_ 1806 ISO_BCM1_Req_Data 0;
BA_ "GenSigSendType" SG_ 1912 ISO_BCM1_Resp_Data 3;
BA_ "GenSigFuncType" SG_ 1912 ISO_BCM1_Resp_Data 9;
BA_ "GenSigSwitchedByIgnition" SG_ 1912 ISO_BCM1_Resp_Data 0;
BA_ "GenSigSendType" SG_ 1792 ISO_ALL_01_Req_Data 3;
BA_ "GenSigFuncType" SG_ 1792 ISO_ALL_01_Req_Data 9;
BA_ "GenSigSwitchedByIgnition" SG_ 1792 ISO_ALL_01_Req_Data 0;
BA_ "GenSigSendType" SG_ 1862 ISO_Klima_Req_Data 3;
BA_ "GenSigFuncType" SG_ 1862 ISO_Klima_Req_Data 9;
BA_ "GenSigSwitchedByIgnition" SG_ 1862 ISO_Klima_Req_Data 0;
BA_ "GenSigSendType" SG_ 1968 ISO_Klima_Resp_Data 3;
BA_ "GenSigFuncType" SG_ 1968 ISO_Klima_Resp_Data 9;
BA_ "GenSigSwitchedByIgnition" SG_ 1968 ISO_Klima_Resp_Data 0;
BA_ "GenSigSendType" SG_ 1881 ISO_Lift_Req_Data 3;
BA_ "GenSigFuncType" SG_ 1881 ISO_Lift_Req_Data 9;
BA_ "GenSigSwitchedByIgnition" SG_ 1881 ISO_Lift_Req_Data 0;
BA_ "GenSigSendType" SG_ 1987 ISO_Lift_Resp_Data 3;
BA_ "GenSigFuncType" SG_ 1987 ISO_Lift_Resp_Data 9;
BA_ "GenSigSwitchedByIgnition" SG_ 1987 ISO_Lift_Resp_Data 0;
BA_ "GenSigSendType" SG_ 2549874818 ISO_LCM_L_Req_Data 3;
BA_ "GenSigFuncType" SG_ 2549874818 ISO_LCM_L_Req_Data 9;
BA_ "GenSigSwitchedByIgnition" SG_ 2549874818 ISO_LCM_L_Req_Data 0;
BA_ "GenSigSendType" SG_ 2550005890 ISO_LCM_L_Resp_Data 3;
BA_ "GenSigFuncType" SG_ 2550005890 ISO_LCM_L_Resp_Data 9;
BA_ "GenSigSwitchedByIgnition" SG_ 2550005890 ISO_LCM_L_Resp_Data 0;
BA_ "GenSigSendType" SG_ 2549874819 ISO_LCM_R_Req_Data 3;
BA_ "GenSigFuncType" SG_ 2549874819 ISO_LCM_R_Req_Data 9;
BA_ "GenSigSwitchedByIgnition" SG_ 2549874819 ISO_LCM_R_Req_Data 0;
BA_ "GenSigSendType" SG_ 2550005891 ISO_LCM_R_Resp_Data 3;
BA_ "GenSigFuncType" SG_ 2550005891 ISO_LCM_R_Resp_Data 9;
BA_ "GenSigSwitchedByIgnition" SG_ 2550005891 ISO_LCM_R_Resp_Data 0;
BA_ "GenSigSendType" SG_ 2549874838 ISO_LED_LM_L_Req_Data 3;
BA_ "GenSigFuncType" SG_ 2549874838 ISO_LED_LM_L_Req_Data 9;
BA_ "GenSigSwitchedByIgnition" SG_ 2549874838 ISO_LED_LM_L_Req_Data 0;
BA_ "GenSigSendType" SG_ 2550005910 ISO_LED_LM_L_Resp_Data 3;
BA_ "GenSigFuncType" SG_ 2550005910 ISO_LED_LM_L_Resp_Data 9;
BA_ "GenSigSwitchedByIgnition" SG_ 2550005910 ISO_LED_LM_L_Resp_Data 0;
BA_ "GenSigSendType" SG_ 2549874839 ISO_LED_LM_R_Req_Data 3;
BA_ "GenSigFuncType" SG_ 2549874839 ISO_LED_LM_R_Req_Data 9;
BA_ "GenSigSwitchedByIgnition" SG_ 2549874839 ISO_LED_LM_R_Req_Data 0;
BA_ "GenSigSendType" SG_ 2550005911 ISO_LED_LM_R_Resp_Data 3;
BA_ "GenSigFuncType" SG_ 2550005911 ISO_LED_LM_R_Resp_Data 9;
BA_ "GenSigSwitchedByIgnition" SG_ 2550005911 ISO_LED_LM_R_Resp_Data 0;
BA_ "GenSigSendType" SG_ 2549874884 ISO_VAS_L_Req_Data 3;
BA_ "GenSigSwitchedByIgnition" SG_ 2549874884 ISO_VAS_L_Req_Data 0;
BA_ "GenSigSendType" SG_ 2550005956 ISO_VAS_L_Resp_Data 3;
BA_ "GenSigSwitchedByIgnition" SG_ 2550005956 ISO_VAS_L_Resp_Data 0;
BA_ "GenSigSendType" SG_ 2549874885 ISO_VAS_R_Req_Data 3;
BA_ "GenSigSwitchedByIgnition" SG_ 2549874885 ISO_VAS_R_Req_Data 0;
BA_ "GenSigSendType" SG_ 2550005957 ISO_VAS_R_Resp_Data 3;
BA_ "GenSigSwitchedByIgnition" SG_ 2550005957 ISO_VAS_R_Resp_Data 0;
BA_ "GenSigSendType" SG_ 2463978614 KAS_Anf_Bremsruck 0;
BA_ "GenSigSendType" SG_ 2463978614 KAS_Anf_OPS 0;
BA_ "GenSigSendType" SG_ 2463978614 KAS_Anf_Prefill 0;
BA_ "GenSigSendType" SG_ 2463978614 KAS_Anzeige_Info_links 3;
BA_ "GenSigSendType" SG_ 2463978614 KAS_Anzeige_Info_rechts 3;
BA_ "GenSigSendType" SG_ 2463978614 KAS_Anzeige_Warnung 3;
BA_ "GenSigSendType" SG_ 2463978614 KAS_Kritikalitaetslevel 0;
BA_ "GenSigStartValue" SG_ 2463978614 KAS_Kritikalitaetslevel 7;
BA_ "GenSigSendType" SG_ 2463978614 KAS_PreSense_Modus_System 0;
BA_ "GenSigSendType" SG_ 2463978614 KAS_Status 3;
BA_ "Fehlerwert" SG_ 2463978614 KAS_Status 6;
BA_ "GenSigSendType" SG_ 2463978614 KAS_Texte 3;
BA_ "GenSigSendType" SG_ 2463978614 KAS_Verfuegbarkeit 3;
BA_ "GenSigSendType" SG_ 2463978614 KAS_Verz_Anf 0;
BA_ "GenSigStartValue" SG_ 2463978614 KAS_Verz_Anf 254;
BA_ "Fehlerwert" SG_ 2463978614 KAS_Verz_Anf 255;
BA_ "GenSigActiveRepetitions" SG_ 497 FBS_Aktivierung_Pilot_Parken 7;
BA_ "GenSigSendType" SG_ 497 FBS_Aktivierung_Pilot_Parken 2;
BA_ "GenSigSwitchedByIgnition" SG_ 497 FBS_Aktivierung_Pilot_Parken 0;
BA_ "GenSigActiveRepetitions" SG_ 497 FFB_FDF_Taste 7;
BA_ "GenSigSendType" SG_ 497 FFB_FDF_Taste 2;
BA_ "GenSigSwitchedByIgnition" SG_ 497 FFB_FDF_Taste 0;
BA_ "GenSigActiveRepetitions" SG_ 497 FFB_Joker_Taste 7;
BA_ "GenSigSendType" SG_ 497 FFB_Joker_Taste 2;
BA_ "GenSigSwitchedByIgnition" SG_ 497 FFB_Joker_Taste 0;
BA_ "GenSigActiveRepetitions" SG_ 497 FFB_Park_Taste 7;
BA_ "GenSigSendType" SG_ 497 FFB_Park_Taste 2;
BA_ "GenSigSwitchedByIgnition" SG_ 497 FFB_Park_Taste 0;
BA_ "GenSigActiveRepetitions" SG_ 497 FFB_Remotestart_Taste 7;
BA_ "GenSigSendType" SG_ 497 FFB_Remotestart_Taste 2;
BA_ "GenSigSwitchedByIgnition" SG_ 497 FFB_Remotestart_Taste 0;
BA_ "GenSigActiveRepetitions" SG_ 497 KY_Auf_Taste 7;
BA_ "GenSigSendType" SG_ 497 KY_Auf_Taste 2;
BA_ "GenSigSwitchedByIgnition" SG_ 497 KY_Auf_Taste 0;
BA_ "GenSigActiveRepetitions" SG_ 497 KY_Bereich 7;
BA_ "GenSigSendType" SG_ 497 KY_Bereich 2;
BA_ "GenSigStartValue" SG_ 497 KY_Bereich 7;
BA_ "GenSigSwitchedByIgnition" SG_ 497 KY_Bereich 0;
BA_ "GenSigActiveRepetitions" SG_ 497 KY_BT_Entriegelung_Autorisiert 7;
BA_ "GenSigSendType" SG_ 497 KY_BT_Entriegelung_Autorisiert 2;
BA_ "GenSigSwitchedByIgnition" SG_ 497 KY_BT_Entriegelung_Autorisiert 0;
BA_ "GenSigActiveRepetitions" SG_ 497 KY_BT_Verriegelung_Autorisiert 7;
BA_ "GenSigSendType" SG_ 497 KY_BT_Verriegelung_Autorisiert 2;
BA_ "GenSigSwitchedByIgnition" SG_ 497 KY_BT_Verriegelung_Autorisiert 0;
BA_ "GenSigSendType" SG_ 497 KY_EasyClose_Abbruch 3;
BA_ "GenSigSwitchedByIgnition" SG_ 497 KY_EasyClose_Abbruch 0;
BA_ "GenSigSendType" SG_ 497 KY_EasyClose_Status 3;
BA_ "GenSigSwitchedByIgnition" SG_ 497 KY_EasyClose_Status 0;
BA_ "GenSigActiveRepetitions" SG_ 497 KY_Front_Entr_Autorisiert 7;
BA_ "GenSigSendType" SG_ 497 KY_Front_Entr_Autorisiert 2;
BA_ "GenSigSwitchedByIgnition" SG_ 497 KY_Front_Entr_Autorisiert 0;
BA_ "GenSigActiveRepetitions" SG_ 497 KY_Front_Verr_Autorisiert 7;
BA_ "GenSigSendType" SG_ 497 KY_Front_Verr_Autorisiert 2;
BA_ "GenSigSwitchedByIgnition" SG_ 497 KY_Front_Verr_Autorisiert 0;
BA_ "GenSigActiveRepetitions" SG_ 497 KY_FT_Entriegelung_Autorisiert 7;
BA_ "GenSigSendType" SG_ 497 KY_FT_Entriegelung_Autorisiert 2;
BA_ "GenSigSwitchedByIgnition" SG_ 497 KY_FT_Entriegelung_Autorisiert 0;
BA_ "GenSigActiveRepetitions" SG_ 497 KY_FT_Verriegelung_Autorisiert 7;
BA_ "GenSigSendType" SG_ 497 KY_FT_Verriegelung_Autorisiert 2;
BA_ "GenSigSwitchedByIgnition" SG_ 497 KY_FT_Verriegelung_Autorisiert 0;
BA_ "GenSigActiveRepetitions" SG_ 497 KY_HBFS_Entriegelung_Autorisiert 7;
BA_ "GenSigSendType" SG_ 497 KY_HBFS_Entriegelung_Autorisiert 2;
BA_ "GenSigSwitchedByIgnition" SG_ 497 KY_HBFS_Entriegelung_Autorisiert 0;
BA_ "GenSigActiveRepetitions" SG_ 497 KY_HBFS_Verriegelung_Autorisiert 7;
BA_ "GenSigSendType" SG_ 497 KY_HBFS_Verriegelung_Autorisiert 2;
BA_ "GenSigSwitchedByIgnition" SG_ 497 KY_HBFS_Verriegelung_Autorisiert 0;
BA_ "GenSigActiveRepetitions" SG_ 497 KY_HD_Auffahrt 7;
BA_ "GenSigSendType" SG_ 497 KY_HD_Auffahrt 2;
BA_ "GenSigSwitchedByIgnition" SG_ 497 KY_HD_Auffahrt 0;
BA_ "GenSigActiveRepetitions" SG_ 497 KY_HD_Entriegelung_Autorisiert 7;
BA_ "GenSigSendType" SG_ 497 KY_HD_Entriegelung_Autorisiert 2;
BA_ "GenSigSwitchedByIgnition" SG_ 497 KY_HD_Entriegelung_Autorisiert 0;
BA_ "GenSigActiveRepetitions" SG_ 497 KY_HD_Verriegelung_Autorisiert 7;
BA_ "GenSigSendType" SG_ 497 KY_HD_Verriegelung_Autorisiert 2;
BA_ "GenSigSwitchedByIgnition" SG_ 497 KY_HD_Verriegelung_Autorisiert 0;
BA_ "GenSigActiveRepetitions" SG_ 497 KY_HD_Zufahrt 7;
BA_ "GenSigSendType" SG_ 497 KY_HD_Zufahrt 2;
BA_ "GenSigSwitchedByIgnition" SG_ 497 KY_HD_Zufahrt 0;
BA_ "GenSigActiveRepetitions" SG_ 497 KY_HDF_Taste 7;
BA_ "GenSigSendType" SG_ 497 KY_HDF_Taste 2;
BA_ "GenSigSwitchedByIgnition" SG_ 497 KY_HDF_Taste 0;
BA_ "GenSigActiveRepetitions" SG_ 497 KY_HFS_Entriegelung_Autorisiert 7;
BA_ "GenSigSendType" SG_ 497 KY_HFS_Entriegelung_Autorisiert 2;
BA_ "GenSigSwitchedByIgnition" SG_ 497 KY_HFS_Entriegelung_Autorisiert 0;
BA_ "GenSigActiveRepetitions" SG_ 497 KY_HFS_Verriegelung_Autorisiert 7;
BA_ "GenSigSendType" SG_ 497 KY_HFS_Verriegelung_Autorisiert 2;
BA_ "GenSigSwitchedByIgnition" SG_ 497 KY_HFS_Verriegelung_Autorisiert 0;
BA_ "GenSigActiveRepetitions" SG_ 497 KY_IDG_in_Reichweite 7;
BA_ "GenSigSendType" SG_ 497 KY_IDG_in_Reichweite 2;
BA_ "GenSigSwitchedByIgnition" SG_ 497 KY_IDG_in_Reichweite 0;
BA_ "GenSigActiveRepetitions" SG_ 497 KY_LKL_1_Autorisierung 7;
BA_ "GenSigSendType" SG_ 497 KY_LKL_1_Autorisierung 2;
BA_ "GenSigSwitchedByIgnition" SG_ 497 KY_LKL_1_Autorisierung 0;
BA_ "GenSigActiveRepetitions" SG_ 497 KY_LKL_2_Autorisierung 7;
BA_ "GenSigSendType" SG_ 497 KY_LKL_2_Autorisierung 2;
BA_ "GenSigSwitchedByIgnition" SG_ 497 KY_LKL_2_Autorisierung 0;
BA_ "GenSigActiveRepetitions" SG_ 497 KY_Panik_Taste 7;
BA_ "GenSigSendType" SG_ 497 KY_Panik_Taste 2;
BA_ "GenSigSwitchedByIgnition" SG_ 497 KY_Panik_Taste 0;
BA_ "GenSigActiveRepetitions" SG_ 497 KY_Position 7;
BA_ "GenSigSendType" SG_ 497 KY_Position 2;
BA_ "GenSigStartValue" SG_ 497 KY_Position 7;
BA_ "GenSigSwitchedByIgnition" SG_ 497 KY_Position 0;
BA_ "GenSigActiveRepetitions" SG_ 497 KY_Schluessel_im_Fzg 7;
BA_ "GenSigSendType" SG_ 497 KY_Schluessel_im_Fzg 2;
BA_ "GenSigSwitchedByIgnition" SG_ 497 KY_Schluessel_im_Fzg 0;
BA_ "GenSigActiveRepetitions" SG_ 497 KY_Zu_Taste 7;
BA_ "GenSigSendType" SG_ 497 KY_Zu_Taste 2;
BA_ "GenSigSwitchedByIgnition" SG_ 497 KY_Zu_Taste 0;
BA_ "GenSigActiveRepetitions" SG_ 497 KY_ZV_Signatur 7;
BA_ "GenSigSendType" SG_ 497 KY_ZV_Signatur 2;
BA_ "GenSigSwitchedByIgnition" SG_ 497 KY_ZV_Signatur 0;
BA_ "GenSigActiveRepetitions" SG_ 497 Schluesselnr_Personalisierung 7;
BA_ "GenSigSendType" SG_ 497 Schluesselnr_Personalisierung 2;
BA_ "GenSigStartValue" SG_ 497 Schluesselnr_Personalisierung 14;
BA_ "GenSigSwitchedByIgnition" SG_ 497 Schluesselnr_Personalisierung 0;
BA_ "Fehlerwert" SG_ 497 Schluesselnr_Personalisierung 15;
BA_REL_ "GenSigTimeoutTime" BU_SG_REL_ BCM1 SG_ 427 ESC_AHW_aktiv 2000;
BA_REL_ "GenSigTimeoutTime" BU_SG_REL_ BCM1 SG_ 427 ESC_AHW_nicht_verfuegbar 2000;
BA_REL_ "GenSigTimeoutTime" BU_SG_REL_ BCM1 SG_ 427 ESC_Verz_Reg_aktiv 2000;
BA_REL_ "GenSigTimeoutTime" BU_SG_REL_ BCM1 SG_ 427 ESC_Verz_Reg_nicht_verfuegbar 2000;
BA_REL_ "GenSigTimeoutTime" BU_SG_REL_ BCM1 SG_ 427 ESC_Verz_Reg_TB_nicht_verfuegbar 2000;
BA_REL_ "GenSigTimeoutTime" BU_SG_REL_ BCM1 SG_ 427 ESC_Verz_Reg_ZB_nicht_verfuegbar 2000;
BA_REL_ "GenSigTimeoutTime" BU_SG_REL_ BCM1 SG_ 427 ESC_Konsistenz_ARA 2000;
BA_REL_ "GenSigTimeoutTime" BU_SG_REL_ BCM1 SG_ 427 ESC_Konsistenz_IPA 2000;
BA_REL_ "GenSigTimeoutTime" BU_SG_REL_ BCM1 SG_ 427 ESC_Fahrer_Bremsdruck_bestimmend 2000;
BA_REL_ "GenSigTimeoutTime" BU_SG_REL_ BCM1 SG_ 427 ESC_Verz_ASIL_Verfuegbarkeit 2000;
BA_REL_ "GenSigTimeoutTime" BU_SG_REL_ BCM1 SG_ 264 FA_Hoehenwerte_kalibriert 500;
BA_REL_ "GenSigTimeoutTime" BU_SG_REL_ BCM1 SG_ 264 FA_Hoehenwert_VL_00 500;
BA_REL_ "GenSigTimeoutTime" BU_SG_REL_ BCM1 SG_ 264 FA_Hoehenwert_HL_00 500;
BA_REL_ "GenSigTimeoutTime" BU_SG_REL_ BCM1 SG_ 429 NR_Reglerstatus 5000;
BA_REL_ "GenSigTimeoutTime" BU_SG_REL_ BCM1 SG_ 429 NR_LED_SGN 5000;
BA_REL_ "GenSigTimeoutTime" BU_SG_REL_ BCM1 SG_ 429 NR_LED_TN 5000;
BA_REL_ "GenSigTimeoutTime" BU_SG_REL_ BCM1 SG_ 429 NR_LED_BN 5000;
BA_REL_ "GenSigTimeoutTime" BU_SG_REL_ BCM1 SG_ 429 NR_LED_HN 5000;
BA_REL_ "GenSigTimeoutTime" BU_SG_REL_ BCM1 SG_ 1605 FLA_aktiv 5000;
BA_REL_ "GenSigTimeoutTime" BU_SG_REL_ BCM1 SG_ 1605 FLA_ISP_defekt 5000;
BA_REL_ "GenSigTimeoutTime" BU_SG_REL_ BCM1 SG_ 1605 FLA_Sensor_blockiert 5000;
BA_REL_ "GenSigTimeoutTime" BU_SG_REL_ BCM1 SG_ 1605 FLA_Fernlicht_PWM 5000;
BA_REL_ "GenSigTimeoutTime" BU_SG_REL_ BCM1 SG_ 1605 FLA_Aufblenden 5000;
BA_REL_ "GenSigTimeoutTime" BU_SG_REL_ BCM1 SG_ 2589283684 FoD_Transmission_Info 5000;
BA_REL_ "GenSigTimeoutTime" BU_SG_REL_ BCM1 SG_ 1523 I_Heiz_Frontscheibe 2000;
BA_REL_ "GenSigTimeoutTime" BU_SG_REL_ BCM1 SG_ 173 GE_Fahrstufe 1000;
BA_REL_ "GenSigTimeoutTime" BU_SG_REL_ BCM1 SG_ 173 GE_Zielgang 1000;
BA_REL_ "GenSigTimeoutTime" BU_SG_REL_ BCM1 SG_ 177 GE_Freilauf_Status 5000;
BA_REL_ "GenSigTimeoutTime" BU_SG_REL_ BCM1 SG_ 310 HAL_01_CRC 500;
BA_REL_ "GenSigTimeoutTime" BU_SG_REL_ BCM1 SG_ 310 HAL_01_BZ 500;
BA_REL_ "GenSigTimeoutTime" BU_SG_REL_ BCM1 SG_ 310 HAL_Status 500;
BA_REL_ "GenSigTimeoutTime" BU_SG_REL_ BCM1 SG_ 310 HAL_VZ_Radwinkel 500;
BA_REL_ "GenSigTimeoutTime" BU_SG_REL_ BCM1 SG_ 310 HAL_QBit_Radwinkel 500;
BA_REL_ "GenSigTimeoutTime" BU_SG_REL_ BCM1 SG_ 310 HAL_Radwinkel 500;
BA_REL_ "GenSigTimeoutTime" BU_SG_REL_ BCM1 SG_ 310 HAL_VZ_Fahrerwunschwinkel_Soll 500;
BA_REL_ "GenSigTimeoutTime" BU_SG_REL_ BCM1 SG_ 310 HAL_Fahrerwunschwinkel_Soll 500;
BA_REL_ "GenSigTimeoutTime" BU_SG_REL_ BCM1 SG_ 310 HAL_max_Gradient 500;
BA_REL_ "GenSigTimeoutTime" BU_SG_REL_ BCM1 SG_ 676 HAL_02_CRC 500;
BA_REL_ "GenSigTimeoutTime" BU_SG_REL_ BCM1 SG_ 676 HAL_02_BZ 500;
BA_REL_ "GenSigTimeoutTime" BU_SG_REL_ BCM1 SG_ 676 HAL_ARA_Status 500;
BA_REL_ "GenSigTimeoutTime" BU_SG_REL_ BCM1 SG_ 676 HAL_PLA_Status 500;
BA_REL_ "GenSigTimeoutTime" BU_SG_REL_ BCM1 SG_ 676 HAL_PWR_Abbruch 500;
BA_REL_ "GenSigTimeoutTime" BU_SG_REL_ BCM1 SG_ 676 HAL_PWR_Fehler 500;
BA_REL_ "GenSigTimeoutTime" BU_SG_REL_ BCM1 SG_ 1410 HD_Endstellung_oben 2000;
BA_REL_ "GenSigTimeoutTime" BU_SG_REL_ BCM1 SG_ 1410 HD_Endstellung_unten 2000;
BA_REL_ "GenSigTimeoutTime" BU_SG_REL_ BCM1 SG_ 1410 HD_Bewegung_zu 2000;
BA_REL_ "GenSigTimeoutTime" BU_SG_REL_ BCM1 SG_ 1410 HD_Position 2000;
BA_REL_ "GenSigTimeoutTime" BU_SG_REL_ BCM1 SG_ 1016 HLR_FlHz_Freigabe_Ruhesitz 5000;
BA_REL_ "GenSigTimeoutTime" BU_SG_REL_ BCM1 SG_ 1016 HLR_FlHz_Freigabe_VR 5000;
BA_REL_ "GenSigTimeoutTime" BU_SG_REL_ BCM1 SG_ 1016 HLR_FlHz_Freigabe_VL 5000;
BA_REL_ "GenSigTimeoutTime" BU_SG_REL_ BCM1 SG_ 1016 HLR_FlHz_Freigabe_HR 5000;
BA_REL_ "GenSigTimeoutTime" BU_SG_REL_ BCM1 SG_ 1016 HLR_FlHz_Freigabe_HL 5000;
BA_REL_ "GenSigTimeoutTime" BU_SG_REL_ BCM1 SG_ 1016 HLR_TCH_Freigabe 5000;
BA_REL_ "GenSigTimeoutTime" BU_SG_REL_ BCM1 SG_ 1016 HLR_SIH_Freigabe_Fond 5000;
BA_REL_ "GenSigTimeoutTime" BU_SG_REL_ BCM1 SG_ 1016 HLR_KRH_Freigabe_VL 5000;
BA_REL_ "GenSigTimeoutTime" BU_SG_REL_ BCM1 SG_ 1016 HLR_KRH_Freigabe_VR 5000;
BA_REL_ "GenSigTimeoutTime" BU_SG_REL_ BCM1 SG_ 1016 HLR_SIH_Freigabe_VL 5000;
BA_REL_ "GenSigTimeoutTime" BU_SG_REL_ BCM1 SG_ 1016 HLR_SIH_Freigabe_VR 5000;
BA_REL_ "GenSigTimeoutTime" BU_SG_REL_ BCM1 SG_ 1016 HLR_SIH_Freigabe_HL 5000;
BA_REL_ "GenSigTimeoutTime" BU_SG_REL_ BCM1 SG_ 1016 HLR_SIH_Freigabe_HR 5000;
BA_REL_ "GenSigTimeoutTime" BU_SG_REL_ BCM1 SG_ 1016 HLR_SIL_Freigabe_VL 5000;
BA_REL_ "GenSigTimeoutTime" BU_SG_REL_ BCM1 SG_ 1016 HLR_SIL_Freigabe_VR 5000;
BA_REL_ "GenSigTimeoutTime" BU_SG_REL_ BCM1 SG_ 1016 HLR_SIL_Freigabe_HL 5000;
BA_REL_ "GenSigTimeoutTime" BU_SG_REL_ BCM1 SG_ 1016 HLR_SIL_Freigabe_HR 5000;
BA_REL_ "GenSigTimeoutTime" BU_SG_REL_ BCM1 SG_ 1016 HLR_FSH_Freigabe 5000;
BA_REL_ "GenSigTimeoutTime" BU_SG_REL_ BCM1 SG_ 1016 HLR_PTC_linear_Freigabe 5000;
BA_REL_ "GenSigTimeoutTime" BU_SG_REL_ BCM1 SG_ 1016 HLR_PTC_Freigabe 5000;
BA_REL_ "GenSigTimeoutTime" BU_SG_REL_ BCM1 SG_ 1283 HVK_HVPTC_Sollmodus 1000;
BA_REL_ "GenSigTimeoutTime" BU_SG_REL_ BCM1 SG_ 1381 HVLM_FreigabeKlimatisierung 1000;
BA_REL_ "GenSigTimeoutTime" BU_SG_REL_ BCM1 SG_ 1340 HVLM_STH_Betriebsmodus 1000;
BA_REL_ "GenSigTimeoutTime" BU_SG_REL_ BCM1 SG_ 1340 HVLM_Standklima_Timer_Status 1000;
BA_REL_ "GenSigTimeoutTime" BU_SG_REL_ BCM1 SG_ 1340 HVLM_VK_STH_Einsatz 1000;
BA_REL_ "GenSigTimeoutTime" BU_SG_REL_ BCM1 SG_ 1340 HVLM_VK_Modus 1000;
BA_REL_ "GenSigTimeoutTime" BU_SG_REL_ BCM1 SG_ 2589283485 HVLM_Dauer_Klima_02 5000;
BA_REL_ "GenSigTimeoutTime" BU_SG_REL_ BCM1 SG_ 2463978610 HVLM_Ladeanzeige_Anf 5000;
BA_REL_ "GenSigTimeoutTime" BU_SG_REL_ BCM1 SG_ 2463978610 HVLM_Ladeanzeige_Status 5000;
BA_REL_ "GenSigTimeoutTime" BU_SG_REL_ BCM1 SG_ 312 Parken_aktives_System 2000;
BA_REL_ "GenSigTimeoutTime" BU_SG_REL_ BCM1 SG_ 312 IPA_Status_IPA_TSK 2000;
BA_REL_ "GenSigTimeoutTime" BU_SG_REL_ BCM1 SG_ 312 IPA_PLA_LED 2000;
BA_REL_ "GenSigTimeoutTime" BU_SG_REL_ BCM1 SG_ 312 IPA_APS_LED 2000;
BA_REL_ "GenSigTimeoutTime" BU_SG_REL_ BCM1 SG_ 2527679583 Parken_Aktivierungslicht_Anf 5000;
BA_REL_ "GenSigTimeoutTime" BU_SG_REL_ BCM1 SG_ 2527679583 Parken_Fahrtrichtungslicht_Anf 5000;
BA_REL_ "GenSigTimeoutTime" BU_SG_REL_ BCM1 SG_ 2527679583 Parken_Lichtnachlauf_Anf 5000;
BA_REL_ "GenSigTimeoutTime" BU_SG_REL_ BCM1 SG_ 2527679583 Parken_Bestaetigungsblinken_Anf 5000;
BA_REL_ "GenSigTimeoutTime" BU_SG_REL_ BCM1 SG_ 2527679583 Parken_Fahrbereitschaftlicht_Anf 5000;
BA_REL_ "GenSigTimeoutTime" BU_SG_REL_ BCM1 SG_ 2463978614 KAS_Kritikalitaetslevel 2000;
BA_REL_ "GenSigTimeoutTime" BU_SG_REL_ BCM1 SG_ 2463978614 KAS_Anf_OPS 2000;
BA_REL_ "GenSigTimeoutTime" BU_SG_REL_ BCM1 SG_ 497 KY_HDF_Taste 5000;
BA_REL_ "GenSigTimeoutTime" BU_SG_REL_ BCM1 SG_ 497 KY_FT_Entriegelung_Autorisiert 5000;
BA_REL_ "GenSigTimeoutTime" BU_SG_REL_ BCM1 SG_ 497 KY_Front_Entr_Autorisiert 5000;
BA_REL_ "GenSigTimeoutTime" BU_SG_REL_ BCM1 SG_ 497 KY_Front_Verr_Autorisiert 5000;
BA_REL_ "GenSigTimeoutTime" BU_SG_REL_ BCM1 SG_ 497 KY_Bereich 5000;
BA_REL_ "GenSigTimeoutTime" BU_SG_REL_ BCM1 SG_ 497 KY_Position 5000;
BA_REL_ "GenSigTimeoutTime" BU_SG_REL_ BCM1 SG_ 497 Schluesselnr_Personalisierung 5000;
BA_REL_ "GenSigTimeoutTime" BU_SG_REL_ BCM1 SG_ 497 FFB_FDF_Taste 5000;
BA_REL_ "GenSigTimeoutTime" BU_SG_REL_ BCM1 SG_ 497 FFB_Joker_Taste 5000;
BA_REL_ "GenSigTimeoutTime" BU_SG_REL_ Gateway SG_ 1416 SIH_Stufe_LED_li 5000;
BA_REL_ "GenSigTimeoutTime" BU_SG_REL_ Gateway SG_ 1416 SIH_Stufe_LED_re 5000;
BA_REL_ "GenSigTimeoutTime" BU_SG_REL_ Gateway SG_ 1416 SIL_Stufe_LED_li 5000;
BA_REL_ "GenSigTimeoutTime" BU_SG_REL_ Gateway SG_ 1416 SIL_Stufe_LED_re 5000;
BA_REL_ "GenSigTimeoutTime" BU_SG_REL_ Gateway SG_ 1416 KRH_Stufe_LED_li 5000;
BA_REL_ "GenSigTimeoutTime" BU_SG_REL_ Gateway SG_ 1416 KRH_Stufe_LED_re 5000;
BA_REL_ "GenSigTimeoutTime" BU_SG_REL_ Gateway SG_ 1416 BCM1_TCH_HLR_Anf 5000;
BA_REL_ "GenSigTimeoutTime" BU_SG_REL_ Gateway SG_ 1416 SIL_Stufe_LED_HL 5000;
BA_REL_ "GenSigTimeoutTime" BU_SG_REL_ Gateway SG_ 1416 SIL_Stufe_LED_HR 5000;
BA_REL_ "GenSigTimeoutTime" BU_SG_REL_ Gateway SG_ 1416 SIH_Stufe_LED_HL 5000;
BA_REL_ "GenSigTimeoutTime" BU_SG_REL_ Gateway SG_ 1416 SIH_Stufe_LED_HR 5000;
BA_REL_ "GenSigTimeoutTime" BU_SG_REL_ Gateway SG_ 1524 IL_Innenlicht_aktiv 5000;
BA_REL_ "GenSigTimeoutTime" BU_SG_REL_ Gateway SG_ 1524 AMB_Charisma_FahrPr 5000;
BA_REL_ "GenSigTimeoutTime" BU_SG_REL_ Gateway SG_ 1524 AMB_Charisma_Status 5000;
BA_REL_ "GenSigTimeoutTime" BU_SG_REL_ Klima_MSB SG_ 177 GE_Freilauf_Status 5000;
BA_REL_ "GenSigTimeoutTime" BU_SG_REL_ Klima_MSB SG_ 1410 HD_Bewegung_zu 2000;
BA_REL_ "GenSigTimeoutTime" BU_SG_REL_ Klima_MSB SG_ 1416 SIH_Stufe_LED_li 5000;
BA_REL_ "GenSigTimeoutTime" BU_SG_REL_ Klima_MSB SG_ 1416 SIH_Stufe_LED_re 5000;
BA_REL_ "GenSigTimeoutTime" BU_SG_REL_ Klima_MSB SG_ 1416 SIL_Stufe_LED_li 5000;
BA_REL_ "GenSigTimeoutTime" BU_SG_REL_ Klima_MSB SG_ 1416 SIL_Stufe_LED_re 5000;
BA_REL_ "GenSigTimeoutTime" BU_SG_REL_ Klima_MSB SG_ 1416 KRH_Stufe_LED_li 5000;
BA_REL_ "GenSigTimeoutTime" BU_SG_REL_ Klima_MSB SG_ 1416 KRH_Stufe_LED_re 5000;
BA_REL_ "GenSigTimeoutTime" BU_SG_REL_ Klima_MSB SG_ 1416 SIL_Stufe_LED_HL 5000;
BA_REL_ "GenSigTimeoutTime" BU_SG_REL_ Klima_MSB SG_ 1416 SIL_Stufe_LED_HR 5000;
BA_REL_ "GenSigTimeoutTime" BU_SG_REL_ Klima_MSB SG_ 1416 SIH_Stufe_LED_HL 5000;
BA_REL_ "GenSigTimeoutTime" BU_SG_REL_ Klima_MSB SG_ 1416 SIH_Stufe_LED_HR 5000;
BA_REL_ "GenSigTimeoutTime" BU_SG_REL_ Klima_MSB SG_ 1016 HLR_SIH_Freigabe_HL 5000;
BA_REL_ "GenSigTimeoutTime" BU_SG_REL_ Klima_MSB SG_ 1016 HLR_SIH_Freigabe_HR 5000;
BA_REL_ "GenSigTimeoutTime" BU_SG_REL_ Klima_MSB SG_ 1016 HLR_SIL_Freigabe_HL 5000;
BA_REL_ "GenSigTimeoutTime" BU_SG_REL_ Klima_MSB SG_ 1016 HLR_SIL_Freigabe_HR 5000;
BA_REL_ "GenSigTimeoutTime" BU_SG_REL_ Klima_MSB SG_ 1016 HLR_FSH_Freigabe 5000;
BA_REL_ "GenSigTimeoutTime" BU_SG_REL_ Klima_MSB SG_ 1016 HLR_PTC_linear_Freigabe 5000;
BA_REL_ "GenSigTimeoutTime" BU_SG_REL_ Klima_MSB SG_ 1283 HVK_HVPTC_Sollmodus 1000;
BA_REL_ "GenSigTimeoutTime" BU_SG_REL_ Klima_MSB SG_ 1381 HVLM_FreigabeKlimatisierung 1000;
BA_REL_ "GenSigTimeoutTime" BU_SG_REL_ Klima_MSB SG_ 1340 HVLM_STH_Betriebsmodus 1000;
BA_REL_ "GenSigTimeoutTime" BU_SG_REL_ Klima_MSB SG_ 1340 HVLM_Standklima_Timer_Status 1000;
BA_REL_ "GenSigTimeoutTime" BU_SG_REL_ Klima_MSB SG_ 1340 HVLM_VK_Modus 1000;
BA_REL_ "GenSigTimeoutTime" BU_SG_REL_ Klima_MSB SG_ 2589283485 HVLM_Dauer_Klima_02 5000;
BA_REL_ "GenSigTimeoutTime" BU_SG_REL_ Klima_MSB SG_ 497 Schluesselnr_Personalisierung 5000;
BA_REL_ "GenSigTimeoutTime" BU_SG_REL_ Lift_VA SG_ 264 FA_Hoehenwerte_kalibriert 500;
BA_REL_ "GenSigTimeoutTime" BU_SG_REL_ Lift_VA SG_ 264 FA_Hoehenwert_VL_00 500;
BA_REL_ "GenSigTimeoutTime" BU_SG_REL_ Lift_VA SG_ 264 FA_Hoehenwert_VR_00 500;
BA_REL_ "GenSigTimeoutTime" BU_SG_REL_ Lift_VA SG_ 264 FA_Hoehenwert_HL_00 500;
BA_REL_ "GenSigTimeoutTime" BU_SG_REL_ Lift_VA SG_ 264 FA_Hoehenwert_HR_00 500;
BA_REL_ "GenSigTimeoutTime" BU_SG_REL_ VAS_L SG_ 264 FA_Hoehenwerte_kalibriert 500;
BA_REL_ "GenSigTimeoutTime" BU_SG_REL_ VAS_L SG_ 264 FA_Hoehenwert_VL_00 500;
BA_REL_ "GenSigTimeoutTime" BU_SG_REL_ VAS_L SG_ 264 FA_Hoehenwert_VR_00 500;
BA_REL_ "GenSigTimeoutTime" BU_SG_REL_ VAS_L SG_ 264 FA_Hoehenwert_HL_00 500;
BA_REL_ "GenSigTimeoutTime" BU_SG_REL_ VAS_L SG_ 264 FA_Hoehenwert_HR_00 500;
BA_REL_ "GenSigTimeoutTime" BU_SG_REL_ VAS_L SG_ 2527679583 Parken_Seitenspiegel_Anf 5000;
BA_REL_ "GenSigTimeoutTime" BU_SG_REL_ VAS_L SG_ 497 Schluesselnr_Personalisierung 5000;
BA_REL_ "GenSigTimeoutTime" BU_SG_REL_ VAS_R SG_ 264 FA_Hoehenwerte_kalibriert 500;
BA_REL_ "GenSigTimeoutTime" BU_SG_REL_ VAS_R SG_ 264 FA_Hoehenwert_VL_00 500;
BA_REL_ "GenSigTimeoutTime" BU_SG_REL_ VAS_R SG_ 264 FA_Hoehenwert_VR_00 500;
BA_REL_ "GenSigTimeoutTime" BU_SG_REL_ VAS_R SG_ 264 FA_Hoehenwert_HL_00 500;
BA_REL_ "GenSigTimeoutTime" BU_SG_REL_ VAS_R SG_ 264 FA_Hoehenwert_HR_00 500;
BA_REL_ "GenSigTimeoutTime" BU_SG_REL_ VAS_R SG_ 2527679583 Parken_Seitenspiegel_Anf 5000;
BA_REL_ "GenSigTimeoutTime" BU_SG_REL_ VAS_R SG_ 497 Schluesselnr_Personalisierung 5000;
VAL_ 427 ESC_AHW_aktiv 0 "keine_Aktivitaet" 1 "Aktivitaet_durch_IPA" 2 "Aktivitaet_durch_ARA" 3 "Aktivitaet_durch_ACC" 4 "tbd" 5 "tbd" 6 "tbd" 7 "tbd" ;
VAL_ 427 ESC_AHW_nicht_verfuegbar 0 "verfuegbar" 1 "nicht_verfuegbar" ;
VAL_ 427 ESC_ANB_CM_aktiv 0 "keine_Aktivitaet" 1 "Aktivitaet_durch_AWV" ;
VAL_ 427 ESC_ANB_CM_nicht_verfuegbar 0 "verfuegbar" 1 "nicht_verfuegbar" ;
VAL_ 427 ESC_Warnruck_aktiv 0 "keine_Aktivitaet" 1 "Aktivitaet_durch_AWV" 2 "Aktivitaet_durch_vFGS" 3 "Aktivitaet_durch_RCTA" 4 "Aktivitaet_durch_FCWO" 5 "Aktivitaet_durch_FCWP" 6 "Aktivitaet_durch_EA" 7 "Aktivitaet_durch_PCF" 8 "Aktivitaet_durch_KAS" 9 "Aktivitaet_durch_AGW" ;
VAL_ 427 ESC_Warnruck_nicht_verfuegbar 0 "verfuegbar" 1 "nicht_verfuegbar" ;
VAL_ 427 ESC_Prefill_aktiv 0 "keine_Aktivitaet" 1 "Prefill_aktiv" ;
VAL_ 427 ESC_Prefill_nicht_verfuegbar 0 "verfuegbar" 1 "nicht_verfuegbar" ;
VAL_ 427 ESC_HBA_aktiv 0 "keine_Aktivitaet" 1 "HBA_aktiv" ;
VAL_ 427 ESC_HBA_nicht_verfuegbar 0 "verfuegbar" 1 "nicht_verfuegbar" ;
VAL_ 427 ESC_TSK_SRBM_Anf 0 "keine_Aktivitaet" 1 "Aktivitaet_durch_TSK" ;
VAL_ 427 ESC_TSK_SRBM_nicht_verfuegbar 0 "verfuegbar" 1 "nicht_verfuegbar" ;
VAL_ 427 ESC_Verz_Reg_aktiv 0 "keine_Aktivitaet" 1 "Aktivitaet_TB_durch_AWV" 2 "Aktivitaet_ZB_durch_AWV" 3 "Aktivitaet_durch_vFGS" 4 "Aktivitaet_durch_TSK" 5 "Aktivitaet_durch_RCTA" 6 "Aktivitaet_durch_PLA_IPA" 7 "Aktivitaet_durch_STA" 8 "Aktivitaet_durch_ARA" 9 "Aktivitaet_durch_MKB" 10 "Aktivitaet_durch_BFF" 11 "Aktivitaet_durch_FAS_VK" 12 "Aktivitaet_durch_PCF" 13 "Aktivitaet_durch_KAS" 14 "Aktivitaet_durch_BRS_intern" 15 "reserviert" ;
VAL_ 427 ESC_Verz_Reg_nicht_verfuegbar 0 "verfuegbar" 1 "nicht_verfuegbar" ;
VAL_ 427 ESC_Verz_Reg_TB_nicht_verfuegbar 0 "verfuegbar" 1 "nicht_verfuegbar" ;
VAL_ 427 ESC_Verz_Reg_ZB_nicht_verfuegbar 0 "verfuegbar" 1 "nicht_verfuegbar" ;
VAL_ 427 ESC_Bremslicht_unplausibel 0 "plausibel" 1 "unplausibel" ;
VAL_ 427 ESC_Konsistenz_ACC 0 "konsistent" 1 "nicht_konsistent" ;
VAL_ 427 ESC_Konsistenz_AWV 0 "konsistent" 1 "nicht_konsistent" ;
VAL_ 427 ESC_Konsistenz_ARA 0 "konsistent" 1 "nicht_konsistent" ;
VAL_ 427 ESC_Konsistenz_IPA 0 "konsistent" 1 "nicht_konsistent" ;
VAL_ 427 ESC_Konsistenz_FCW 0 "konsistent" 1 "nicht_konsistent" ;
VAL_ 427 ESC_Konsistenz_NV 0 "konsistent" 1 "nicht_konsistent" ;
VAL_ 427 ESC_Konsistenz_RCTA 0 "konsistent" 1 "nicht_konsistent" ;
VAL_ 427 ESC_Konsistenz_TSK 0 "konsistent" 1 "nicht_konsistent" ;
VAL_ 427 ESC_Konsistenz_vFGS 0 "konsistent" 1 "nicht_konsistent" ;
VAL_ 427 ESC_Konsistenz_STA 0 "konsistent" 1 "nicht_konsistent" ;
VAL_ 427 ESC_Fahrer_Bremsdruck_bestimmend 0 "Fahrer_nicht_Bremsdruck_bestimmend" 1 "Fahrer_Bremsdruck_bestimmend" ;
VAL_ 427 ESC_Konsistenz_EA 0 "konsistent" 1 "nicht_konsistent" ;
VAL_ 427 ESC_Konsistenz_BFF 0 "konsistent" 1 "nicht_konsistent" ;
VAL_ 427 ESC_Konsistenz_MKB 0 "konsistent" 1 "nicht_konsistent" ;
VAL_ 427 ESC_Verz_ASIL_Verfuegbarkeit 0 "Nicht_verfuegbar" 1 "Verfuegbar_ab_ASIL_QM" 2 "Verfuegbar_ab_ASIL_A" 3 "Verfuegbar_ab_ASIL_B" 4 "Verfuegbar_ab_ASIL_C" 5 "reserved" 6 "reserved" 7 "reserved" ;
VAL_ 427 ESC_Pumpenanlauf_aktiv 0 "inaktiv" 1 "aktiv" ;
VAL_ 427 ESC_Konsistenz_AGW 0 "konsistent" 1 "nicht_konsistent" ;
VAL_ 427 ESC_Konsistenz_KAS 0 "konsistent" 1 "nicht_konsistent" ;
VAL_ 427 ESC_Konsistenz_PCF 0 "konsistent" 1 "nicht_konsistent" ;
VAL_ 427 ESC_Konsistenz_FAS_VK 0 "konsistent" 1 "nicht_konsistent" ;
VAL_ 427 ESC_Verz_Begrenzung 0 "keine_Begrenzung" 1 "Begrenzung_aktiv" ;
VAL_ 427 ESC_Konsistenz_AWA 0 "konsistent" 1 "nicht_konsistent" ;
VAL_ 264 FA_Hoehenwerte_kalibriert 0 "kalibrierte_Hoehenwerte_in_mm" 1 "Rohwerte" ;
VAL_ 264 FA_Hoehenwert_VL_00 254 "nicht initialisiert" 255 "Fehler" ;
VAL_ 264 FA_Hoehenwert_VR_00 254 "nicht initialisiert" 255 "Fehler" ;
VAL_ 264 FA_Hoehenwert_HL_00 254 "nicht initialisiert" 255 "Fehler" ;
VAL_ 264 FA_Hoehenwert_HR_00 254 "nicht initialisiert" 255 "Fehler" ;
VAL_ 264 FA_Fahrbahnunebenheit 254 "Init" 255 "Fehler" ;
VAL_ 429 NR_Reglerstatus 0 "nicht_definiert" 1 "Hochniveau_2" 2 "Hochniveau_1" 3 "Zwischenniveau" 4 "Normalniveau" 5 "Tiefniveau_1" 6 "Tiefniveau_2" 7 "Tiefniveau_3" 8 "Verladeniveau" 9 "Beladungsniveau" 10 "Heckabsenkung" ;
VAL_ 429 FA_Verstellung_in_Kuerze 0 "keine_Verstellung_erwartet" 1 "Verstellung_erwartet" ;
VAL_ 429 FA_Verstellung_aktiv 0 "keine_Verstellung" 1 "Verstellung_aktiv" ;
VAL_ 429 FA_Kompressor_laeuft_in_Kuerze 0 "kein_Kompressorlauf_erwartet" 1 "Kompressorlauf_steht_bevor" ;
VAL_ 429 FA_Kompressor_laeuft 0 "Kompressor_nicht_angesteuert" 1 "Kompressor_angesteuert" ;
VAL_ 429 NR_Anforderung_v_Begrenzung 0 "keine_Begrenzung_angefordert" 1 "Sicherheitsbegrenzung_1_aktiv" 2 "Sicherheitsbegrenzung_2_aktiv" 3 "Komfortbegrenzung_aktiv" ;
VAL_ 429 NR_LED_SGN 0 "LED_aus" 1 "LED_ein" ;
VAL_ 429 NR_LED_TN 0 "LED_aus" 1 "LED_ein" ;
VAL_ 429 NR_LED_BN 0 "LED_aus" 1 "LED_ein" ;
VAL_ 429 FA_Absenkung_Fahrzeug 0 "keine_Absenkung" 1 "Absenkung_Fahrzeug" ;
VAL_ 429 FA_Anhaengerstatus_intern 0 "Anhaenger_intern_nicht_erkannt" 1 "Anhaenger_intern_erkannt_manuell" 2 "Anhaenger_intern_erkannt_automatisch" 3 "Anhaenger_intern_erkannt_automatisch_manuelle_Deaktivierung_aktiv" 4 "Anhaenger_intern_erkannt_Failsafe" ;
VAL_ 429 FA_Anhebung_Fahrzeug 0 "keine_Anhebung" 1 "Anhebung_Fahrzeug" ;
VAL_ 429 FA_Druckspeicher_verfuegbar 0 "Druckspeicher_nicht_verfuegbar" 1 "Regelung_aus_Druckspeicher_moeglich" ;
VAL_ 429 FA_HAL_Abschaltung 0 "keine_Beeinflussung" 1 "Abschaltung_angefordert" ;
VAL_ 429 FA_ESP_Zuschaltung 0 "keine_ESP_Beeinflussung" 1 "ESP_Zwangszuschaltung_angefordert" ;
VAL_ 429 NR_LED_HN 0 "LED_aus" 1 "LED_ein" ;
VAL_ 429 FA_Zwischenniveau 0 "kein_Zwischenniveau" 1 "Zwischenniveau" ;
VAL_ 429 FA_Systemstatus 0 "nicht_funktionsfaehig" 1 "funktionsfaehig" ;
VAL_ 429 EFP_Soll_FahrPr_HAL 0 "nicht_gesteuert" 1 "Zwang_Programm_1" 2 "Zwang_Programm_2" 3 "Zwang_Programm_3" 4 "Zwang_Programm_4" 5 "Zwang_Programm_5" 6 "Zwang_Programm_6" 7 "Zwang_Programm_7" 8 "Zwang_Programm_8" 9 "Zwang_Programm_9" 10 "Zwang_Programm_10" 11 "Zwang_Programm_11" 12 "Zwang_Programm_12" 13 "Zwang_Programm_13" 14 "Zwang_Programm_14" 15 "Zwang_Programm_15" ;
VAL_ 429 NR_Kompressor_Strom_02 255 "Fehler" ;
VAL_ 429 NR_Kompressor_Temp_Zylinderkopf 254 "Init" 255 "Fehler" ;
VAL_ 429 FA_Signal_Drucksensor 254 "Init" 255 "Fehler" ;
VAL_ 1605 FLA_aktiv 0 "inaktiv" 1 "aktiv" ;
VAL_ 1605 FLA_ISP_defekt 0 "iO" 1 "defekt" ;
VAL_ 1605 FLA_Sensor_blockiert 0 "Sensor in Ordnung" 1 "Sensor blockiert" ;
VAL_ 1605 FLA_Abblendursache 0 "nichts erkannt (Init-Wert) " 1 "enentgegenkommendes Fahrzeug (Scheinwerfer erkannt) " 2 "vorausfahrendes Fahrzeug (Heckleuchten erkannt) " 4 "Geschwindigkeitslimit unterschritten" 8 "Ortschaft_erkannt" 16 "Umgebungshelligkeit_generell_zu_hell" 32 "Nebel erkannt " 64 "Übertemperatur Imager" 128 "Verzögerungsbedingung" 255 "Fehler" ;
VAL_ 1605 FLA_Fernlicht_PWM 127 "Fehler" ;
VAL_ 1605 ISP_EC_Lichtwert_vorne 62 "Init" 63 "Fehler" ;
VAL_ 1605 ISP_EC_Lichtwert_hinten 62 "Init" 63 "Fehler" ;
VAL_ 1605 ISP_Himmelsrichtung 30 "nicht verfuegbar bzw. Init" 31 "Fehler" ;
VAL_ 1605 ISP_Taste_betaetigt 0 "nicht_betaetigt" 1 "betaetigt" ;
VAL_ 1605 ISP_EC_aktiv 0 "inaktiv" 1 "aktiv" ;
VAL_ 1605 ISP_Kompass_aktiv 0 "inaktiv" 1 "aktiv" ;
VAL_ 1605 FLA_Aufblenden 0 "nicht_aufblenden" 1 "aufblenden" ;
VAL_ 1605 FLA_SAE_Mode 0 "Init" 1 "FLA_Icon_invertiert" ;
VAL_ 2589283684 FoD_Transmission_Info 0 "Initwert" 1 "start_transmission" 2 "finish_transmission" ;
VAL_ 2589283684 FoD_Anz_Funktionsabschaltung 0 "Init" 1 "Popup_aufschalten" ;
VAL_ 2549875470 FoD_BCM1_Req_Data 0 "Init" ;
VAL_ 2550006542 FoD_BCM1_Resp_Data 0 "Init" ;
VAL_ 1523 P_Heiz_Frontscheibe 254 " Messwert nicht verfuegbar" 255 "Fehler" ;
VAL_ 1523 I_Heiz_Frontscheibe 254 "Messwert nicht verfuegbar" 255 "Fehler" ;
VAL_ 1523 Diag_Frontscheibe 1 "Unterer Grenzwert unterschritten" 2 "Oberer Grenzwert ueberschritten" 4 " zur Zeit nicht pruefbar" 8 " Unterbrechung" 16 " El. Fehler im Stromkreis" 32 " El. Fehler im Stromkreis" 128 "Defekt" ;
VAL_ 1523 R_grenz_min 254 "Messwert nicht verfuegbar" 255 "Fehler" ;
VAL_ 1523 R_grenz_max 254 "Messwert nicht verfuegbar" 255 "Fehler" ;
VAL_ 1523 R_ist 254 "Messwert nicht verfuegbar" 255 "Fehler" ;
VAL_ 1523 FSW_Lokalaktiv 0 "war_nicht_lokal_aktiv" 1 "war_lokal_aktiv" ;
VAL_ 1523 FSH_LED 0 "Aus" 1 "Ein" ;
VAL_ 173 GE_MMom_Soll_02 1022 "keine_Anforderung_Init" 1023 "Fehler" ;
VAL_ 173 GE_MMom_Vorhalt_02 1022 "Init" 1023 "Fehler" ;
VAL_ 173 GE_Uefkt 1023 "Fehler" ;
VAL_ 173 GE_Fahrstufe 0 "Zwischenstellung" 1 "Init" 5 "Position_P" 6 "Position_R" 7 "Position_N" 8 "Position_D" 9 "Position_S" 10 "Effizienz" 13 "Tipp_in_S" 14 "Tipp_in_D" 15 "Fehler" ;
VAL_ 173 GE_Schaltablauf 0 "keine_Schaltung" 1 "Momentenueberschneidung" 2 "Befuellphase" 3 "Drehzahlueberfuehrung" ;
VAL_ 173 GE_Uefkt_unplausibel 0 "Uefkt_plausibel" 1 "Uefkt_unplausibel" ;
VAL_ 173 GE_MMom_Status_02 0 "kein_Eingriff" 1 "abs_reduzierender_Eingriff_auf_Gesamt_Antrieb_nur_schneller_Pfad" 2 "abs_erhoehender_Eingriff_auf_Gesamt_Antrieb" 3 "relativer_Eingriff_auf_Gesamt_Antrieb" 4 "relativer_Eingriff_auf_E_Maschine" 5 "abs_red_Eingr_auf_Gesamt_Antrieb_nur_Luftpfad" 6 "abs_red_Eingr_auf_Gesamt_Antrieb_Luft-_und_schnellen_Pfad" 7 "abs_Eingriff_auf_Gesamtantrieb_erhoehend_und_reduzierend" ;
VAL_ 173 GE_Status_Kraftschluss 0 "offen_kein_Kraftschluss" 1 "offen_mit_Kraftschluss" 2 "schlupfend_geregelt" 3 "abgesichert_offen_kein_Kraftschl" 4 "geschlossen_mit_Mikroschlupf" 5 "geschlossen_mit_Ueberanpressung" 6 "sonstige_Fehler" 7 "fehlerhaft_geschlossen" ;
VAL_ 173 GE_MMom_Status 0 "keine Anforderung" 1 "reduzierender Getriebeeingriff" 2 "erhöhender Getriebeeingriff" 3 "Änderung mit Sprung" ;
VAL_ 173 GE_Freig_MMom_Vorhalt 0 "nicht_freigegeben" 1 "freigegeben" ;
VAL_ 173 GE_Verbot_Ausblendung 0 "kein_Verbot" 1 "Verbot" ;
VAL_ 173 GE_Zielgang 0 "Gang P/N (ausgekuppelt)" 1 "Gang 1" 2 "Gang 2" 3 "Gang 3" 4 "Gang 4" 5 "Gang 5" 6 "Gang 6" 7 "Gang 7" 8 "Gang R" 11 "Gang 8" 12 "Gang 9" 13 "Gang10" 14 "Istgang nicht definiert" 15 "Fehler" ;
VAL_ 177 GE_Fahrprogramm 0 "Init" 1 "nicht_belegt" 2 "Normal" 3 "Sport" 4 "Offroad" 5 "Efficiency" 6 "Sport_Plus" 7 "Sport_Response" 10 "Snow" 11 "Gravel" 12 "Mud_Ruts" 13 "Sand_Dune" ;
VAL_ 177 GE_TippZustand 0 "Init_Kein_Tipp" 1 "Tipp_permanent" 2 "Tipp_temporaer" ;
VAL_ 177 GE_Freilauf_Status 0 "Freilauf_inaktiv_aber_moeglich" 1 "Freilauf_aktiv" 2 "Freilauf_nicht_moegl_1Verhinderer" 3 "Freilauf_nicht_moegl_gr_1Verhinderer" 7 "Fehler" ;
VAL_ 177 GE_Grundeinstellung 0 "inaktiv" 1 "aktiv" ;
VAL_ 177 GE_Anschleppstart_Freigabe 0 "keine_Freigabe" 1 "Freigabe" ;
VAL_ 177 GE_Strombedarf_erh 0 "keine_Anforderung" 1 "erhoehte_Anforderung" ;
VAL_ 177 GE_Uefkt_Praed 16383 "Fehler" ;
VAL_ 177 GE_KomFehler_ESP 0 "kein_Fehler" 1 "Fehler" ;
VAL_ 177 GE_Rollrichtung_falsch 0 "richtige_Rollrichtung_o_Init" 1 "falsche_Rollrichtung" ;
VAL_ 177 GE_Getriebestatus_02 0 "inaktiv" 1 "Rennstartvorbereitung" 2 "Rennstart" 3 "Anfahrt" 4 "Anfahrt_Komfort" 5 "Anfahrt_Leerlaufregler" 6 "bereit_zur_Ueberanpressung" 7 "Low_Speed_Modus" 8 "eLaunch" ;
VAL_ 177 GE_Eingangsdrehz_Praed 16382 "Init" 16383 "Fehler" ;
VAL_ 310 HAL_Status 0 "Normalbetrieb" 1 "Lenkungsausfall" 2 "Derating_aktiv" 3 "Lenkung_manuell_deaktiviert" ;
VAL_ 310 HAL_VZ_Radwinkel 0 "positiv_Lenkeinschlag_links" 1 "negativ_Lenkeinschlag_rechts" ;
VAL_ 310 HAL_QBit_Radwinkel 0 "gueltiger_Wert" 1 "Ersatz_Init_oder_Fehlerwert" ;
VAL_ 310 HAL_Radwinkel 1020 "Unterspannung" 1021 "nicht_kalibriert" 1022 "Init" 1023 "Fehler" ;
VAL_ 310 HAL_Warnungen 0 "keine_Warnung" 1 "Ausfall_rote_Warnung" 2 "Systemstoerung_gelbe_Warnung" 3 "HAL_deaktiviert" ;
VAL_ 310 HAL_Winkelbegrenzung 0 "nicht_aktiv" 1 "Lenkwinkelbegrenzung_aktiv" ;
VAL_ 310 HAL_VZ_Fahrerwunschwinkel_Soll 0 "positiv" 1 "negativ" ;
VAL_ 310 HAL_Fahrerwunschwinkel_Soll 1022 "Init" 1023 "Fehler" ;
VAL_ 310 HAL_max_Gradient 126 "Init" 127 "Fehler" ;
VAL_ 310 HAL_EFP_FahrPr 0 "keine_Funktion" 1 "Programm_1" 2 "Programm_2" 3 "Programm_3" 4 "Programm_4" 5 "Programm_5" 6 "Programm_6" 7 "Programm_7" 8 "Programm_8" 9 "Programm_9" 10 "Programm_10" 11 "Programm_11" 12 "Programm_12" 13 "Programm_13" 14 "Programm_14" 15 "Programm_15" ;
VAL_ 310 HAL_Charisma_Status 0 "Init" 1 "verfuegbar" 2 "nicht_verfuegbar" 3 "asynchron_durch_Fahrerwunsch" ;
VAL_ 310 HAL_Charisma_FahrPr 0 "keine_Funktion" 1 "Programm_1" 2 "Programm_2" 3 "Programm_3" 4 "Programm_4" 5 "Programm_5" 6 "Programm_6" 7 "Programm_7" 8 "Programm_8" 9 "Programm_9" 10 "Programm_10" 11 "Programm_11" 12 "Programm_12" 13 "Programm_13" 14 "Programm_14" 15 "Programm_15" ;
VAL_ 676 HAL_IL_Status 0 "HAL_IL_nicht_aktiv" 1 "HAL_IL_Init" 2 "HAL_IL_funktionsbereit" 3 "HAL_IL_Winkelregelung_aktiv" 4 "HAL_IL_Fehler_dauer_mit_Rueckfuehr" 5 "HAL_IL_Fehler_dauer_ohne_Rueckfuehr" 6 "HAL_IL_Fehler_temp_mit_Rueckfuehr" 7 "nicht_belegt" 8 "HAL_IL_nicht_verfuegbar" ;
VAL_ 676 HAL_ARA_Status 0 "HAL_ARA_Deaktiv" 1 "HAL_ARA_Init" 2 "HAL_ARA_Fehler_mit_Eintrag" 3 "reserviert" 4 "reserviert" 5 "reserviert" 6 "HAL_ARA_Lenkwinkel_aktiv" 7 "HAL_ARA_Abgewiesen" 8 "HAL_ARA_Funktionsbereit" 9 "reserviert" 10 "HAL_ARA_Abbruch" 11 "reserviert" 12 "reserviert" 13 "reserviert" 14 "reserviert" 15 "reserviert" ;
VAL_ 676 HAL_PLA_Status 0 "HAL_PLA_Deaktiv" 1 "HAL_PLA_Init" 2 "HAL_PLA_Fehler_mit_Eintrag" 3 "reserviert" 4 "reserviert" 5 "reserviert" 6 "HAL_PLA_Lenkwinkel_aktiv" 7 "HAL_PLA_Abgewiesen" 8 "HAL_PLA_Funktionsbereit" 9 "reserviert" 10 "HAL_PLA_Abbruch" 11 "reserviert" 12 "reserviert" 13 "reserviert" 14 "reserviert" 15 "reserviert" ;
VAL_ 676 HAL_PWR_Abbruch 0 "Init/Invalid" 1 "PWR beendet durch HAL-SG wegen vFzg" 2 "PWR beendet durch HAL-SG wegen HM" 3 "Radwinkeldifferenz zu groß" 4 "Gradient der Zielanforderung zu groß" 5 "reserviert" 6 "reserviert" 7 "reserviert" 8 "Falscher PLA-Status" 9 "Falscher ARA-Status" 10 "reserviert" 11 "reserviert" 12 "reserviert" 13 "reserviert" 14 "reserviert" 15 "reserviert" ;
VAL_ 676 HAL_PWR_Fehler 0 "Init/Invalid" 1 "Verfügbarkeit zu gering" 2 "reserviert" 3 "Rotorwinkel nicht initialisiert" 4 "BCM1/Rückfahrlicht veraltet" 5 "reserviert" 6 "reserviert" 7 "Fehler ESP(vFzg)" 8 "Fehler ESP(Raddrehzahlen)" 9 "reserviert" 10 "reserviert" 11 "reserviert" 12 "reserviert" 13 "reserviert" 14 "HAL_ARA_Satus == 6" 15 "HAL_PLA_Satus == 6" ;
VAL_ 1410 HD_Endstellung_oben 1 "HD in Endstellung oben (offen)" ;
VAL_ 1410 HD_Endstellung_unten 1 "HD in Endstellung unten (geschlossen)" ;
VAL_ 1410 HD_Bewegung_auf 1 "HD in Bewegung auf" ;
VAL_ 1410 HD_Bewegung_zu 1 "HD in Bewegung zu" ;
VAL_ 1410 HD_Innentaster_betaetigt 0 "HD_Innentaster_nicht_betaetigt" 1 "HD_Innentaster_betaetigt" ;
VAL_ 1410 HD_UeKB_erkannt 1 "Einklemmschutz aktiv" ;
VAL_ 1410 HD_Taster_defekt 0 "Taster_funktionsfähig" 1 "Taster defekt" ;
VAL_ 1410 HD_Rueckmeld_prog 0 "keine Rueckmeldung" 1 "Rueckmeldung zur Programmierung Endstellung aktiv" ;
VAL_ 1410 HD_Verriegelungstaster_betaetigt 0 "Taster_nicht_betaetigt" 1 "Taster_betaetigt" ;
VAL_ 1410 HD_Verr_Taster_betaetigt_inv 0 "Taster_betaetigt" 1 "Taster_nicht_betaetigt" ;
VAL_ 1410 HD_ZZH_Schalter_S3 0 "nicht_betaetigt" 1 "betaetigt" ;
VAL_ 1416 FSH_LED 0 "Aus" 1 "Ein" ;
VAL_ 1416 HSH_LED 0 "Aus" 1 "Ein" ;
VAL_ 1416 SIH_Stufe_LED_li 0 "Aus" 2 "Stufe_2" 4 "Stufe_4" 6 "Stufe_6" ;
VAL_ 1416 SIH_Stufe_LED_re 0 "Aus" 2 "Stufe_2" 4 "Stufe_4" 6 "Stufe_6" ;
VAL_ 1416 SIL_Stufe_LED_li 0 "Aus" 1 "Stufe_1" 2 "Stufe_2" 3 "Stufe_3" 4 "Stufe_4" 5 "Stufe_5" 6 "Stufe_6" ;
VAL_ 1416 SIL_Stufe_LED_re 0 "Aus" 1 "Stufe_1" 2 "Stufe_2" 3 "Stufe_3" 4 "Stufe_4" 5 "Stufe_5" 6 "Stufe_6" ;
VAL_ 1416 KRH_Stufe_LED_li 0 "Aus" 1 "Stufe_1" 2 "Stufe_2" 3 "Stufe_3" ;
VAL_ 1416 KRH_Stufe_LED_re 0 "Aus" 1 "Stufe_1" 2 "Stufe_2" 3 "Stufe_3" ;
VAL_ 1416 BCM1_TCH_HLR_Anf 0 "keine_Anforderung" 1 "Anforderung" ;
VAL_ 1416 HLR_SIH_Freigabe_Fond 0 "keine_Freigabe" 1 "Freigabe" ;
VAL_ 1416 SIL_Stufe_LED_HL 0 "Aus" 1 "Stufe_1" 2 "Stufe_2" 3 "Stufe_3" 4 "Stufe_4" 5 "Stufe_5" 6 "Stufe_6" ;
VAL_ 1416 SIL_Stufe_LED_HR 0 "Aus" 1 "Stufe_1" 2 "Stufe_2" 3 "Stufe_3" 4 "Stufe_4" 5 "Stufe_5" 6 "Stufe_6" ;
VAL_ 1416 SIH_Stufe_LED_HL 0 "Aus" 1 "Stufe_1" 2 "Stufe_2" 3 "Stufe_3" 4 "Stufe_4" 5 "Stufe_5" 6 "Stufe_6" ;
VAL_ 1416 SIH_Stufe_LED_HR 0 "Aus" 1 "Stufe_1" 2 "Stufe_2" 3 "Stufe_3" 4 "Stufe_4" 5 "Stufe_5" 6 "Stufe_6" ;
VAL_ 1016 HLR_FlHz_Freigabe_Ruhesitz 0 "0_Prozent" 1 "33_Prozent" 2 "66_Prozent" 3 "100_Prozent" ;
VAL_ 1016 HLR_FlHz_Freigabe_VR 0 "0_Prozent" 1 "33_Prozent" 2 "66_Prozent" 3 "100_Prozent" ;
VAL_ 1016 HLR_FlHz_Freigabe_VL 0 "0_Prozent" 1 "33_Prozent" 2 "66_Prozent" 3 "100_Prozent" ;
VAL_ 1016 HLR_FlHz_Freigabe_HR 0 "0_Prozent" 1 "33_Prozent" 2 "66_Prozent" 3 "100_Prozent" ;
VAL_ 1016 HLR_FlHz_Freigabe_HL 0 "0_Prozent" 1 "33_Prozent" 2 "66_Prozent" 3 "100_Prozent" ;
VAL_ 1016 HLR_TCH_Freigabe 0 "keine_Freigabe" 1 "Freigabe" ;
VAL_ 1016 HLR_SIH_Freigabe_Fond 0 "keine_Freigabe" 1 "Freigabe" ;
VAL_ 1016 HLR_Sp_Heizung_Freigabe_BT 0 "keine_Freigabe" 1 "Freigabe" ;
VAL_ 1016 HLR_Sp_Heizung_Freigabe_FT 0 "keine_Freigabe" 1 "Freigabe" ;
VAL_ 1016 HLR_KRH_Freigabe_VL 0 "0_Prozent" 1 "33_Prozent" 2 "66_Prozent" 3 "100_Prozent" ;
VAL_ 1016 HLR_KRH_Freigabe_VR 0 "0_Prozent" 1 "33_Prozent" 2 "66_Prozent" 3 "100_Prozent" ;
VAL_ 1016 HLR_SIH_Freigabe_VL 0 "0_Prozent" 1 "33_Prozent" 2 "66_Prozent" 3 "100_Prozent" ;
VAL_ 1016 HLR_SIH_Freigabe_VR 0 "0_Prozent" 1 "33_Prozent" 2 "66_Prozent" 3 "100_Prozent" ;
VAL_ 1016 HLR_SIH_Freigabe_HL 0 "0_Prozent" 1 "33_Prozent" 2 "66_Prozent" 3 "100_Prozent" ;
VAL_ 1016 HLR_SIH_Freigabe_HR 0 "0_Prozent" 1 "33_Prozent" 2 "66_Prozent" 3 "100_Prozent" ;
VAL_ 1016 HLR_SIL_Freigabe_VL 0 "0_Prozent" 1 "33_Prozent" 2 "66_Prozent" 3 "100_Prozent" ;
VAL_ 1016 HLR_SIL_Freigabe_VR 0 "0_Prozent" 1 "33_Prozent" 2 "66_Prozent" 3 "100_Prozent" ;
VAL_ 1016 HLR_SIL_Freigabe_HL 0 "0_Prozent" 1 "33_Prozent" 2 "66_Prozent" 3 "100_Prozent" ;
VAL_ 1016 HLR_SIL_Freigabe_HR 0 "0_Prozent" 1 "33_Prozent" 2 "66_Prozent" 3 "100_Prozent" ;
VAL_ 1016 HLR_FSH_Freigabe 0 "AUS" 63 "Fehler" ;
VAL_ 1016 HLR_HSH_Freigabe 0 "keine_Freigabe" 1 "Freigabe" ;
VAL_ 1016 HLR_LRH_Freigabe 0 "keine_Freigabe" 1 "Freigabe" ;
VAL_ 1016 HLR_PTC_linear_Freigabe 63 "Fehler" ;
VAL_ 1016 HLR_PTC_Freigabe 0 "Aus" 1 "Stufe_1" 2 "Stufe_2" 3 "Stufe_3" ;
VAL_ 1283 HVK_Istmodus_Anf 0 "nicht_angefordert" 1 "angefordert" ;
VAL_ 1283 HVK_TN1_Sollmodus 0 "HV_Off" 1 "HV_On" 2 "reserviert" 3 "Initialisierung" ;
VAL_ 1283 HVK_MO_EmSollzustand 0 "HvOff" 1 "HvStbyReq" 2 "HvStbyWait" 3 "HvBattOnReq" 4 "HvBattOnWait" 10 "HvOnIdle" 18 "HvOnDrvReq" 19 "HvOnDrvWait" 20 "HvOnDrvRdy" 28 "HvStepUpReq" 29 "HvStepUpWait" 30 "HvStepUp" 38 "HvStepDownReq" 39 "HvStepDownWait" 40 "HvStepDown" 46 "HvAcChPreReq" 47 "HvAcChPreWait" 48 "HvAcChReq" 49 "HvAcChWait" 50 "HvAcCh" 56 "HvDcChPreReq" 57 "HvDcChPreWait" 58 "HvDcChReq" 59 "HvDcChWait" 60 "HvDcCh" 67 "HvChOffReq" 68 "HvChOffWait" 69 "HvOnIdleReq" 70 "HvOnIdleWait" 96 "HvCpntOffReq" 97 "HvCpntOffWait" 98 "HvBattOffReq" 99 "HvBattOffWait" 109 "HvDcDcFailOffReq" 110 "HvDcDcFail" 119 "HvElmOffReq" 120 "HvElmOff" 126 "HvFailCpntOffReq" 127 "HvFailCpntOffWait" 128 "HvFailBattOffReq" 129 "HvFailBattOffWait" 130 "HvFailBattOff" 138 "HvFailUCtlReq" 139 "HvFailUCtlWait" 140 "HvFailUCtl" 150 "HvEmgcyOff" 255 "Init" ;
VAL_ 1283 HVK_BMS_Sollmodus 0 "HV_Off" 1 "HV_On" 3 "AC_Laden_erw" 4 "AC_Laden" 6 "DC_Laden" 7 "Init" ;
VAL_ 1283 HVK_DCDC_Sollmodus 0 "Standby" 1 "HV_On_Vorladen" 2 "Tiefsetzen" 3 "Hochsetzen" 4 "Pruefpuls_12V" 7 "Initialisierung" ;
VAL_ 1283 HVK_EKK_Sollmodus 0 "Keine_Freigabe" 1 "Freigabe" 7 "Init" ;
VAL_ 1283 HVK_HVPTC_Sollmodus 0 "Keine_Freigabe" 1 "Freigabe" 7 "Init" ;
VAL_ 1283 HVK_HVLM_Sollmodus 0 "keine_Freigabe" 1 "Freigabe_Lademanager" 7 "Init" ;
VAL_ 1283 HVK_HV_Netz_Warnungen 0 "Keine_Warnung" 1 "Warntext_HV_Netz_Anf" 2 "Fehlertext_HV_Netz_Anf" 3 "Warnung_Kein_Wiederstart_moeglich" ;
VAL_ 1283 HV_Bordnetz_aktiv 0 "inaktiv" 1 "aktiv" ;
VAL_ 1283 HV_Bordnetz_Fehler 0 "kein_Fehler" 1 "Fehler" ;
VAL_ 1283 HVK_Gesamtst_Spgfreiheit 0 "Funktion_Init__ohne_Funktion" 1 "HV_System_spannungsfrei" 2 "HV_System_nicht_spannungsfrei" 3 "Fehler" ;
VAL_ 1283 HVK_AktiveEntladung_Anf 0 "nicht_angefordert" 1 "angefordert" ;
VAL_ 1381 HVLM_HV_Abstellzeit 254 "Init" 255 "Fehler" ;
VAL_ 1381 HVLM_Ladesystemhinweise 0 "kein_Hinweis" 1 "Ladesystem_defekt" 2 "Ladesaeule_inkompatibel" 3 "DC_Laden_nicht_moeglich" ;
VAL_ 1381 HVLM_Schluessel_Anfrage 0 "Keine_Anfrage_Init" 1 "Suchanfrage_LKL_1_aktiv" 2 "Suchanfrage_LKL_2_aktiv" 3 "Reserve" ;
VAL_ 1381 HVLM_Zustand_LED 0 "Farbe_1__aus" 1 "Farbe_2__weiss" 2 "Farbe_3__gelb" 3 "Farbe_4__gruen" 4 "Farbe_5__rot" 5 "Farbe_3_pulsierend" 6 "Farbe_4_pulsierend" 7 "Farbe_5_pulsierend" 8 "Farbe_4_5_pulsierend" 9 "Farbe_4__gruen_blinkend" 14 "Init" 15 "Fehler" ;
VAL_ 1381 HVLM_MaxStrom_Netz 126 "Init" 127 "Fehler" ;
VAL_ 1381 HVLM_LG_Sollmodus 0 "Standby" 1 "Netzladung" ;
VAL_ 1381 HVLM_FreigabeTankdeckel 0 "keine_Freigabe" 1 "Freigabe" 2 "Init" 3 "Fehler" ;
VAL_ 1381 HVLM_Stecker_Verriegeln 0 "Stecker_entriegeln" 1 "Stecker_verriegeln" 2 "Init" 3 "keine_Anforderung" ;
VAL_ 1381 HVLM_Start_Spannungsmessung_DCLS 0 "inaktiv" 1 "DCLS_mit_Diode_Start_Messung" 2 "DCLS_ohne_Diode_Start_Messung" 3 "reserve" ;
VAL_ 1381 HVLM_FreigabeKlimatisierung 0 "keine_Freigabe" 1 "Freigabe" 2 "Init" 3 "Fehler" ;
VAL_ 1381 HVLM_Ladetexte 0 "Keine_Anzeige" 1 "AC_Laden_nicht_moeglich" 2 "DC_Laden_nicht_moeglich" 3 "AC_und_DC_Laden_nicht_moeglich" ;
VAL_ 1381 HVLM_IsoMessung_Anf 0 "Laden_mit_Isomessung" 1 "Laden_ohne_Isomessung" ;
VAL_ 1381 HVLM_IstSpannung_HV 1022 "Init" 1023 "Fehler" ;
VAL_ 1340 HVLM_STH_Betriebsmodus 0 "Keine_Klimatisierung" 1 "Heizen" 2 "Abtauen" 6 "Init" 7 "Fehler" ;
VAL_ 1340 HVLM_Standklima_Timer_Status 0 "Standklimatimer_nicht_aktiv" 1 "Standklimatimer_aktiv" ;
VAL_ 1340 HVLM_HVEM_MaxLeistung 510 "Init" 511 "Fehler" ;
VAL_ 1340 HVLM_Status_Netz 0 "Fzg_nicht_am_Netz" 1 "Fzg_ist_am_Stromnetz" ;
VAL_ 1340 HVLM_Ladeart 0 "keine_Auswahl" 1 "AC_Laden" 2 "DC_Laden" 3 "Konditionierung" ;
VAL_ 1340 HVLM_VK_STH_Einsatz 0 "Verbrennerstandheizung verbieten" 1 "Automatik (Verbrennerstandheizung erlauben)" 2 "Verbrennerstandheizung erzwingen" 3 "reserviert" 4 "reserviert" 5 "reserviert" 6 "Init" 7 "Fehler" ;
VAL_ 1340 HVLM_VK_Modus 0 "keine Vorkonditionierung" 1 "Sofort-Konditionierung" 2 "zeitversetzte Konditionierung" 3 "Fehler" ;
VAL_ 1340 HVLM_IstModus_02 0 "inaktiv" 1 "aktiv" 2 "Init" 3 "Fehler" ;
VAL_ 1340 HVLM_HV_Anf 0 "keine_Anforderung" 1 "Laden_angefordert" 2 "Batteriekonditionierung_angefordert" 3 "Standklimatisierung_angefordert" ;
VAL_ 1340 HVLM_Fehlerstatus 0 "Komponente_IO" 1 "Eingeschr_KompFkt_DC_Lad_NIO" 2 "Eingeschr_KompFkt_AC_Lad_NIO" 3 "Eingeschr_KompFkt_Interlock" 4 "Eingeschr_KompFkt_reserve" 5 "Eingeschr_KompFkt_reserve" 6 "Keine_Komponentenfunktion" 7 "Init" ;
VAL_ 1340 HVLM_Anforderung_HMS 0 "keine_Anforderung" 1 "halten" 2 "parken" 3 "halten_Standby" 4 "anfahren" 5 "Loesen_ueber_Rampe" ;
VAL_ 1340 HVLM_Parken_beibehalten_HMS 0 "Parken_nicht_beibehalten" 1 "Parken_beibehalten" 2 "Init" 3 "Fehler" ;
VAL_ 1340 HVLM_AWC_Sollmodus 0 "init" 1 "Inaktiv" 2 "Standby" 3 "AWCLaden" 4 "Reserve" 5 "Reserve" 6 "Reserve" 7 "Fehler" ;
VAL_ 1340 HVLM_Stecker_Status 0 "Init" 1 "kein_Stecker_gesteckt" 2 "Stecker_erkannt_nicht_verriegelt" 3 "Stecker_erkannt_und_verriegelt" ;
VAL_ 1340 HVLM_LadeAnforderung 0 "keine_Anforderung" 1 "AC_Laden" 2 "DC_Laden" 3 "Nachladen_12V" 4 "AC_Laden_AWC" 5 "Reserve" 6 "Init" 7 "Fehler" ;
VAL_ 1340 HVLM_MaxBatLadestromHV 254 "Init" 255 "Fehler" ;
VAL_ 2589283485 HVLM_BattKond_Anf 0 "keine_Anforderung" 1 "Anforderung_Heizstufe_1" 2 "Anforderung_Heizstufe_2" 6 "Init" 7 "Fehler" ;
VAL_ 2589283485 HVLM_Dauer_Klima_02 61 "default" 62 "Init" 63 "Fehler" ;
VAL_ 2463978610 HVLM_RtmWarnLadeverbindung 0 "kein_Fehler" 1 "Fehler_Stufe_1" 2 "Fehler_Stufe_2" 3 "Fehler_Stufe_3" 4 "reserviert" 5 "reserviert" 6 "reserviert" 7 "reserviert" ;
VAL_ 2463978610 HVLM_RtmWarnLadesystem 0 "kein_Fehler" 1 "Fehler_Stufe_1" 2 "Fehler_Stufe_2" 3 "Fehler_Stufe_3" 4 "reserviert" 5 "reserviert" 6 "reserviert" 7 "reserviert" ;
VAL_ 2463978610 HVLM_RtmWarnLadestatus 0 "kein_Fehler" 1 "Fehler_Stufe_1" 2 "Fehler_Stufe_2" 3 "Fehler_Stufe_3" 4 "reserviert" 5 "reserviert" 6 "reserviert" 7 "reserviert" ;
VAL_ 2463978610 HVLM_RtmWarnLadeKommunikation 0 "kein_Fehler" 1 "Fehler_Stufe_1" 2 "Fehler_Stufe_2" 3 "Fehler_Stufe_3" 4 "reserviert" 5 "reserviert" 6 "reserviert" 7 "reserviert" ;
VAL_ 2463978610 HVLM_Ladeanzeige_Anf 0 "Licht_Aus" 1 "Licht_An" ;
VAL_ 2463978610 HVLM_Ladeanzeige_Status 0 "Funktion_Aus" 1 "Funktion_Ein_ohne_SOC" 2 "Funktion_Ein_mit_SOC" 3 "Reserve" ;
VAL_ 2463978610 HVLM_Ladeanzeige_Intens_Heck 126 "Init" 127 "Fehler" ;
VAL_ 2463978610 HVLM_Ladeanzeige_Intens_Front 126 "Init" 127 "Fehler" ;
VAL_ 1524 IL_Bel_FS_Ausstieg 0 "inaktiv" 1 "aktiv" ;
VAL_ 1524 IL_Bel_BFS_Ausstieg 0 "inaktiv" 1 "aktiv" ;
VAL_ 1524 IL_Bel_HFS_Ausstieg 0 "inaktiv" 1 "aktiv" ;
VAL_ 1524 IL_Bel_HBFS_Ausstieg 0 "inaktiv" 1 "aktiv" ;
VAL_ 1524 BCM1_Innenlicht_gedimmt_V 0 "100% Innenlicht" 1 "gedimmtes Innenlicht" ;
VAL_ 1524 BCM1_Innenlicht_gedimmt_H 0 "100% Innenlicht" 1 "gedimmtes Innenlicht" ;
VAL_ 1524 IL_Innenlicht_aktiv 0 "Innenlicht inaktiv" 1 "Innenlicht aktiv" ;
VAL_ 1524 IL_Klemme_30G_aktiv 0 "Kl 30G abgeschaltet" 1 "eingeschaltet" ;
VAL_ 1524 BCM1_DI_Rampe_Innenlicht 0 "Dimmrampe 0" 1 "Dimmrampe 1" ;
VAL_ 1524 BCM1_DI_Rampe_Leselicht 0 "Dimmrampe 0" 1 "Dimmrampe 1" ;
VAL_ 1524 BCM1_Innenlicht_H 0 "Aus" 1 "Ein" ;
VAL_ 1524 BCM1_Innenlicht_V 0 "Aus" 1 "Ein" ;
VAL_ 1524 BCM1_Leselicht_Anf_hl 0 "Aus" 1 "Ein" ;
VAL_ 1524 BCM1_Leselicht_Anf_hr 0 "Aus" 1 "Ein" ;
VAL_ 1524 BCM1_Leselicht_Anf_vl 0 "Aus" 1 "Ein" ;
VAL_ 1524 BCM1_Leselicht_Anf_vr 0 "Aus" 1 "Ein" ;
VAL_ 1524 BCM1_Leuchten_Aus 0 "keine Aenderung" 1 "Aus" ;
VAL_ 1524 AMB_Charisma_FahrPr 0 "keine_Funktion" 1 "Programm_1" 2 "Programm_2" 3 "Programm_3" 4 "Programm_4" 5 "Programm_5" 6 "Programm_6" 7 "Programm_7" 8 "Programm_8" 9 "Programm_9" 10 "Programm_10" 11 "Programm_11" 12 "Programm_12" 13 "Programm_13" 14 "Programm_14" 15 "Programm_15" ;
VAL_ 1524 AMB_Charisma_Status 0 "Init" 1 "verfuegbar" 2 "nicht_verfuegbar" 3 "asynchron_durch_Fahrerwunsch" ;
VAL_ 312 IPA_Anforderung_HMS 0 "keine_Anforderung" 1 "halten" 2 "parken" 3 "halten_Standby" 4 "anfahren" 5 "Loesen_ueber_Rampe" 6 "Parken_mit_P" ;
VAL_ 312 Parken_aktives_System 0 "kein_aktives_System" 1 "Manoevrierassistent_Ueberwachung" 2 "IPA" 3 "fernbedientes_Parken" 4 "Manoevrierassistent" 5 "Manoevrierassistent_quer" 6 "Anhaengerrangierassistent" 7 "fernbedienter_Anhaengerrangierassistent" ;
VAL_ 312 Parken_erhoehtes_Moment 0 "keine_Anforderung" 1 "Anforderung_Rampe1" 2 "Anforderung_Rampe2" 3 "Anforderung_Rampe3" 4 "Anforderung_Rampe4" 5 "Anforderung_Rampe5" 6 "Anforderung_Rampe6" 7 "Anforderung_Rampe7" 8 "Anforderung_Rampe8" 9 "Anforderung_Rampe9" 10 "Anforderung_Rampe10" 11 "Anforderung_Rampe11" 12 "Anforderung_Rampe12" 13 "Anforderung_Rampe13" 14 "Anforderung_Rampe14" 15 "Anforderung_Rampe15" ;
VAL_ 312 Parken_Motorlauf_Anf 0 "Keine_Anforderung" 1 "Motor_aus" 2 "Motor_an" 3 "Weiterlauf_Fahreruebernahme" ;
VAL_ 312 IPA_Fahrstufenwunsch 0 "Init" 1 "Fahrstufe_beibehalten" 2 "Position_R" 3 "Position_D" 4 "Position_N" ;
VAL_ 312 IPA_Status 0 "Init" 4 "IPA_Anzeige_Aktiv" 5 "IPA_Fahreruebernahme" 6 "IPA_Aktiv" 7 "IPA_Standby" 8 "IPA_Funktionsbereit" 9 "IPA_PP_Aktivierung" 10 "IPA_Abbruch" 11 "IPA_Aktivierend" 15 "IPA_PP_Start" ;
VAL_ 312 IPA_Status_IPA_GE 0 "Init" 1 "Neustart" 2 "Funktionsbereit" 3 "Aktiv" 7 "Fehler" ;
VAL_ 312 IPA_Status_IPA_TSK 1 "IPA_TSK_Init" 2 "IPA_TSK_Fehler" 4 "IPA_TSK_aktivierbar" 5 "IPA_TSK_pausiert" 6 "IPA_TSK_aktiv" 8 "IPA_TSK_funktionsbereit" ;
VAL_ 312 IPA_Sollbeschleunigung 0 "Neutralwert" ;
VAL_ 312 Parken_Fahrbereitschaft_Anf 0 "keine_Anforderung" 1 "Anforderung_Fahrbereitschaft" ;
VAL_ 312 IPA_Parken_beibehalten_HMS 0 "Parken_nicht_beibehalten" 1 "Parken_beibehalten" 2 "Init" 3 "Fehler" ;
VAL_ 312 IPA_PLA_LED 0 "LED_aus" 1 "LED_ein" 2 "LED_blinken" 3 "Funktion_gesperrt__LED_aus" 6 "Init" ;
VAL_ 312 IPA_APS_LED 0 "LED_aus" 1 "LED_ein" 2 "LED_blinken" 3 "Funktion_gesperrt__LED_aus" 6 "Init" ;
VAL_ 2527679583 Parken_Seitenspiegel_Anf 0 "Keine_Anforderung" 1 "Seitenspiegel_anklappen" 2 "Seitenspiegel_abklappen" ;
VAL_ 2527679583 Parken_ZV_Schliessen 0 "Keine_Anforderung" 1 "ZV_verriegeln" 2 "ZV_safen" ;
VAL_ 2527679583 Parken_ZR_Sondermodus_Anf 0 "Init" 1 "Keine_Anforderung" 2 "Anforderung_Sondermodus" ;
VAL_ 2527679583 Parken_Schluesselsuche_Anf 0 "keine_Anforderung" 1 "Anforderung_Schluesselsuche" ;
VAL_ 2527679583 Parken_FFB_LED_Anf 0 "keine_Anforderung" 1 "Abbruch_Fehler" 2 "Bereit_OK" 3 "Beendet" ;
VAL_ 2527679583 Parken_Wegfahrsperren_Anf 0 "keine_Anforderung" 1 "Anforderung_Fahreruebernahme" 2 "Anforderung_Fahreruebergabe" ;
VAL_ 2527679583 Parken_Aktivierungslicht_Anf 0 "keine_Anforderung" 1 "Aktivierungslicht" ;
VAL_ 2527679583 Parken_Fahrtrichtungslicht_Anf 0 "keine_Anforderung" 1 "Vorwaerts" 2 "Rueckwaerts" ;
VAL_ 2527679583 Parken_Lichtnachlauf_Anf 0 "keine_Anforderung" 1 "Anforderung_Lichtnachlauf" ;
VAL_ 2527679583 Parken_Fahrerhinweise_Anf 0 "keine_Anforderung" 1 "Fahrerhinweise_anzeigen" ;
VAL_ 2527679583 Parken_Bestaetigungsblinken_Anf 0 "keine_Anforderung" 1 "Erfolgsblinken_Einparken" 2 "Abbruchsblinken" 3 "Erfolgsblinken_Ausparken" ;
VAL_ 2527679583 Parken_Fahrbereitschaftlicht_Anf 0 "keine_Anforderung" 1 "Fahrbereitschaftslicht" ;
VAL_ 2463978614 KAS_Verfuegbarkeit 0 "Init" 1 "verfuegbar" 2 "nicht_verfuegbar" ;
VAL_ 2463978614 KAS_Kritikalitaetslevel 0 "unkritisch" 1 "Kritikalitaetslevel_1" 2 "Kritikalitaetslevel_2" 3 "Kritikalitaetslevel_3" 4 "Kritikalitaetslevel_4" 5 "Kritikalitaetslevel_5" 6 "reserviert" 7 "nicht_bewertbar" ;
VAL_ 2463978614 KAS_Anf_OPS 0 "Aus" 1 "An" ;
VAL_ 2463978614 KAS_PreSense_Modus_System 0 "deaktiviert" 1 "aktiviert" ;
VAL_ 2463978614 KAS_Status 0 "Init" 1 "Nicht_verfuegbar" 2 "Deaktiviert" 3 "Aktiv" 4 "Passiv" 5 "Blindheit" 6 "Fehler" 7 "reserviert" ;
VAL_ 2463978614 KAS_Anzeige_Info_links 0 "Keine_Anzeige" 1 "Info" 2 "Info_kritisch" ;
VAL_ 2463978614 KAS_Anzeige_Info_rechts 0 "Keine_Anzeige" 1 "Info" 2 "Info_kritisch" ;
VAL_ 2463978614 KAS_Anzeige_Warnung 0 "keine_Anzeige" 1 "Warnung_links" 2 "Warnung_rechts" 3 "Warnung_beidseitig" 4 "Bremsung" ;
VAL_ 2463978614 KAS_Texte 0 "keine_Anzeige" 1 "Stoerung_Bitte_Service_aufsuchen" 2 "Zurzeit_nicht_verfuegbar" 3 "Sensorsicht_umgebungsbedingt_eingeschraenkt" 4 "Eingeschraenkt_Stabilisierungskontrolle_ESC_ausgeschaltet" 5 "In_aktuellem_Audi_drive_select_modus_eingeschraenkt" 6 "Bremsung_erfolgt_Hindernis_erkannt_Bitte_uebernehmen" 7 "Bitte_uebernehmen" ;
VAL_ 2463978614 KAS_Anf_Prefill 0 "Prefill_nicht_angefordert" 1 "Prefill_angefordert" ;
VAL_ 2463978614 KAS_Anf_Bremsruck 0 "keine_Ruckanforderung" 1 "Bremsruck_Profil_01_angefordert" 2 "Bremsruck_Profil_02_angefordert" 3 "Bremsruck_Profil_03_angefordert" 4 "Bremsruck_Profil_04_angefordert" 5 "Bremsruck_Profil_05_angefordert" 6 "Bremsruck_Profil_06_angefordert" 7 "Bremsruck_Profil_07_angefordert" ;
VAL_ 2463978614 KAS_Verz_Anf 254 "Init" 255 "Fehler" ;
VAL_ 497 KY_IDG_in_Reichweite 0 "ausser_Reichweite_bzw_nicht_ermittelbar" 1 "innerhalb_Reichweite" ;
VAL_ 497 KY_Auf_Taste 0 "Taste_nicht_betaetigt" 1 "Oeffnentaste_betaetigt" ;
VAL_ 497 KY_HDF_Taste 0 "Taste_nicht_betaetigt" 1 "HDF_Taste_am_Funkschluessel_betaetigt" ;
VAL_ 497 KY_Panik_Taste 0 "Taste_nicht_betaetigt" 1 "Panik_Taste_am_Funkschluessel_betaetigt" ;
VAL_ 497 KY_Zu_Taste 0 "Taste_nicht_betaetigt" 1 "Zu_Taste_am_Funkschluessel_betaetigt" ;
VAL_ 497 KY_FT_Entriegelung_Autorisiert 0 "kein_Keylessschluessel_erkannt" 1 "Keyless_Schluessel_erkannt_und_authorisiert" ;
VAL_ 497 KY_FT_Verriegelung_Autorisiert 0 "kein_Verriegelungssensor_erkannt" 1 "Verriegelungssensor_erkannt_und_authorisiert" ;
VAL_ 497 KY_BT_Entriegelung_Autorisiert 0 "kein_Keylessschluessel_erkannt" 1 "Keyless_Schluessel_erkannt_und_authorisiert" ;
VAL_ 497 KY_BT_Verriegelung_Autorisiert 0 "kein_Verriegelungssensor_erkannt" 1 "Verriegelungssensor_erkannt_und_authorisiert" ;
VAL_ 497 KY_HFS_Entriegelung_Autorisiert 0 "kein_Keylessschluessel_erkannt" 1 "Keyless_Schluessel_erkannt_und_authorisiert" ;
VAL_ 497 KY_HFS_Verriegelung_Autorisiert 0 "kein_Verriegelungssensor_erkannt" 1 "Verriegelungssensor_erkannt_und_authorisiert" ;
VAL_ 497 KY_HBFS_Entriegelung_Autorisiert 0 "kein_Keylessschluessel_erkannt" 1 "Keyless_Schluessel_erkannt_und_authorisiert" ;
VAL_ 497 KY_HBFS_Verriegelung_Autorisiert 0 "kein_Verriegelungssensor_erkannt" 1 "Verriegelungssensor_erkannt_und_authorisiert" ;
VAL_ 497 KY_Front_Entr_Autorisiert 0 "kein_Keylessschluessel_erkannt" 1 "Keyless_Schluessel_erkannt_und_authorisiert" ;
VAL_ 497 KY_Front_Verr_Autorisiert 0 "kein_Verriegelungssensor_erkannt" 1 "Verriegelungssensor_erkannt_und_authorisiert" ;
VAL_ 497 KY_HD_Entriegelung_Autorisiert 0 "kein_Keylessschluessel_erkannt" 1 "Keyless_Schluessel_erkannt_und_authorisiert" ;
VAL_ 497 KY_HD_Verriegelung_Autorisiert 0 "nicht_autorisiert" 1 "autorisiert" ;
VAL_ 497 KY_Bereich 0 "Bereich_0" 1 "Bereich_1" 2 "Bereich_2" 3 "Bereich_3" 4 "Bereich_4" 5 "Bereich_5" 6 "Kein_Schluessel_gefunden" 7 "Init" ;
VAL_ 497 KY_Position 0 "Position_0" 1 "Postition_1" 2 "Postition_2" 3 "Postition_3" 4 "Postition_4" 6 "Kein_Schluessel_gefunden" 7 "Init" ;
VAL_ 497 Schluesselnr_Personalisierung 1 "Schluesselnummer_eins_aktiv" 2 "Schluesselnummer_zwei_aktiv" 3 "Schluesselnummer_drei_aktiv" 4 "Schluesselnummer_vier_aktiv" 5 "Schluesselnummer_fuenf_aktiv" 6 "Schluesselnummer_sechs_aktiv" 7 "Schluesselnummer_sieben_aktiv" 8 "Schluesselnummer_acht_aktiv" 14 "Init" 15 "Fehler" ;
VAL_ 497 FFB_FDF_Taste 0 "Taste_nicht_betaetigt" 1 "FDF_Taste_am_Funkschluessel_betaetigt" ;
VAL_ 497 FFB_Joker_Taste 0 "Taste_nicht_betaetigt" 1 "Joker_Taste_an_FFFB_betaetigt" ;
VAL_ 497 FFB_Park_Taste 0 "Taste_nicht_betaetigt" 1 "Park_Taste_betaetigt" ;
VAL_ 497 FFB_Remotestart_Taste 0 "Taste_nicht_betaetigt" 1 "Remotestart_Taste_betaetigt" ;
VAL_ 497 FBS_Aktivierung_Pilot_Parken 0 "keine_Funktionsaktivierung" 1 "Aktivierung_FFB_erkannt" ;
VAL_ 497 KY_Schluessel_im_Fzg 0 "Schluessel_nicht_im_Fahrzeug" 1 "Schluessel_im_Fahrzeug" ;
VAL_ 497 KY_EasyClose_Abbruch 0 "EasyClose_kein_Abbruch" 1 "EasyClose_Abbruch" ;
VAL_ 497 KY_EasyClose_Status 0 "Lampe_AUS" 1 "Lampe_EIN" 2 "Lampe_NORMAL" 3 "Lampe_HEKTIK" 4 "Akustik_Verweigerung" ;
VAL_ 497 KY_HD_Auffahrt 0 "keine_Anforderung" 1 "HD_Auffahrt_angefordert" ;
VAL_ 497 KY_HD_Zufahrt 0 "keine_Anforderung" 1 "HD_Zufahrt_angefordert" ;
VAL_ 497 KY_LKL_1_Autorisierung 0 "Kein_Zugang_LKL_1_erkannt" 1 "Zugang_LKL_1_erkannt" ;
VAL_ 497 KY_LKL_2_Autorisierung 0 "Kein_Zugang_LKL_2_erkannt" 1 "Zugang_LKL_2_erkannt" ;
